VERSION ""

NS_ :

BS_:
BU_: ME SC01 BMS01 BMS PT
BO_ 2005 BMS22_DebugCMB: 8 BMS22
 SG_ cmbMultiplexor_BMS22 M : 7|8@0+ (1,0) [0|0] ""  PT
 SG_ moduleTemperature01_BMS22 m1 : 15|8@0+ (1,-40) [-40|200] "C"  PT
 SG_ brickVoltage001_BMS22 m1 : 23|16@0+ (0.0001,0) [0|6.5] "V"  PT
 SG_ brickVoltage002_BMS22 m1 : 39|16@0+ (0.0001,0) [0|6.5] "V"  PT
 SG_ brickVoltage003_BMS22 m1 : 55|16@0+ (0.0001,0) [0|6.5] "V"  PT
 SG_ moduleTemperature02_BMS22 m2 : 15|8@0+ (1,-40) [-40|200] "C"  PT
 SG_ brickVoltage004_BMS22 m2 : 23|16@0+ (0.0001,0) [0|6.5] "V"  PT
 SG_ brickVoltage005_BMS22 m2 : 39|16@0+ (0.0001,0) [0|6.5] "V"  PT
 SG_ brickVoltage006_BMS22 m2 : 55|16@0+ (0.0001,0) [0|6.5] "V"  PT
 SG_ moduleTemperature03_BMS22 m3 : 15|8@0+ (1,-40) [-40|200] "C"  PT
 SG_ brickVoltage007_BMS22 m3 : 23|16@0+ (0.0001,0) [0|6.5] "V"  PT
 SG_ brickVoltage008_BMS22 m3 : 39|16@0+ (0.0001,0) [0|6.5] "V"  PT
 SG_ brickVoltage009_BMS22 m3 : 55|16@0+ (0.0001,0) [0|6.5] "V"  PT
 SG_ moduleTemperature04_BMS22 m4 : 15|8@0+ (1,-40) [-40|200] "C"  PT
 SG_ brickVoltage010_BMS22 m4 : 23|16@0+ (0.0001,0) [0|6.5] "V"  PT
 SG_ brickVoltage011_BMS22 m4 : 39|16@0+ (0.0001,0) [0|6.5] "V"  PT
 SG_ brickVoltage012_BMS22 m4 : 55|16@0+ (0.0001,0) [0|6.5] "V"  PT
 SG_ moduleTemperature05_BMS22 m5 : 15|8@0+ (1,-40) [-40|200] "C"  PT
 SG_ brickVoltage013_BMS22 m5 : 23|16@0+ (0.0001,0) [0|6.5] "V"  PT
 SG_ brickVoltage014_BMS22 m5 : 39|16@0+ (0.0001,0) [0|6.5] "V"  PT
 SG_ brickVoltage015_BMS22 m5 : 55|16@0+ (0.0001,0) [0|6.5] "V"  PT
 SG_ moduleTemperature06_BMS22 m6 : 15|8@0+ (1,-40) [-40|200] "C"  PT
 SG_ brickVoltage016_BMS22 m6 : 23|16@0+ (0.0001,0) [0|6.5] "V"  PT
 SG_ brickVoltage017_BMS22 m6 : 39|16@0+ (0.0001,0) [0|6.5] "V"  PT
 SG_ brickVoltage018_BMS22 m6 : 55|16@0+ (0.0001,0) [0|6.5] "V"  PT
 SG_ moduleTemperature07_BMS22 m7 : 15|8@0+ (1,-40) [-40|200] "C"  PT
 SG_ brickVoltage019_BMS22 m7 : 23|16@0+ (0.0001,0) [0|6.5] "V"  PT
 SG_ brickVoltage020_BMS22 m7 : 39|16@0+ (0.0001,0) [0|6.5] "V"  PT
 SG_ brickVoltage021_BMS22 m7 : 55|16@0+ (0.0001,0) [0|6.5] "V"  PT
 SG_ moduleTemperature08_BMS22 m8 : 15|8@0+ (1,-40) [-40|200] "C"  PT
 SG_ brickVoltage022_BMS22 m8 : 23|16@0+ (0.0001,0) [0|6.5] "V"  PT
 SG_ brickVoltage023_BMS22 m8 : 39|16@0+ (0.0001,0) [0|6.5] "V"  PT
 SG_ brickVoltage024_BMS22 m8 : 55|16@0+ (0.0001,0) [0|6.5] "V"  PT
 SG_ moduleTemperature09_BMS22 m9 : 15|8@0+ (1,-40) [-40|200] "C"  PT
 SG_ brickVoltage025_BMS22 m9 : 23|16@0+ (0.0001,0) [0|6.5] "V"  PT
 SG_ brickVoltage026_BMS22 m9 : 39|16@0+ (0.0001,0) [0|6.5] "V"  PT
 SG_ brickVoltage027_BMS22 m9 : 55|16@0+ (0.0001,0) [0|6.5] "V"  PT
 SG_ moduleTemperature10_BMS22 m10 : 15|8@0+ (1,-40) [-40|200] "C"  PT
 SG_ brickVoltage028_BMS22 m10 : 23|16@0+ (0.0001,0) [0|6.5] "V"  PT
 SG_ brickVoltage029_BMS22 m10 : 39|16@0+ (0.0001,0) [0|6.5] "V"  PT
 SG_ brickVoltage030_BMS22 m10 : 55|16@0+ (0.0001,0) [0|6.5] "V"  PT
 SG_ moduleTemperature11_BMS22 m11 : 15|8@0+ (1,-40) [-40|200] "C"  PT
 SG_ brickVoltage031_BMS22 m11 : 23|16@0+ (0.0001,0) [0|6.5] "V"  PT
 SG_ brickVoltage032_BMS22 m11 : 39|16@0+ (0.0001,0) [0|6.5] "V"  PT
 SG_ brickVoltage033_BMS22 m11 : 55|16@0+ (0.0001,0) [0|6.5] "V"  PT
 SG_ moduleTemperature12_BMS22 m12 : 15|8@0+ (1,-40) [-40|200] "C"  PT
 SG_ brickVoltage034_BMS22 m12 : 23|16@0+ (0.0001,0) [0|6.5] "V"  PT
 SG_ brickVoltage035_BMS22 m12 : 39|16@0+ (0.0001,0) [0|6.5] "V"  PT
 SG_ brickVoltage036_BMS22 m12 : 55|16@0+ (0.0001,0) [0|6.5] "V"  PT
 SG_ moduleTemperature13_BMS22 m13 : 15|8@0+ (1,-40) [-40|200] "C"  PT
 SG_ brickVoltage037_BMS22 m13 : 23|16@0+ (0.0001,0) [0|6.5] "V"  PT
 SG_ brickVoltage038_BMS22 m13 : 39|16@0+ (0.0001,0) [0|6.5] "V"  PT
 SG_ brickVoltage039_BMS22 m13 : 55|16@0+ (0.0001,0) [0|6.5] "V"  PT
 SG_ moduleTemperature14_BMS22 m14 : 15|8@0+ (1,-40) [-40|200] "C"  PT
 SG_ brickVoltage040_BMS22 m14 : 23|16@0+ (0.0001,0) [0|6.5] "V"  PT
 SG_ brickVoltage041_BMS22 m14 : 39|16@0+ (0.0001,0) [0|6.5] "V"  PT
 SG_ brickVoltage042_BMS22 m14 : 55|16@0+ (0.0001,0) [0|6.5] "V"  PT
 SG_ moduleTemperature15_BMS22 m15 : 15|8@0+ (1,-40) [-40|200] "C"  PT
 SG_ brickVoltage043_BMS22 m15 : 23|16@0+ (0.0001,0) [0|6.5] "V"  PT
 SG_ brickVoltage044_BMS22 m15 : 39|16@0+ (0.0001,0) [0|6.5] "V"  PT
 SG_ brickVoltage045_BMS22 m15 : 55|16@0+ (0.0001,0) [0|6.5] "V"  PT
 SG_ moduleTemperature16_BMS22 m16 : 15|8@0+ (1,-40) [-40|200] "C"  PT
 SG_ brickVoltage046_BMS22 m16 : 23|16@0+ (0.0001,0) [0|6.5] "V"  PT
 SG_ brickVoltage047_BMS22 m16 : 39|16@0+ (0.0001,0) [0|6.5] "V"  PT
 SG_ brickVoltage048_BMS22 m16 : 55|16@0+ (0.0001,0) [0|6.5] "V"  PT
 SG_ moduleTemperature17_BMS22 m17 : 15|8@0+ (1,-40) [-40|200] "C"  PT
 SG_ brickVoltage049_BMS22 m17 : 23|16@0+ (0.0001,0) [0|6.5] "V"  PT
 SG_ brickVoltage050_BMS22 m17 : 39|16@0+ (0.0001,0) [0|6.5] "V"  PT
 SG_ brickVoltage051_BMS22 m17 : 55|16@0+ (0.0001,0) [0|6.5] "V"  PT
 SG_ moduleTemperature18_BMS22 m18 : 15|8@0+ (1,-40) [-40|200] "C"  PT
 SG_ brickVoltage052_BMS22 m18 : 23|16@0+ (0.0001,0) [0|6.5] "V"  PT
 SG_ brickVoltage053_BMS22 m18 : 39|16@0+ (0.0001,0) [0|6.5] "V"  PT
 SG_ brickVoltage054_BMS22 m18 : 55|16@0+ (0.0001,0) [0|6.5] "V"  PT
 SG_ moduleTemperature19_BMS22 m19 : 15|8@0+ (1,-40) [-40|200] "C"  PT
 SG_ brickVoltage055_BMS22 m19 : 23|16@0+ (0.0001,0) [0|6.5] "V"  PT
 SG_ brickVoltage056_BMS22 m19 : 39|16@0+ (0.0001,0) [0|6.5] "V"  PT
 SG_ brickVoltage057_BMS22 m19 : 55|16@0+ (0.0001,0) [0|6.5] "V"  PT
 SG_ moduleTemperature20_BMS22 m20 : 15|8@0+ (1,-40) [-40|200] "C"  PT
 SG_ brickVoltage058_BMS22 m20 : 23|16@0+ (0.0001,0) [0|6.5] "V"  PT
 SG_ brickVoltage059_BMS22 m20 : 39|16@0+ (0.0001,0) [0|6.5] "V"  PT
 SG_ brickVoltage060_BMS22 m20 : 55|16@0+ (0.0001,0) [0|6.5] "V"  PT
 SG_ moduleTemperature21_BMS22 m21 : 15|8@0+ (1,-40) [-40|200] "C"  PT
 SG_ brickVoltage061_BMS22 m21 : 23|16@0+ (0.0001,0) [0|6.5] "V"  PT
 SG_ brickVoltage062_BMS22 m21 : 39|16@0+ (0.0001,0) [0|6.5] "V"  PT
 SG_ brickVoltage063_BMS22 m21 : 55|16@0+ (0.0001,0) [0|6.5] "V"  PT
 SG_ moduleTemperature22_BMS22 m22 : 15|8@0+ (1,-40) [-40|200] "C"  PT
 SG_ brickVoltage064_BMS22 m22 : 23|16@0+ (0.0001,0) [0|6.5] "V"  PT
 SG_ brickVoltage065_BMS22 m22 : 39|16@0+ (0.0001,0) [0|6.5] "V"  PT
 SG_ brickVoltage066_BMS22 m22 : 55|16@0+ (0.0001,0) [0|6.5] "V"  PT
 SG_ moduleTemperature23_BMS22 m23 : 15|8@0+ (1,-40) [-40|200] "C"  PT
 SG_ brickVoltage067_BMS22 m23 : 23|16@0+ (0.0001,0) [0|6.5] "V"  PT
 SG_ brickVoltage068_BMS22 m23 : 39|16@0+ (0.0001,0) [0|6.5] "V"  PT
 SG_ brickVoltage069_BMS22 m23 : 55|16@0+ (0.0001,0) [0|6.5] "V"  PT
 SG_ moduleTemperature24_BMS22 m24 : 15|8@0+ (1,-40) [-40|200] "C"  PT
 SG_ brickVoltage070_BMS22 m24 : 23|16@0+ (0.0001,0) [0|6.5] "V"  PT
 SG_ brickVoltage071_BMS22 m24 : 39|16@0+ (0.0001,0) [0|6.5] "V"  PT
 SG_ brickVoltage072_BMS22 m24 : 55|16@0+ (0.0001,0) [0|6.5] "V"  PT
 SG_ moduleTemperature25_BMS22 m25 : 15|8@0+ (1,-40) [-40|200] "C"  PT
 SG_ brickVoltage073_BMS22 m25 : 23|16@0+ (0.0001,0) [0|6.5] "V"  PT
 SG_ brickVoltage074_BMS22 m25 : 39|16@0+ (0.0001,0) [0|6.5] "V"  PT
 SG_ brickVoltage075_BMS22 m25 : 55|16@0+ (0.0001,0) [0|6.5] "V"  PT
 SG_ moduleTemperature26_BMS22 m26 : 15|8@0+ (1,-40) [-40|200] "C"  PT
 SG_ brickVoltage076_BMS22 m26 : 23|16@0+ (0.0001,0) [0|6.5] "V"  PT
 SG_ brickVoltage077_BMS22 m26 : 39|16@0+ (0.0001,0) [0|6.5] "V"  PT
 SG_ brickVoltage078_BMS22 m26 : 55|16@0+ (0.0001,0) [0|6.5] "V"  PT
 SG_ moduleTemperature27_BMS22 m27 : 15|8@0+ (1,-40) [-40|200] "C"  PT
 SG_ brickVoltage079_BMS22 m27 : 23|16@0+ (0.0001,0) [0|6.5] "V"  PT
 SG_ brickVoltage080_BMS22 m27 : 39|16@0+ (0.0001,0) [0|6.5] "V"  PT
 SG_ brickVoltage081_BMS22 m27 : 55|16@0+ (0.0001,0) [0|6.5] "V"  PT
 SG_ moduleTemperature28_BMS22 m28 : 15|8@0+ (1,-40) [-40|200] "C"  PT
 SG_ brickVoltage082_BMS22 m28 : 23|16@0+ (0.0001,0) [0|6.5] "V"  PT
 SG_ brickVoltage083_BMS22 m28 : 39|16@0+ (0.0001,0) [0|6.5] "V"  PT
 SG_ brickVoltage084_BMS22 m28 : 55|16@0+ (0.0001,0) [0|6.5] "V"  PT
 SG_ moduleTemperature29_BMS22 m29 : 15|8@0+ (1,-40) [-40|200] "C"  PT
 SG_ brickVoltage085_BMS22 m29 : 23|16@0+ (0.0001,0) [0|6.5] "V"  PT
 SG_ brickVoltage086_BMS22 m29 : 39|16@0+ (0.0001,0) [0|6.5] "V"  PT
 SG_ brickVoltage087_BMS22 m29 : 55|16@0+ (0.0001,0) [0|6.5] "V"  PT
 SG_ moduleTemperature30_BMS22 m30 : 15|8@0+ (1,-40) [-40|200] "C"  PT
 SG_ brickVoltage088_BMS22 m30 : 23|16@0+ (0.0001,0) [0|6.5] "V"  PT
 SG_ brickVoltage089_BMS22 m30 : 39|16@0+ (0.0001,0) [0|6.5] "V"  PT
 SG_ brickVoltage090_BMS22 m30 : 55|16@0+ (0.0001,0) [0|6.5] "V"  PT
 SG_ moduleTemperature31_BMS22 m31 : 15|8@0+ (1,-40) [-40|200] "C"  PT
 SG_ brickVoltage091_BMS22 m31 : 23|16@0+ (0.0001,0) [0|6.5] "V"  PT
 SG_ brickVoltage092_BMS22 m31 : 39|16@0+ (0.0001,0) [0|6.5] "V"  PT
 SG_ brickVoltage093_BMS22 m31 : 55|16@0+ (0.0001,0) [0|6.5] "V"  PT
 SG_ moduleTemperature32_BMS22 m32 : 15|8@0+ (1,-40) [-40|200] "C"  PT
 SG_ brickVoltage094_BMS22 m32 : 23|16@0+ (0.0001,0) [0|6.5] "V"  PT
 SG_ brickVoltage095_BMS22 m32 : 39|16@0+ (0.0001,0) [0|6.5] "V"  PT
 SG_ brickVoltage096_BMS22 m32 : 55|16@0+ (0.0001,0) [0|6.5] "V"  PT
 SG_ brickVoltage097_BMS22 m33 : 23|16@0+ (0.0001,0) [0|6.5] "V"  PT
 SG_ brickVoltage098_BMS22 m33 : 39|16@0+ (0.0001,0) [0|6.5] "V"  PT
 SG_ brickVoltage099_BMS22 m33 : 55|16@0+ (0.0001,0) [0|6.5] "V"  PT
 SG_ brickVoltage100_BMS22 m34 : 23|16@0+ (0.0001,0) [0|6.5] "V"  PT
 SG_ brickVoltage101_BMS22 m34 : 39|16@0+ (0.0001,0) [0|6.5] "V"  PT
 SG_ brickVoltage102_BMS22 m34 : 55|16@0+ (0.0001,0) [0|6.5] "V"  PT
 SG_ brickVoltage103_BMS22 m35 : 23|16@0+ (0.0001,0) [0|6.5] "V"  PT
 SG_ brickVoltage104_BMS22 m35 : 39|16@0+ (0.0001,0) [0|6.5] "V"  PT
 SG_ brickVoltage105_BMS22 m35 : 55|16@0+ (0.0001,0) [0|6.5] "V"  PT
 SG_ brickVoltage106_BMS22 m36 : 23|16@0+ (0.0001,0) [0|6.5] "V"  PT
 SG_ brickVoltage107_BMS22 m36 : 39|16@0+ (0.0001,0) [0|6.5] "V"  PT
 SG_ brickVoltage108_BMS22 m36 : 55|16@0+ (0.0001,0) [0|6.5] "V"  PT
 SG_ brickVoltage109_BMS22 m37 : 23|16@0+ (0.0001,0) [0|6.5] "V"  PT
 SG_ brickVoltage110_BMS22 m37 : 39|16@0+ (0.0001,0) [0|6.5] "V"  PT
 SG_ brickVoltage111_BMS22 m37 : 55|16@0+ (0.0001,0) [0|6.5] "V"  PT
 SG_ brickVoltage112_BMS22 m38 : 23|16@0+ (0.0001,0) [0|6.5] "V"  PT
 SG_ brickVoltage113_BMS22 m38 : 39|16@0+ (0.0001,0) [0|6.5] "V"  PT
 SG_ brickVoltage114_BMS22 m38 : 55|16@0+ (0.0001,0) [0|6.5] "V"  PT
 SG_ brickVoltage115_BMS22 m39 : 23|16@0+ (0.0001,0) [0|6.5] "V"  PT
 SG_ brickVoltage116_BMS22 m39 : 39|16@0+ (0.0001,0) [0|6.5] "V"  PT
 SG_ brickVoltage117_BMS22 m39 : 55|16@0+ (0.0001,0) [0|6.5] "V"  PT
 SG_ brickVoltage118_BMS22 m40 : 23|16@0+ (0.0001,0) [0|6.5] "V"  PT
 SG_ brickVoltage119_BMS22 m40 : 39|16@0+ (0.0001,0) [0|6.5] "V"  PT
 SG_ brickVoltage120_BMS22 m40 : 55|16@0+ (0.0001,0) [0|6.5] "V"  PT
 SG_ brickVoltage121_BMS22 m41 : 23|16@0+ (0.0001,0) [0|6.5] "V"  PT
 SG_ brickVoltage122_BMS22 m41 : 39|16@0+ (0.0001,0) [0|6.5] "V"  PT
 SG_ brickVoltage123_BMS22 m41 : 55|16@0+ (0.0001,0) [0|6.5] "V"  PT
 SG_ brickVoltage124_BMS22 m42 : 23|16@0+ (0.0001,0) [0|6.5] "V"  PT
 SG_ brickVoltage125_BMS22 m42 : 39|16@0+ (0.0001,0) [0|6.5] "V"  PT
 SG_ brickVoltage126_BMS22 m42 : 55|16@0+ (0.0001,0) [0|6.5] "V"  PT
 SG_ brickVoltage127_BMS22 m43 : 23|16@0+ (0.0001,0) [0|6.5] "V"  PT
 SG_ brickVoltage128_BMS22 m43 : 39|16@0+ (0.0001,0) [0|6.5] "V"  PT
 SG_ brickVoltage129_BMS22 m43 : 55|16@0+ (0.0001,0) [0|6.5] "V"  PT
 SG_ brickVoltage130_BMS22 m44 : 23|16@0+ (0.0001,0) [0|6.5] "V"  PT
 SG_ brickVoltage131_BMS22 m44 : 39|16@0+ (0.0001,0) [0|6.5] "V"  PT
 SG_ brickVoltage132_BMS22 m44 : 55|16@0+ (0.0001,0) [0|6.5] "V"  PT
 SG_ brickVoltage133_BMS22 m45 : 23|16@0+ (0.0001,0) [0|6.5] "V"  PT
 SG_ brickVoltage134_BMS22 m45 : 39|16@0+ (0.0001,0) [0|6.5] "V"  PT
 SG_ brickVoltage135_BMS22 m45 : 55|16@0+ (0.0001,0) [0|6.5] "V"  PT
 SG_ brickVoltage136_BMS22 m46 : 23|16@0+ (0.0001,0) [0|6.5] "V"  PT
 SG_ brickVoltage137_BMS22 m46 : 39|16@0+ (0.0001,0) [0|6.5] "V"  PT
 SG_ brickVoltage138_BMS22 m46 : 55|16@0+ (0.0001,0) [0|6.5] "V"  PT
 SG_ brickVoltage139_BMS22 m47 : 23|16@0+ (0.0001,0) [0|6.5] "V"  PT
 SG_ brickVoltage140_BMS22 m47 : 39|16@0+ (0.0001,0) [0|6.5] "V"  PT
 SG_ brickVoltage141_BMS22 m47 : 55|16@0+ (0.0001,0) [0|6.5] "V"  PT
 SG_ brickVoltage142_BMS22 m48 : 23|16@0+ (0.0001,0) [0|6.5] "V"  PT
 SG_ brickVoltage143_BMS22 m48 : 39|16@0+ (0.0001,0) [0|6.5] "V"  PT
 SG_ brickVoltage144_BMS22 m48 : 55|16@0+ (0.0001,0) [0|6.5] "V"  PT
 SG_ brickVoltage145_BMS22 m49 : 23|16@0+ (0.0001,0) [0|6.5] "V"  PT
 SG_ brickVoltage146_BMS22 m49 : 39|16@0+ (0.0001,0) [0|6.5] "V"  PT
 SG_ brickVoltage147_BMS22 m49 : 55|16@0+ (0.0001,0) [0|6.5] "V"  PT
 SG_ brickVoltage148_BMS22 m50 : 23|16@0+ (0.0001,0) [0|6.5] "V"  PT
 SG_ brickVoltage149_BMS22 m50 : 39|16@0+ (0.0001,0) [0|6.5] "V"  PT
 SG_ brickVoltage150_BMS22 m50 : 55|16@0+ (0.0001,0) [0|6.5] "V"  PT
 SG_ brickVoltage151_BMS22 m51 : 23|16@0+ (0.0001,0) [0|6.5] "V"  PT
 SG_ brickVoltage152_BMS22 m51 : 39|16@0+ (0.0001,0) [0|6.5] "V"  PT
 SG_ brickVoltage153_BMS22 m51 : 55|16@0+ (0.0001,0) [0|6.5] "V"  PT
 SG_ brickVoltage154_BMS22 m52 : 23|16@0+ (0.0001,0) [0|6.5] "V"  PT
 SG_ brickVoltage155_BMS22 m52 : 39|16@0+ (0.0001,0) [0|6.5] "V"  PT
 SG_ brickVoltage156_BMS22 m52 : 55|16@0+ (0.0001,0) [0|6.5] "V"  PT
 SG_ brickVoltage157_BMS22 m53 : 23|16@0+ (0.0001,0) [0|6.5] "V"  PT
 SG_ brickVoltage158_BMS22 m53 : 39|16@0+ (0.0001,0) [0|6.5] "V"  PT
 SG_ brickVoltage159_BMS22 m53 : 55|16@0+ (0.0001,0) [0|6.5] "V"  PT
 SG_ brickVoltage160_BMS22 m54 : 23|16@0+ (0.0001,0) [0|6.5] "V"  PT
 SG_ brickVoltage161_BMS22 m54 : 39|16@0+ (0.0001,0) [0|6.5] "V"  PT
 SG_ brickVoltage162_BMS22 m54 : 55|16@0+ (0.0001,0) [0|6.5] "V"  PT
 SG_ brickVoltage163_BMS22 m55 : 23|16@0+ (0.0001,0) [0|6.5] "V"  PT
 SG_ brickVoltage164_BMS22 m55 : 39|16@0+ (0.0001,0) [0|6.5] "V"  PT
 SG_ brickVoltage165_BMS22 m55 : 55|16@0+ (0.0001,0) [0|6.5] "V"  PT
 SG_ brickVoltage166_BMS22 m56 : 23|16@0+ (0.0001,0) [0|6.5] "V"  PT
 SG_ brickVoltage167_BMS22 m56 : 39|16@0+ (0.0001,0) [0|6.5] "V"  PT
 SG_ brickVoltage168_BMS22 m56 : 55|16@0+ (0.0001,0) [0|6.5] "V"  PT
 SG_ brickVoltage169_BMS22 m57 : 23|16@0+ (0.0001,0) [0|6.5] "V"  PT
 SG_ brickVoltage170_BMS22 m57 : 39|16@0+ (0.0001,0) [0|6.5] "V"  PT
 SG_ brickVoltage171_BMS22 m57 : 55|16@0+ (0.0001,0) [0|6.5] "V"  PT
 SG_ brickVoltage172_BMS22 m58 : 23|16@0+ (0.0001,0) [0|6.5] "V"  PT
 SG_ brickVoltage173_BMS22 m58 : 39|16@0+ (0.0001,0) [0|6.5] "V"  PT
 SG_ brickVoltage174_BMS22 m58 : 55|16@0+ (0.0001,0) [0|6.5] "V"  PT
 SG_ brickVoltage175_BMS22 m59 : 23|16@0+ (0.0001,0) [0|6.5] "V"  PT
 SG_ brickVoltage176_BMS22 m59 : 39|16@0+ (0.0001,0) [0|6.5] "V"  PT
 SG_ brickVoltage177_BMS22 m59 : 55|16@0+ (0.0001,0) [0|6.5] "V"  PT
 SG_ brickVoltage178_BMS22 m60 : 23|16@0+ (0.0001,0) [0|6.5] "V"  PT
 SG_ brickVoltage179_BMS22 m60 : 39|16@0+ (0.0001,0) [0|6.5] "V"  PT
 SG_ brickVoltage180_BMS22 m60 : 55|16@0+ (0.0001,0) [0|6.5] "V"  PT
 SG_ brickVoltage181_BMS22 m61 : 23|16@0+ (0.0001,0) [0|6.5] "V"  PT
 SG_ brickVoltage182_BMS22 m61 : 39|16@0+ (0.0001,0) [0|6.5] "V"  PT
 SG_ brickVoltage183_BMS22 m61 : 55|16@0+ (0.0001,0) [0|6.5] "V"  PT
 SG_ brickVoltage184_BMS22 m62 : 23|16@0+ (0.0001,0) [0|6.5] "V"  PT
 SG_ brickVoltage185_BMS22 m62 : 39|16@0+ (0.0001,0) [0|6.5] "V"  PT
 SG_ brickVoltage186_BMS22 m62 : 55|16@0+ (0.0001,0) [0|6.5] "V"  PT
 SG_ brickVoltage187_BMS22 m63 : 23|16@0+ (0.0001,0) [0|6.5] "V"  PT
 SG_ brickVoltage188_BMS22 m63 : 39|16@0+ (0.0001,0) [0|6.5] "V"  PT
 SG_ brickVoltage189_BMS22 m63 : 55|16@0+ (0.0001,0) [0|6.5] "V"  PT
 SG_ brickVoltage190_BMS22 m64 : 23|16@0+ (0.0001,0) [0|6.5] "V"  PT
 SG_ brickVoltage191_BMS22 m64 : 39|16@0+ (0.0001,0) [0|6.5] "V"  PT
 SG_ brickVoltage192_BMS22 m64 : 55|16@0+ (0.0001,0) [0|6.5] "V"  PT
 SG_ brickVoltage193_BMS22 m65 : 23|16@0+ (0.0001,0) [0|6.5] "V"  PT
 SG_ brickVoltage194_BMS22 m65 : 39|16@0+ (0.0001,0) [0|6.5] "V"  PT
 SG_ brickVoltage195_BMS22 m65 : 55|16@0+ (0.0001,0) [0|6.5] "V"  PT
 SG_ brickVoltage196_BMS22 m66 : 23|16@0+ (0.0001,0) [0|6.5] "V"  PT
 SG_ brickVoltage197_BMS22 m66 : 39|16@0+ (0.0001,0) [0|6.5] "V"  PT
 SG_ brickVoltage198_BMS22 m66 : 55|16@0+ (0.0001,0) [0|6.5] "V"  PT
 SG_ brickVoltage199_BMS22 m67 : 23|16@0+ (0.0001,0) [0|6.5] "V"  PT
 SG_ brickVoltage200_BMS22 m67 : 39|16@0+ (0.0001,0) [0|6.5] "V"  PT
 SG_ brickVoltage201_BMS22 m67 : 55|16@0+ (0.0001,0) [0|6.5] "V"  PT
 SG_ brickVoltage202_BMS22 m68 : 23|16@0+ (0.0001,0) [0|6.5] "V"  PT
 SG_ brickVoltage203_BMS22 m68 : 39|16@0+ (0.0001,0) [0|6.5] "V"  PT
 SG_ brickVoltage204_BMS22 m68 : 55|16@0+ (0.0001,0) [0|6.5] "V"  PT
 SG_ brickVoltage205_BMS22 m69 : 23|16@0+ (0.0001,0) [0|6.5] "V"  PT
 SG_ brickVoltage206_BMS22 m69 : 39|16@0+ (0.0001,0) [0|6.5] "V"  PT
 SG_ brickVoltage207_BMS22 m69 : 55|16@0+ (0.0001,0) [0|6.5] "V"  PT
 SG_ brickVoltage208_BMS22 m70 : 23|16@0+ (0.0001,0) [0|6.5] "V"  PT
 SG_ brickVoltage209_BMS22 m70 : 39|16@0+ (0.0001,0) [0|6.5] "V"  PT
 SG_ brickVoltage210_BMS22 m70 : 55|16@0+ (0.0001,0) [0|6.5] "V"  PT
 SG_ brickVoltage211_BMS22 m71 : 23|16@0+ (0.0001,0) [0|6.5] "V"  PT
 SG_ brickVoltage212_BMS22 m71 : 39|16@0+ (0.0001,0) [0|6.5] "V"  PT
 SG_ brickVoltage213_BMS22 m71 : 55|16@0+ (0.0001,0) [0|6.5] "V"  PT
 SG_ brickVoltage214_BMS22 m72 : 23|16@0+ (0.0001,0) [0|6.5] "V"  PT
 SG_ brickVoltage215_BMS22 m72 : 39|16@0+ (0.0001,0) [0|6.5] "V"  PT
 SG_ brickVoltage216_BMS22 m72 : 55|16@0+ (0.0001,0) [0|6.5] "V"  PT
 SG_ brickVoltage217_BMS22 m73 : 23|16@0+ (0.0001,0) [0|6.5] "V"  PT
 SG_ brickVoltage218_BMS22 m73 : 39|16@0+ (0.0001,0) [0|6.5] "V"  PT
 SG_ brickVoltage219_BMS22 m73 : 55|16@0+ (0.0001,0) [0|6.5] "V"  PT
 SG_ brickVoltage220_BMS22 m74 : 23|16@0+ (0.0001,0) [0|6.5] "V"  PT
 SG_ brickVoltage221_BMS22 m74 : 39|16@0+ (0.0001,0) [0|6.5] "V"  PT
 SG_ brickVoltage222_BMS22 m74 : 55|16@0+ (0.0001,0) [0|6.5] "V"  PT
 SG_ brickVoltage223_BMS22 m75 : 23|16@0+ (0.0001,0) [0|6.5] "V"  PT
 SG_ brickVoltage224_BMS22 m75 : 39|16@0+ (0.0001,0) [0|6.5] "V"  PT
 SG_ brickVoltage225_BMS22 m75 : 55|16@0+ (0.0001,0) [0|6.5] "V"  PT
 SG_ brickVoltage226_BMS22 m76 : 23|16@0+ (0.0001,0) [0|6.5] "V"  PT
 SG_ brickVoltage227_BMS22 m76 : 39|16@0+ (0.0001,0) [0|6.5] "V"  PT
 SG_ brickVoltage228_BMS22 m76 : 55|16@0+ (0.0001,0) [0|6.5] "V"  PT
 SG_ brickVoltage229_BMS22 m77 : 23|16@0+ (0.0001,0) [0|6.5] "V"  PT
 SG_ brickVoltage230_BMS22 m77 : 39|16@0+ (0.0001,0) [0|6.5] "V"  PT
 SG_ brickVoltage231_BMS22 m77 : 55|16@0+ (0.0001,0) [0|6.5] "V"  PT
 SG_ brickVoltage232_BMS22 m78 : 23|16@0+ (0.0001,0) [0|6.5] "V"  PT
 SG_ brickVoltage233_BMS22 m78 : 39|16@0+ (0.0001,0) [0|6.5] "V"  PT
 SG_ brickVoltage234_BMS22 m78 : 55|16@0+ (0.0001,0) [0|6.5] "V"  PT
 SG_ brickVoltage235_BMS22 m79 : 23|16@0+ (0.0001,0) [0|6.5] "V"  PT
 SG_ brickVoltage236_BMS22 m79 : 39|16@0+ (0.0001,0) [0|6.5] "V"  PT
 SG_ brickVoltage237_BMS22 m79 : 55|16@0+ (0.0001,0) [0|6.5] "V"  PT
 SG_ brickVoltage238_BMS22 m80 : 23|16@0+ (0.0001,0) [0|6.5] "V"  PT
 SG_ brickVoltage239_BMS22 m80 : 39|16@0+ (0.0001,0) [0|6.5] "V"  PT
 SG_ brickVoltage240_BMS22 m80 : 55|16@0+ (0.0001,0) [0|6.5] "V"  PT
 SG_ brickVoltage241_BMS22 m81 : 23|16@0+ (0.0001,0) [0|6.5] "V"  PT
 SG_ brickVoltage242_BMS22 m81 : 39|16@0+ (0.0001,0) [0|6.5] "V"  PT
 SG_ brickVoltage243_BMS22 m81 : 55|16@0+ (0.0001,0) [0|6.5] "V"  PT
 SG_ brickVoltage244_BMS22 m82 : 23|16@0+ (0.0001,0) [0|6.5] "V"  PT
 SG_ brickVoltage245_BMS22 m82 : 39|16@0+ (0.0001,0) [0|6.5] "V"  PT
 SG_ brickVoltage246_BMS22 m82 : 55|16@0+ (0.0001,0) [0|6.5] "V"  PT
 SG_ brickVoltage247_BMS22 m83 : 23|16@0+ (0.0001,0) [0|6.5] "V"  PT
 SG_ brickVoltage248_BMS22 m83 : 39|16@0+ (0.0001,0) [0|6.5] "V"  PT
 SG_ brickVoltage249_BMS22 m83 : 55|16@0+ (0.0001,0) [0|6.5] "V"  PT
 SG_ brickVoltage250_BMS22 m84 : 23|16@0+ (0.0001,0) [0|6.5] "V"  PT
 SG_ brickVoltage251_BMS22 m84 : 39|16@0+ (0.0001,0) [0|6.5] "V"  PT
 SG_ brickVoltage252_BMS22 m84 : 55|16@0+ (0.0001,0) [0|6.5] "V"  PT
 SG_ brickVoltage253_BMS22 m85 : 23|16@0+ (0.0001,0) [0|6.5] "V"  PT
 SG_ brickVoltage254_BMS22 m85 : 39|16@0+ (0.0001,0) [0|6.5] "V"  PT
 SG_ brickVoltage255_BMS22 m85 : 55|16@0+ (0.0001,0) [0|6.5] "V"  PT
 SG_ brickVoltage256_BMS22 m86 : 23|16@0+ (0.0001,0) [0|6.5] "V"  PT
 SG_ brickVoltage257_BMS22 m86 : 39|16@0+ (0.0001,0) [0|6.5] "V"  PT
 SG_ brickVoltage258_BMS22 m86 : 55|16@0+ (0.0001,0) [0|6.5] "V"  PT
 SG_ brickVoltage259_BMS22 m87 : 23|16@0+ (0.0001,0) [0|6.5] "V"  PT
 SG_ brickVoltage260_BMS22 m87 : 39|16@0+ (0.0001,0) [0|6.5] "V"  PT
 SG_ brickVoltage261_BMS22 m87 : 55|16@0+ (0.0001,0) [0|6.5] "V"  PT
 SG_ brickVoltage262_BMS22 m88 : 23|16@0+ (0.0001,0) [0|6.5] "V"  PT
 SG_ brickVoltage263_BMS22 m88 : 39|16@0+ (0.0001,0) [0|6.5] "V"  PT
 SG_ brickVoltage264_BMS22 m88 : 55|16@0+ (0.0001,0) [0|6.5] "V"  PT
 SG_ brickVoltage265_BMS22 m89 : 23|16@0+ (0.0001,0) [0|6.5] "V"  PT
 SG_ brickVoltage266_BMS22 m89 : 39|16@0+ (0.0001,0) [0|6.5] "V"  PT
 SG_ brickVoltage267_BMS22 m89 : 55|16@0+ (0.0001,0) [0|6.5] "V"  PT
 SG_ brickVoltage268_BMS22 m90 : 23|16@0+ (0.0001,0) [0|6.5] "V"  PT
 SG_ brickVoltage269_BMS22 m90 : 39|16@0+ (0.0001,0) [0|6.5] "V"  PT
 SG_ brickVoltage270_BMS22 m90 : 55|16@0+ (0.0001,0) [0|6.5] "V"  PT
 SG_ brickVoltage271_BMS22 m91 : 23|16@0+ (0.0001,0) [0|6.5] "V"  PT
 SG_ brickVoltage272_BMS22 m91 : 39|16@0+ (0.0001,0) [0|6.5] "V"  PT
 SG_ brickVoltage273_BMS22 m91 : 55|16@0+ (0.0001,0) [0|6.5] "V"  PT
 SG_ brickVoltage274_BMS22 m92 : 23|16@0+ (0.0001,0) [0|6.5] "V"  PT
 SG_ brickVoltage275_BMS22 m92 : 39|16@0+ (0.0001,0) [0|6.5] "V"  PT
 SG_ brickVoltage276_BMS22 m92 : 55|16@0+ (0.0001,0) [0|6.5] "V"  PT
 SG_ brickVoltage277_BMS22 m93 : 23|16@0+ (0.0001,0) [0|6.5] "V"  PT
 SG_ brickVoltage278_BMS22 m93 : 39|16@0+ (0.0001,0) [0|6.5] "V"  PT
 SG_ brickVoltage279_BMS22 m93 : 55|16@0+ (0.0001,0) [0|6.5] "V"  PT
 SG_ brickVoltage280_BMS22 m94 : 23|16@0+ (0.0001,0) [0|6.5] "V"  PT
 SG_ brickVoltage281_BMS22 m94 : 39|16@0+ (0.0001,0) [0|6.5] "V"  PT
 SG_ brickVoltage282_BMS22 m94 : 55|16@0+ (0.0001,0) [0|6.5] "V"  PT
 SG_ brickVoltage283_BMS22 m95 : 23|16@0+ (0.0001,0) [0|6.5] "V"  PT
 SG_ brickVoltage284_BMS22 m95 : 39|16@0+ (0.0001,0) [0|6.5] "V"  PT
 SG_ brickVoltage285_BMS22 m95 : 55|16@0+ (0.0001,0) [0|6.5] "V"  PT
 SG_ brickVoltage286_BMS22 m96 : 23|16@0+ (0.0001,0) [0|6.5] "V"  PT
 SG_ brickVoltage287_BMS22 m96 : 39|16@0+ (0.0001,0) [0|6.5] "V"  PT
 SG_ brickVoltage288_BMS22 m96 : 55|16@0+ (0.0001,0) [0|6.5] "V"  PT
 SG_ brickVoltage289_BMS22 m97 : 23|16@0+ (0.0001,0) [0|6.5] "V"  PT
 SG_ brickVoltage290_BMS22 m97 : 39|16@0+ (0.0001,0) [0|6.5] "V"  PT
 SG_ brickVoltage291_BMS22 m97 : 55|16@0+ (0.0001,0) [0|6.5] "V"  PT
 SG_ brickVoltage292_BMS22 m98 : 23|16@0+ (0.0001,0) [0|6.5] "V"  PT
 SG_ brickVoltage293_BMS22 m98 : 39|16@0+ (0.0001,0) [0|6.5] "V"  PT
 SG_ brickVoltage294_BMS22 m98 : 55|16@0+ (0.0001,0) [0|6.5] "V"  PT
 SG_ brickVoltage295_BMS22 m99 : 23|16@0+ (0.0001,0) [0|6.5] "V"  PT
 SG_ brickVoltage296_BMS22 m99 : 39|16@0+ (0.0001,0) [0|6.5] "V"  PT
 SG_ brickVoltage297_BMS22 m99 : 55|16@0+ (0.0001,0) [0|6.5] "V"  PT
 SG_ brickVoltage298_BMS22 m100 : 23|16@0+ (0.0001,0) [0|6.5] "V"  PT
 SG_ brickVoltage299_BMS22 m100 : 39|16@0+ (0.0001,0) [0|6.5] "V"  PT
 SG_ brickVoltage300_BMS22 m100 : 55|16@0+ (0.0001,0) [0|6.5] "V"  PT
 SG_ moduleTemperature33_BMS22 m33 : 15|8@0+ (1,-40) [-40|200] "C"  PT
 SG_ moduleTemperature34_BMS22 m34 : 15|8@0+ (1,-40) [-40|200] "C"  PT
 SG_ moduleTemperature35_BMS22 m35 : 15|8@0+ (1,-40) [-40|200] "C"  PT
 SG_ moduleTemperature36_BMS22 m36 : 15|8@0+ (1,-40) [-40|200] "C"  PT
 SG_ moduleTemperature37_BMS22 m37 : 15|8@0+ (1,-40) [-40|200] "C"  PT
 SG_ moduleTemperature38_BMS22 m38 : 15|8@0+ (1,-40) [-40|200] "C"  PT
 SG_ moduleTemperature39_BMS22 m39 : 15|8@0+ (1,-40) [-40|200] "C"  PT
 SG_ moduleTemperature40_BMS22 m40 : 15|8@0+ (1,-40) [-40|200] "C"  PT
 SG_ moduleTemperature41_BMS22 m41 : 15|8@0+ (1,-40) [-40|200] "C"  PT
 SG_ moduleTemperature42_BMS22 m42 : 15|8@0+ (1,-40) [-40|200] "C"  PT
 SG_ moduleTemperature43_BMS22 m43 : 15|8@0+ (1,-40) [-40|200] "C"  PT
 SG_ moduleTemperature44_BMS22 m44 : 15|8@0+ (1,-40) [-40|200] "C"  PT
 SG_ moduleTemperature45_BMS22 m45 : 15|8@0+ (1,-40) [-40|200] "C"  PT
 SG_ moduleTemperature46_BMS22 m46 : 15|8@0+ (1,-40) [-40|200] "C"  PT
 SG_ moduleTemperature47_BMS22 m47 : 15|8@0+ (1,-40) [-40|200] "C"  PT
 SG_ moduleTemperature48_BMS22 m48 : 15|8@0+ (1,-40) [-40|200] "C"  PT
 SG_ moduleTemperature49_BMS22 m49 : 15|8@0+ (1,-40) [-40|200] "C"  PT
 SG_ moduleTemperature50_BMS22 m50 : 15|8@0+ (1,-40) [-40|200] "C"  PT
 SG_ moduleTemperature51_BMS22 m51 : 15|8@0+ (1,-40) [-40|200] "C"  PT
 SG_ moduleTemperature52_BMS22 m52 : 15|8@0+ (1,-40) [-40|200] "C"  PT
 SG_ moduleTemperature53_BMS22 m53 : 15|8@0+ (1,-40) [-40|200] "C"  PT
 SG_ moduleTemperature54_BMS22 m54 : 15|8@0+ (1,-40) [-40|200] "C"  PT
 SG_ moduleTemperature55_BMS22 m55 : 15|8@0+ (1,-40) [-40|200] "C"  PT
 SG_ moduleTemperature56_BMS22 m56 : 15|8@0+ (1,-40) [-40|200] "C"  PT
 SG_ moduleTemperature57_BMS22 m57 : 15|8@0+ (1,-40) [-40|200] "C"  PT
 SG_ moduleTemperature58_BMS22 m58 : 15|8@0+ (1,-40) [-40|200] "C"  PT
 SG_ moduleTemperature59_BMS22 m59 : 15|8@0+ (1,-40) [-40|200] "C"  PT
 SG_ moduleTemperature60_BMS22 m60 : 15|8@0+ (1,-40) [-40|200] "C"  PT
 SG_ moduleTemperature61_BMS22 m61 : 15|8@0+ (1,-40) [-40|200] "C"  PT
 SG_ moduleTemperature62_BMS22 m62 : 15|8@0+ (1,-40) [-40|200] "C"  PT
 SG_ moduleTemperature63_BMS22 m63 : 15|8@0+ (1,-40) [-40|200] "C"  PT
 SG_ moduleTemperature64_BMS22 m64 : 15|8@0+ (1,-40) [-40|200] "C"  PT
 SG_ moduleTemperature65_BMS22 m65 : 15|8@0+ (1,-40) [-40|200] "C"  PT
 SG_ moduleTemperature66_BMS22 m66 : 15|8@0+ (1,-40) [-40|200] "C"  PT
 SG_ moduleTemperature67_BMS22 m67 : 15|8@0+ (1,-40) [-40|200] "C"  PT
 SG_ moduleTemperature68_BMS22 m68 : 15|8@0+ (1,-40) [-40|200] "C"  PT
 SG_ moduleTemperature69_BMS22 m69 : 15|8@0+ (1,-40) [-40|200] "C"  PT
 SG_ moduleTemperature70_BMS22 m70 : 15|8@0+ (1,-40) [-40|200] "C"  PT
 SG_ moduleTemperature71_BMS22 m71 : 15|8@0+ (1,-40) [-40|200] "C"  PT
 SG_ moduleTemperature72_BMS22 m72 : 15|8@0+ (1,-40) [-40|200] "C"  PT
 SG_ moduleTemperature73_BMS22 m73 : 15|8@0+ (1,-40) [-40|200] "C"  PT
 SG_ moduleTemperature74_BMS22 m74 : 15|8@0+ (1,-40) [-40|200] "C"  PT
 SG_ moduleTemperature75_BMS22 m75 : 15|8@0+ (1,-40) [-40|200] "C"  PT
 SG_ moduleTemperature76_BMS22 m76 : 15|8@0+ (1,-40) [-40|200] "C"  PT
 SG_ moduleTemperature77_BMS22 m77 : 15|8@0+ (1,-40) [-40|200] "C"  PT
 SG_ moduleTemperature78_BMS22 m78 : 15|8@0+ (1,-40) [-40|200] "C"  PT
 SG_ moduleTemperature79_BMS22 m79 : 15|8@0+ (1,-40) [-40|200] "C"  PT
 SG_ moduleTemperature80_BMS22 m80 : 15|8@0+ (1,-40) [-40|200] "C"  PT
 SG_ moduleTemperature81_BMS22 m81 : 15|8@0+ (1,-40) [-40|200] "C"  PT
 SG_ moduleTemperature82_BMS22 m82 : 15|8@0+ (1,-40) [-40|200] "C"  PT
 SG_ moduleTemperature83_BMS22 m83 : 15|8@0+ (1,-40) [-40|200] "C"  PT
 SG_ moduleTemperature84_BMS22 m84 : 15|8@0+ (1,-40) [-40|200] "C"  PT
 SG_ moduleTemperature85_BMS22 m85 : 15|8@0+ (1,-40) [-40|200] "C"  PT
 SG_ moduleTemperature86_BMS22 m86 : 15|8@0+ (1,-40) [-40|200] "C"  PT
 SG_ moduleTemperature87_BMS22 m87 : 15|8@0+ (1,-40) [-40|200] "C"  PT
 SG_ moduleTemperature88_BMS22 m88 : 15|8@0+ (1,-40) [-40|200] "C"  PT
 SG_ moduleTemperature89_BMS22 m89 : 15|8@0+ (1,-40) [-40|200] "C"  PT
 SG_ moduleTemperature90_BMS22 m90 : 15|8@0+ (1,-40) [-40|200] "C"  PT
 SG_ moduleTemperature91_BMS22 m91 : 15|8@0+ (1,-40) [-40|200] "C"  PT
 SG_ moduleTemperature92_BMS22 m92 : 15|8@0+ (1,-40) [-40|200] "C"  PT
 SG_ moduleTemperature93_BMS22 m93 : 15|8@0+ (1,-40) [-40|200] "C"  PT
 SG_ moduleTemperature94_BMS22 m94 : 15|8@0+ (1,-40) [-40|200] "C"  PT
 SG_ moduleTemperature95_BMS22 m95 : 15|8@0+ (1,-40) [-40|200] "C"  PT
 SG_ moduleTemperature96_BMS22 m96 : 15|8@0+ (1,-40) [-40|200] "C"  PT
 SG_ moduleTemperature97_BMS22 m97 : 15|8@0+ (1,-40) [-40|200] "C"  PT
 SG_ moduleTemperature98_BMS22 m98 : 15|8@0+ (1,-40) [-40|200] "C"  PT
 SG_ moduleTemperature99_BMS22 m99 : 15|8@0+ (1,-40) [-40|200] "C"  PT
 SG_ moduleTemperature100_BMS22 m100 : 15|8@0+ (1,-40) [-40|200] "C"  PT
 SG_ moduleTemperature101_BMS22 m101 : 15|8@0+ (1,-40) [-40|200] "C"  PT
 SG_ moduleTemperature102_BMS22 m102 : 15|8@0+ (1,-40) [-40|200] "C"  PT
 SG_ moduleTemperature103_BMS22 m103 : 15|8@0+ (1,-40) [-40|200] "C"  PT
 SG_ moduleTemperature104_BMS22 m104 : 15|8@0+ (1,-40) [-40|200] "C"  PT
 SG_ moduleTemperature105_BMS22 m105 : 15|8@0+ (1,-40) [-40|200] "C"  PT
 SG_ moduleTemperature106_BMS22 m106 : 15|8@0+ (1,-40) [-40|200] "C"  PT
 SG_ moduleTemperature107_BMS22 m107 : 15|8@0+ (1,-40) [-40|200] "C"  PT
 SG_ moduleTemperature108_BMS22 m108 : 15|8@0+ (1,-40) [-40|200] "C"  PT
 SG_ moduleTemperature109_BMS22 m109 : 15|8@0+ (1,-40) [-40|200] "C"  PT
 SG_ moduleTemperature110_BMS22 m110 : 15|8@0+ (1,-40) [-40|200] "C"  PT
 SG_ moduleTemperature111_BMS22 m111 : 15|8@0+ (1,-40) [-40|200] "C"  PT
 SG_ moduleTemperature112_BMS22 m112 : 15|8@0+ (1,-40) [-40|200] "C"  PT
 SG_ moduleTemperature113_BMS22 m113 : 15|8@0+ (1,-40) [-40|200] "C"  PT
 SG_ moduleTemperature114_BMS22 m114 : 15|8@0+ (1,-40) [-40|200] "C"  PT
 SG_ moduleTemperature115_BMS22 m115 : 15|8@0+ (1,-40) [-40|200] "C"  PT
 SG_ moduleTemperature116_BMS22 m116 : 15|8@0+ (1,-40) [-40|200] "C"  PT
 SG_ moduleTemperature117_BMS22 m117 : 15|8@0+ (1,-40) [-40|200] "C"  PT
 SG_ moduleTemperature118_BMS22 m118 : 15|8@0+ (1,-40) [-40|200] "C"  PT
 SG_ moduleTemperature119_BMS22 m119 : 15|8@0+ (1,-40) [-40|200] "C"  PT
 SG_ moduleTemperature120_BMS22 m120 : 15|8@0+ (1,-40) [-40|200] "C"  PT
 SG_ moduleTemperature121_BMS22 m121 : 15|8@0+ (1,-40) [-40|200] "C"  PT
 SG_ moduleTemperature122_BMS22 m122 : 15|8@0+ (1,-40) [-40|200] "C"  PT
 SG_ moduleTemperature123_BMS22 m123 : 15|8@0+ (1,-40) [-40|200] "C"  PT
 SG_ moduleTemperature124_BMS22 m124 : 15|8@0+ (1,-40) [-40|200] "C"  PT
 SG_ moduleTemperature125_BMS22 m125 : 15|8@0+ (1,-40) [-40|200] "C"  PT
 SG_ moduleTemperature126_BMS22 m126 : 15|8@0+ (1,-40) [-40|200] "C"  PT
 SG_ moduleTemperature127_BMS22 m127 : 15|8@0+ (1,-40) [-40|200] "C"  PT
 SG_ moduleTemperature128_BMS22 m128 : 15|8@0+ (1,-40) [-40|200] "C"  PT
 SG_ moduleTemperature129_BMS22 m129 : 15|8@0+ (1,-40) [-40|200] "C"  PT
 SG_ moduleTemperature130_BMS22 m130 : 15|8@0+ (1,-40) [-40|200] "C"  PT
 SG_ moduleTemperature131_BMS22 m131 : 15|8@0+ (1,-40) [-40|200] "C"  PT
 SG_ moduleTemperature132_BMS22 m132 : 15|8@0+ (1,-40) [-40|200] "C"  PT
 SG_ moduleTemperature133_BMS22 m133 : 15|8@0+ (1,-40) [-40|200] "C"  PT
 SG_ moduleTemperature134_BMS22 m134 : 15|8@0+ (1,-40) [-40|200] "C"  PT
 SG_ moduleTemperature135_BMS22 m135 : 15|8@0+ (1,-40) [-40|200] "C"  PT
 SG_ moduleTemperature136_BMS22 m136 : 15|8@0+ (1,-40) [-40|200] "C"  PT
 SG_ moduleTemperature137_BMS22 m137 : 15|8@0+ (1,-40) [-40|200] "C"  PT
 SG_ moduleTemperature138_BMS22 m138 : 15|8@0+ (1,-40) [-40|200] "C"  PT
 SG_ moduleTemperature139_BMS22 m139 : 15|8@0+ (1,-40) [-40|200] "C"  PT
 SG_ moduleTemperature140_BMS22 m140 : 15|8@0+ (1,-40) [-40|200] "C"  PT
 SG_ moduleTemperature141_BMS22 m141 : 15|8@0+ (1,-40) [-40|200] "C"  PT
 SG_ moduleTemperature142_BMS22 m142 : 15|8@0+ (1,-40) [-40|200] "C"  PT
 SG_ moduleTemperature143_BMS22 m143 : 15|8@0+ (1,-40) [-40|200] "C"  PT
 SG_ moduleTemperature144_BMS22 m144 : 15|8@0+ (1,-40) [-40|200] "C"  PT
 SG_ moduleTemperature145_BMS22 m145 : 15|8@0+ (1,-40) [-40|200] "C"  PT
 SG_ moduleTemperature146_BMS22 m146 : 15|8@0+ (1,-40) [-40|200] "C"  PT
 SG_ moduleTemperature147_BMS22 m147 : 15|8@0+ (1,-40) [-40|200] "C"  PT
 SG_ moduleTemperature148_BMS22 m148 : 15|8@0+ (1,-40) [-40|200] "C"  PT
 SG_ moduleTemperature149_BMS22 m149 : 15|8@0+ (1,-40) [-40|200] "C"  PT
 SG_ moduleTemperature150_BMS22 m150 : 15|8@0+ (1,-40) [-40|200] "C"  PT
 SG_ moduleTemperature151_BMS22 m151 : 15|8@0+ (1,-40) [-40|200] "C"  PT
 SG_ moduleTemperature152_BMS22 m152 : 15|8@0+ (1,-40) [-40|200] "C"  PT
 SG_ moduleTemperature153_BMS22 m153 : 15|8@0+ (1,-40) [-40|200] "C"  PT
 SG_ moduleTemperature154_BMS22 m154 : 15|8@0+ (1,-40) [-40|200] "C"  PT
 SG_ moduleTemperature155_BMS22 m155 : 15|8@0+ (1,-40) [-40|200] "C"  PT
 SG_ moduleTemperature156_BMS22 m156 : 15|8@0+ (1,-40) [-40|200] "C"  PT
 SG_ moduleTemperature157_BMS22 m157 : 15|8@0+ (1,-40) [-40|200] "C"  PT
 SG_ moduleTemperature158_BMS22 m158 : 15|8@0+ (1,-40) [-40|200] "C"  PT
 SG_ moduleTemperature159_BMS22 m159 : 15|8@0+ (1,-40) [-40|200] "C"  PT
 SG_ moduleTemperature160_BMS22 m160 : 15|8@0+ (1,-40) [-40|200] "C"  PT
 SG_ moduleTemperature161_BMS22 m161 : 15|8@0+ (1,-40) [-40|200] "C"  PT
 SG_ moduleTemperature162_BMS22 m162 : 15|8@0+ (1,-40) [-40|200] "C"  PT
 SG_ moduleTemperature163_BMS22 m163 : 15|8@0+ (1,-40) [-40|200] "C"  PT
 SG_ moduleTemperature164_BMS22 m164 : 15|8@0+ (1,-40) [-40|200] "C"  PT
 SG_ moduleTemperature165_BMS22 m165 : 15|8@0+ (1,-40) [-40|200] "C"  PT
 SG_ moduleTemperature166_BMS22 m166 : 15|8@0+ (1,-40) [-40|200] "C"  PT
 SG_ moduleTemperature167_BMS22 m167 : 15|8@0+ (1,-40) [-40|200] "C"  PT
 SG_ moduleTemperature168_BMS22 m168 : 15|8@0+ (1,-40) [-40|200] "C"  PT
 SG_ moduleTemperature169_BMS22 m169 : 15|8@0+ (1,-40) [-40|200] "C"  PT
 SG_ moduleTemperature170_BMS22 m170 : 15|8@0+ (1,-40) [-40|200] "C"  PT
 SG_ moduleTemperature171_BMS22 m171 : 15|8@0+ (1,-40) [-40|200] "C"  PT
 SG_ moduleTemperature172_BMS22 m172 : 15|8@0+ (1,-40) [-40|200] "C"  PT
 SG_ moduleTemperature173_BMS22 m173 : 15|8@0+ (1,-40) [-40|200] "C"  PT
 SG_ moduleTemperature174_BMS22 m174 : 15|8@0+ (1,-40) [-40|200] "C"  PT
 SG_ moduleTemperature175_BMS22 m175 : 15|8@0+ (1,-40) [-40|200] "C"  PT
 SG_ moduleTemperature176_BMS22 m176 : 15|8@0+ (1,-40) [-40|200] "C"  PT
 SG_ moduleTemperature177_BMS22 m177 : 15|8@0+ (1,-40) [-40|200] "C"  PT
 SG_ moduleTemperature178_BMS22 m178 : 15|8@0+ (1,-40) [-40|200] "C"  PT
 SG_ moduleTemperature179_BMS22 m179 : 15|8@0+ (1,-40) [-40|200] "C"  PT
 SG_ moduleTemperature180_BMS22 m180 : 15|8@0+ (1,-40) [-40|200] "C"  PT
 SG_ moduleTemperature181_BMS22 m181 : 15|8@0+ (1,-40) [-40|200] "C"  PT
 SG_ moduleTemperature182_BMS22 m182 : 15|8@0+ (1,-40) [-40|200] "C"  PT
 SG_ moduleTemperature183_BMS22 m183 : 15|8@0+ (1,-40) [-40|200] "C"  PT
 SG_ moduleTemperature184_BMS22 m184 : 15|8@0+ (1,-40) [-40|200] "C"  PT
 SG_ moduleTemperature185_BMS22 m185 : 15|8@0+ (1,-40) [-40|200] "C"  PT
 SG_ moduleTemperature186_BMS22 m186 : 15|8@0+ (1,-40) [-40|200] "C"  PT
 SG_ moduleTemperature187_BMS22 m187 : 15|8@0+ (1,-40) [-40|200] "C"  PT
 SG_ moduleTemperature188_BMS22 m188 : 15|8@0+ (1,-40) [-40|200] "C"  PT
 SG_ moduleTemperature189_BMS22 m189 : 15|8@0+ (1,-40) [-40|200] "C"  PT
 SG_ moduleTemperature190_BMS22 m190 : 15|8@0+ (1,-40) [-40|200] "C"  PT
 SG_ moduleTemperature191_BMS22 m191 : 15|8@0+ (1,-40) [-40|200] "C"  PT
 SG_ moduleTemperature192_BMS22 m192 : 15|8@0+ (1,-40) [-40|200] "C"  PT

BO_ 920 BMS25_DebugEventMap10: 8 BMS25
 SG_ DEM319_HV_DISABLE_DURING_S_BMS25 : 55|2@0+ (1,0) [0|3] ""  PT
 SG_ DEM318_HV_ENABLE_IMPLAUSIB_BMS25 : 53|2@0+ (1,0) [0|3] ""  PT
 SG_ DEM317_STRING_SUSPECT_OPEN_BMS25 : 51|2@0+ (1,0) [0|3] ""  PT
 SG_ DEM316_UNEXPCTD_BMS_ON_CAN_BMS25 : 49|2@0+ (1,0) [0|3] ""  PT
 SG_ DEM315_HV_WITHSTAND_TESTS__BMS25 : 63|2@0+ (1,0) [0|3] ""  PT
 SG_ DEM314_OBC_PILOT_ERROR_BMS25 : 61|2@0+ (1,0) [0|3] ""  PT
 SG_ DEM313_OBC_PILOT_HIGH_BMS25 : 59|2@0+ (1,0) [0|3] ""  PT
 SG_ DEM312_OBC_PROXIMITY_ERROR_BMS25 : 57|2@0+ (1,0) [0|3] ""  PT
 SG_ DEM311_CTRS_END_OF_LIFE_WA_BMS25 : 39|2@0+ (1,0) [0|3] ""  PT
 SG_ DEM310_BMSMIA_STRNGMSTR_AL_BMS25 : 37|2@0+ (1,0) [0|3] ""  PT
 SG_ DEM309_VOLTAGE_BRICKOV_WAR_BMS25 : 35|2@0+ (1,0) [0|3] ""  PT
 SG_ DEM308_PRESSURE_FLT_BMS25 : 33|2@0+ (1,0) [0|3] ""  PT
 SG_ DEM307_PRESSURE_MIA_BMS25 : 47|2@0+ (1,0) [0|3] ""  PT
 SG_ DEM306_SW_VERSION_MISMATCH_BMS25 : 45|2@0+ (1,0) [0|3] ""  PT
 SG_ DEM305_MODULET_OVERTEMP_WA_BMS25 : 43|2@0+ (1,0) [0|3] ""  PT
 SG_ DEM304_PCHG_OPENCIRCUIT_IN_BMS25 : 41|2@0+ (1,0) [0|3] ""  PT
 SG_ DEM303_MODULET_UNDERTEMP_W_BMS25 : 23|2@0+ (1,0) [0|3] ""  PT
 SG_ DEM302_MODULET_UT_BMS25 : 21|2@0+ (1,0) [0|3] ""  PT
 SG_ DEM301_FUSI_LOCK_BMS25 : 19|2@0+ (1,0) [0|3] ""  PT
 SG_ DEM300_DEBUG_SM_DISABLED_BMS25 : 17|2@0+ (1,0) [0|3] ""  PT
 SG_ DEM299_5V_SENSOR_SUPPLY_OU_BMS25 : 31|2@0+ (1,0) [0|3] ""  PT
 SG_ DEM298_IMPL_DRIVE_REQUEST_BMS25 : 29|2@0+ (1,0) [0|0] ""  PT
 SG_ DEM297_PCHG2_OPENCIRCUIT_BMS25 : 27|2@0+ (1,0) [0|0] ""  PT
 SG_ DEM296_CTRSAUX_IMPLAUSIBLE_BMS25 : 25|2@0+ (1,0) [0|0] ""  PT
 SG_ DEM295_CTRSAUX_LINKV_UNSAF_BMS25 : 7|2@0+ (1,0) [0|0] ""  PT
 SG_ DEM294_CANRX_PT_EMERGENCY_BMS25 : 5|2@0+ (1,0) [0|0] ""  PT
 SG_ DEM293_SBC_LDT_IMPLAUSIBLE_BMS25 : 3|2@0+ (1,0) [0|0] ""  PT
 SG_ DEM292_NUM_EXPECTED_STRING_BMS25 : 1|2@0+ (1,0) [0|0] ""  PT
 SG_ DEM291_NUM_EXPECTED_STRING_BMS25 : 15|2@0+ (1,0) [0|0] ""  PT
 SG_ DEM290_CMB_ONBOARD_DEFECT_BMS25 : 13|2@0+ (1,0) [0|0] ""  PT
 SG_ DEM289_TEMP_STATE_LATCHED_BMS25 : 11|2@0+ (1,0) [0|0] ""  PT
 SG_ DEM288_CURR_STATE_LATCHED_BMS25 : 9|2@0+ (1,0) [0|0] ""  PT

BO_ 984 BMS25_DebugSlowMpex2: 8 BMS25
 SG_ balancingInDriveTimer_BMS25 m18 : 15|16@0+ (1,0) [0|65535] "s"  PT
 SG_ SOCRestPolarization_BMS25 m11 : 63|8@0+ (0.002,0) [0|0.51] "V"  PT
 SG_ CoolantSensorState_BMS25 m1 : 51|2@0+ (1,0) [0|1] ""  PT
 SG_ temperatureModelOffset_BMS25 m7 : 15|8@0+ (0.1,0) [0|25.5] "C"  PT
 SG_ SOHCMinBrickHighEst_BMS25 m4 : 15|8@0+ (0.3,50) [50|126.5] "PCT"  PT
 SG_ SOHCMaxBrickHighEst_BMS25 m6 : 15|8@0+ (0.3,50) [50|126.5] "PCT"  PT
 SG_ regenCurrOpLkyBktThrs1_BMS25 m17 : 63|8@0+ (0.5,0) [0|127.5] "PCT"  PT
 SG_ dischargeCurrOpLkyBktThrs1_BMS25 m10 : 15|8@0+ (0.5,0) [0|127.5] "PCT"  PT
 SG_ regenCurrentOpLoadValue_BMS25 m16 : 15|8@0+ (0.5,0) [0|127.5] "PCT"  PT
 SG_ dischargeCurrOpLoadValue_BMS25 m15 : 15|8@0+ (0.5,0) [0|127.5] "PCT"  PT
 SG_ minBrickVoltageLimit_BMS25 m16 : 55|16@0+ (0.0001,0) [0|6.5535] "V"  PT
 SG_ SOHSuitableOCVRecal_BMS25 m1 : 49|1@0+ (1,0) [0|1] ""  PT
 SG_ currentModule3Integral_BMS25 m17 : 47|16@0+ (100,-3200000) [-3200000|3353500] "As"  PT
 SG_ currentModule2Integral_BMS25 m17 : 31|16@0+ (100,-3200000) [-3200000|3353500] "As"  PT
 SG_ currentModule1Integral_BMS25 m17 : 15|16@0+ (100,-3200000) [-3200000|3353500] "As"  PT
 SG_ currentModuleMin_BMS25 m16 : 23|16@0+ (0.1,-3200) [-3200|3200] "A"  PT
 SG_ currentModuleMax_BMS25 m16 : 39|16@0+ (0.1,-3200) [-3200|3200] "A"  PT
 SG_ maxBrickVoltageSync_BMS25 m9 : 39|16@0+ (0.0001,0) [0|6.5] "V"  PT
 SG_ minBrickVoltageSync_BMS25 m9 : 55|16@0+ (0.0001,0) [0|6.5] "V"  PT
 SG_ SOHCMinBrickLowEst_BMS25 m8 : 15|8@0+ (0.3,50) [50|126.5] "PCT"  PT
 SG_ SOHCMaxBrickLowEst_BMS25 m9 : 15|8@0+ (0.3,50) [50|126.5] "PCT"  PT
 SG_ gradLimSOC_BMS25 m10 : 39|16@0+ (0.002,0) [0|131.07] "PCT"  PT
 SG_ SOCRecalSlowOp_BMS25 m14 : 55|16@0+ (0.0001,-2) [-2|4.5535] "V"  PT
 SG_ SOHCMinIndex_BMS25 m12 : 39|16@0+ (1,0) [0|65535] ""  PT
 SG_ SOHCMaxIndex_BMS25 m12 : 55|16@0+ (1,0) [0|65535] ""  PT
 SG_ SOHRMinRegen_BMS25 m11 : 39|8@0+ (1,50) [50|305] "PCT"  PT
 SG_ SOHRMinDchg_BMS25 m11 : 15|8@0+ (1,50) [50|305] "PCT"  PT
 SG_ SOHRMeanRegen_BMS25 m11 : 47|8@0+ (1,50) [50|305] "PCT"  PT
 SG_ SOHRMeanDchg_BMS25 m11 : 23|8@0+ (1,50) [50|305] "PCT"  PT
 SG_ SOHRMaxRegen_BMS25 m11 : 55|8@0+ (1,50) [50|305] "PCT"  PT
 SG_ SOHRMaxDchg_BMS25 m11 : 31|8@0+ (1,50) [50|305] "PCT"  PT
 SG_ SOHCMin_BMS25 m12 : 15|8@0+ (0.3,50) [50|126.5] "PCT"  PT
 SG_ SOHCMean_BMS25 m12 : 23|8@0+ (0.3,50) [50|126.5] "PCT"  PT
 SG_ SOHCMax_BMS25 m12 : 31|8@0+ (0.3,50) [50|126.5] "PCT"  PT
 SG_ ppRegenCurrLimitPredShort_BMS25 m6 : 23|8@0+ (2,0) [0|510] "A"  PT
 SG_ ppRegenCurrLimitPredLong_BMS25 m6 : 31|8@0+ (2,0) [0|510] "A"  PT
 SG_ ppDchgCurrLimitPredShort_BMS25 m13 : 55|8@0+ (2,-510) [-510|0] "A"  PT
 SG_ ppDchgCurrLimitPredLong_BMS25 m13 : 63|8@0+ (2,-510) [-510|0] "A"  PT
 SG_ ppInconsistentPol_BMS25 m1 : 48|1@0+ (1,0) [0|0] ""  PT
 SG_ ppPolarizationV_BMS25 m3 : 55|16@0+ (0.0001,-3) [-3|3.5535] "V"  PT
 SG_ SOCRecalMinOCVEst_BMS25 m13 : 39|16@0+ (0.0001,0) [0|6.5535] "V"  PT
 SG_ SOCRecalMaxOCVEst_BMS25 m14 : 39|16@0+ (0.0001,0) [0|6.5535] "V"  PT
 SG_ SOCRecalMinSOCUpp_BMS25 m13 : 31|8@0+ (0.5,0) [0|127.5] "PCT"  PT
 SG_ SOCRecalMinSOCLow_BMS25 m13 : 15|8@0+ (0.5,0) [0|127.5] "PCT"  PT
 SG_ SOCRecalMinSOC_BMS25 m13 : 23|8@0+ (0.5,0) [0|127.5] "PCT"  PT
 SG_ SOCRecalMaxSOCUpp_BMS25 m14 : 31|8@0+ (0.5,0) [0|127.5] "PCT"  PT
 SG_ SOCRecalMaxSOCLow_BMS25 m14 : 15|8@0+ (0.5,0) [0|127.5] "PCT"  PT
 SG_ SOCRecalMaxSOC_BMS25 m14 : 23|8@0+ (0.5,0) [0|127.5] "PCT"  PT
 SG_ ppNewtonRootInRangeRegen_BMS25 m5 : 12|1@0+ (1,0) [0|0] ""  PT
 SG_ ppNewtonRootInRangeDchg_BMS25 m5 : 8|1@0+ (1,0) [0|0] ""  PT
 SG_ ppNewtonStepsRegen_BMS25 m5 : 15|3@0+ (1,0) [0|1] ""  PT
 SG_ ppNewtonStepsDchg_BMS25 m5 : 11|3@0+ (1,0) [0|1] ""  PT
 SG_ ppNewtonRegenVRes_BMS25 m5 : 31|8@0+ (0.001,-0.1) [-0.1|0.155] "V"  PT
 SG_ ppNewtonDchgVRes_BMS25 m5 : 23|8@0+ (0.001,-0.1) [-0.1|0.155] "V"  PT
 SG_ ppMinModelAlphaTarget_BMS25 m3 : 15|8@0+ (0.02,0) [0|5.1] ""  PT
 SG_ ppMaxModelAlphaTarget_BMS25 m1 : 63|8@0+ (0.02,0) [0|5.1] ""  PT
 SG_ ppLearningTauRegen_BMS25 m2 : 55|16@0+ (0.2,0) [0|0] "s"  PT
 SG_ ppLearningCriterionDyn_BMS25 m2 : 15|8@0+ (0.005,0) [0|0] ""  PT
 SG_ ppLearningCriterionAbs_BMS25 m1 : 15|8@0+ (0.005,0) [0|0] ""  PT
 SG_ ppLearningCriterionJoin_BMS25 m0 : 15|8@0+ (0.005,0) [0|0] ""  PT
 SG_ ppMaxModelMeasV_BMS25 m7 : 23|16@0+ (0.0001,0) [0|6.5535] "V"  PT
 SG_ currentRedundant_BMS25 m15 : 23|16@0+ (0.1,-3200) [-3200|3200] "A"  PT
 SG_ currentModule3_BMS25 m10 : 55|16@0+ (0.1,-3200) [-3200|3200] "A"  PT
 SG_ currentModule2_BMS25 m10 : 23|16@0+ (0.1,-3200) [-3200|3200] "A"  PT
 SG_ currentModule1_BMS25 m9 : 23|16@0+ (0.1,-3200) [-3200|3200] "A"  PT
 SG_ ppMeanRegenIntRes_BMS25 m6 : 55|16@0+ (0.01,0) [0|655.35] "mOhm"  PT
 SG_ ppMeanDchgIntRes_BMS25 m6 : 39|16@0+ (0.01,0) [0|655.35] "mOhm"  PT
 SG_ ppMinModelVoltageIndex_BMS25 m5 : 39|16@0+ (1,0) [0|65535] ""  PT
 SG_ ppMinModelLowpassV_BMS25 m4 : 55|16@0+ (0.0001,0) [0|0] "V"  PT
 SG_ ppMaxModelVoltageIndex_BMS25 m5 : 55|16@0+ (1,0) [0|65535] ""  PT
 SG_ ppMaxModelLowpassV_BMS25 m7 : 55|16@0+ (0.0001,0) [0|0] "V"  PT
 SG_ ppLearningTauDischarge_BMS25 m0 : 55|16@0+ (0.2,0) [0|0] "s"  PT
 SG_ ppMaxRegenAlpha_BMS25 m15 : 39|16@0+ (0.0001,0) [0|6.5535] ""  PT
 SG_ ppMaxModelledV_BMS25 m7 : 39|16@0+ (0.0001,0) [0|6.5535] "V"  PT
 SG_ ppMinDchgAlpha_BMS25 m15 : 55|16@0+ (0.0001,0) [0|6.5535] ""  PT
 SG_ ppMinModelledV_BMS25 m4 : 39|16@0+ (0.0001,0) [0|6.5535] "V"  PT
 SG_ ppMinModelMeasV_BMS25 m4 : 23|16@0+ (0.0001,0) [0|6.5535] "V"  PT
 SG_ debugSlowMpex2_BMS25 M : 7|8@0+ (1,0) [0|0] ""  PT
 SG_ ppRegenCurrPredShort_BMS25 m2 : 23|16@0+ (0.02,0) [0|1310.7] "A"  PT
 SG_ ppDischgCurrPredLong_BMS25 m0 : 39|16@0+ (0.05,-3200) [-3200|0] "A"  PT
 SG_ ppDischgCurrPredShort_BMS25 m0 : 23|16@0+ (0.05,-3200) [-3200|0] "A"  PT
 SG_ ppRegenCurrPredLong_BMS25 m2 : 39|16@0+ (0.02,0) [0|1310.7] "A"  PT
 SG_ ppRegenVPredShort_BMS25 m3 : 23|16@0+ (0.02,0) [0|1310.7] "V"  PT
 SG_ ppDischgVPredShort_BMS25 m1 : 23|16@0+ (0.02,0) [0|1310.7] "V"  PT
 SG_ ppRegenVPredLong_BMS25 m3 : 39|16@0+ (0.02,0) [0|1310.7] "V"  PT
 SG_ ppDischgVPredLong_BMS25 m1 : 39|16@0+ (0.02,0) [0|1310.7] "V"  PT
 SG_ SOHDeltaSOCCoulomb_BMS25 m8 : 23|16@0+ (0.005,-150) [-150|177.675] "PCT"  PT
 SG_ SOHAbsDeltaSOCCoulomb_BMS25 m8 : 39|16@0+ (0.05,0) [0|3276.75] "PCT"  PT
 SG_ SOHLastOCVRecalMinSOC_BMS25 m8 : 55|8@0+ (0.393,0) [0|100.215] "PCT"  PT
 SG_ SOHbalancingTimeMinSOH_BMS25 m8 : 63|8@0+ (1,0) [0|255] "Min"  PT

BO_ 1816 BMS25_DebugFastMpex2: 8 BMS25
 SG_ chargerDCOutV_BMS25 m1 : 55|16@0+ (0.04,-1250) [-1250|1250] "V"  PT
 SG_ DIGIO_CHARGERCC_BMS25 m1 : 10|1@0+ (1,0) [0|0] ""  PT
 SG_ chargerProximity_BMS25 m1 : 23|8@0+ (0.02,0) [0|12] "V"  PT
 SG_ chargerPilot_BMS25 m1 : 31|8@0+ (0.05,0) [0|12.75] "V"  PT
 SG_ chargerCurrAvail_BMS25 m1 : 39|8@0+ (0.5,0) [0|127.5] "A"  PT
 SG_ chargerCtrOn_BMS25 m1 : 8|1@0+ (1,0) [0|0] ""  PT
 SG_ chargerOn_BMS25 m1 : 9|1@0+ (1,0) [0|0] ""  PT
 SG_ debugFastMpex2_BMS25 M : 7|8@0+ (1,0) [0|0] ""  PT
 SG_ posPackDbg_BMS25 m0 : 39|16@0+ (0.04,-1250) [-1250|1250] "V"  PT
 SG_ negPackDbg_BMS25 m0 : 55|16@0+ (0.04,-1250) [-1250|1250] "V"  PT
 SG_ packVoltageHVMeas_BMS25 m0 : 23|16@0+ (0.04,-1250) [-1250|1250] "V"  PT

BO_ 1880 BMS25_DebugSlowMpex1: 8 BMS25
 SG_ SOHRecentChange_BMS25 m43 : 15|8@0+ (0.1,-15) [-15|10.5] ""  PT
 SG_ SOHConvergenceIndicator_BMS25 m43 : 31|8@0+ (1,0) [0|255] ""  PT
 SG_ SOHConvergenceCounter_BMS25 m43 : 39|8@0+ (0.024,3) [0|6] ""  PT
 SG_ SOHMinFiltered_BMS25 m43 : 23|8@0+ (0.3,50) [50|126.5] "PCT"  PT
 SG_ prechargeCyMatchWaitTime_BMS25 m43 : 47|16@0+ (1,0) [0|65535] "ms"  PT
 SG_ medianModuleTempGrp2_BMS25 m13 : 63|8@0+ (1,-40) [-40|200] "C"  PT
 SG_ medianModuleTempGrp1_BMS25 m13 : 55|8@0+ (1,-40) [-40|200] "C"  PT
 SG_ coolantWarningtAlert_BMS25 m12 : 49|2@0+ (1,0) [0|3] ""  PT
 SG_ coolantFaultAlert_BMS25 m12 : 51|2@0+ (1,0) [0|3] ""  PT
 SG_ hvilShutdownStrategy_BMS25 m42 : 63|8@0+ (1,0) [0|255] ""  PT
 SG_ J1939_nmState m12 : 55|4@0+ (1,0) [0|0] ""  PT
 SG_ PrechargeXCapMin_BMS25 m42 : 47|16@0+ (0.01,0) [0|1] "mF"  PT
 SG_ LimpHomeTimeOut_BMS25 m42 : 15|32@0+ (1,0) [0|4294967295] "ms"  PT
 SG_ hvWithstandTests_BMS25 m40 : 15|8@0+ (1,0) [0|255] ""  PT
 SG_ aux3prechargeState_BMS25 m41 : 19|4@0+ (1,0) [0|0] ""  PT
 SG_ aux2prechargeState_BMS25 m41 : 31|4@0+ (1,0) [0|0] ""  PT
 SG_ aux1prechargeState_BMS25 m41 : 27|4@0+ (1,0) [0|0] ""  PT
 SG_ auxLinkVoltage_BMS25 m40 : 23|16@0+ (0.02,0) [0|1310.7] "V"  PT
 SG_ invalidModuleVoltageFlags_BMS25 m41 : 39|32@0+ (1,0) [0|0] ""  PT
 SG_ invalidModuleTempFlags_BMS25 m40 : 39|32@0+ (1,0) [0|0] ""  PT
 SG_ pumpSpeedExpected_BMS25 m30 : 15|8@0+ (0.4,0) [0|102] "%"  PT
 SG_ rangeRequestIgnoreVehicle m28 : 55|4@0+ (1,0) [0|65535] ""  PT
 SG_ rangeRequestEepromValue m28 : 63|4@0+ (1,0) [0|65535] ""  PT
 SG_ pressure2_BMS25 m35 : 31|8@0+ (0.4,0) [0|19] "psi"  PT
 SG_ calibration_version_BMS25 m37 : 63|8@0+ (1,0) [0|0] ""  PT
 SG_ currentLowTimer_BMS25 m39 : 55|16@0+ (1,0) [0|65535] "s"  PT
 SG_ auxCntrrOpenUnderLoadCntr_BMS25 m39 : 39|16@0+ (1,0) [0|0] ""  PT
 SG_ rabbitContactorState_BMS25 m34 : 31|8@0+ (1,0) [0|255] ""  PT
 SG_ analogIsenseSupplyCurr_BMS25 m37 : 55|8@0+ (0.04,0) [0|10] "A"  PT
 SG_ pumpSpeedReqCoolPrfmc_BMS25 m29 : 15|8@0+ (1,0) [0|0] "PCT"  PT
 SG_ microsarOs_IdleTask_OsCr0_BMS25 m39 : 23|8@0+ (1,0) [0|100] "PCT"  PT
 SG_ microsarOs_BswTask_BMS25 m39 : 15|8@0+ (1,0) [0|100] "PCT"  PT
 SG_ microsarOs_InitTask_BMS25 m39 : 31|8@0+ (1,0) [0|100] "PCT"  PT
 SG_ microsarOs_ApplTask_1Hz_BMS25 m38 : 63|8@0+ (1,0) [0|100] "PCT"  PT
 SG_ microsarOs_ApplTask_10Hz_BMS25 m38 : 55|8@0+ (1,0) [0|100] "PCT"  PT
 SG_ microsarOs_ApplTask_100Hz_BMS25 m38 : 47|8@0+ (1,0) [0|100] "PCT"  PT
 SG_ microsarOs_ApplLowTask_BMS25 m38 : 39|8@0+ (1,0) [0|100] "PCT"  PT
 SG_ microsarOs_ApplLateInit_BMS25 m38 : 31|8@0+ (1,0) [0|100] "PCT"  PT
 SG_ microsarOs_ApplHighTask_BMS25 m38 : 23|8@0+ (1,0) [0|100] "PCT"  PT
 SG_ microsarOs_ApplEarlyInit_BMS25 m38 : 15|8@0+ (1,0) [0|100] "PCT"  PT
 SG_ pumpRecoveryAttempts_BMS25 m31 : 15|8@0+ (1,0) [0|0] ""  PT
 SG_ appTaskBSWMaxDuration_BMS25 m37 : 47|8@0+ (0.5,0) [0|100] "PCT"  PT
 SG_ appTaskApplHighMaxDuration_BMS25 m37 : 15|16@0+ (0.5,0) [0|100] "PCT"  PT
 SG_ appTask1HzMaxDuration_BMS25 m36 : 63|8@0+ (0.5,0) [0|100] "PCT"  PT
 SG_ appTask100HzMaxDuration_BMS25 m36 : 47|8@0+ (0.5,0) [0|100] "PCT"  PT
 SG_ appTask10HzMaxDuration_BMS25 m36 : 55|8@0+ (0.5,0) [0|100] "PCT"  PT
 SG_ appTask100HzDuration_BMS25 m36 : 15|8@0+ (0.5,0) [0|100] "PCT"  PT
 SG_ appTask10HzDuration_BMS25 m36 : 23|8@0+ (0.5,0) [0|100] "PCT"  PT
 SG_ appTask1HzDuration_BMS25 m36 : 31|8@0+ (0.5,0) [0|100] "PCT"  PT
 SG_ appTaskBSWDuration_BMS25 m36 : 39|8@0+ (0.5,0) [0|100] "PCT"  PT
 SG_ appTaskApplHighDuration_BMS25 m37 : 31|16@0+ (0.5,0) [0|100] "PCT"  PT
 SG_ iumprMaxRatioDTCId_BMS25 m35 : 15|8@0+ (1,0) [0|0] ""  PT
 SG_ iumprMaxRatio_BMS25 m35 : 23|8@0+ (1,0) [0|0] ""  PT
 SG_ iumprMinRatioDTCId_BMS25 m33 : 63|8@0+ (1,0) [0|0] ""  PT
 SG_ iumprMinRatio_BMS25 m33 : 55|8@0+ (1,0) [0|0] ""  PT
 SG_ eepromWriteCyclesMax_BMS25 m11 : 55|16@0+ (64,0) [0|0] ""  PT
 SG_ eepromWriteCyclesUds_BMS25 m10 : 55|8@0+ (1,0) [0|0] ""  PT
 SG_ eepromWriteCyclesStat_BMS25 m10 : 63|8@0+ (1,0) [0|0] ""  PT
 SG_ eepromWriteCyclesSoh_BMS25 m11 : 47|8@0+ (1,0) [0|0] ""  PT
 SG_ fluidLvlCount_BMS25 m34 : 15|8@0+ (1,0) [0|255] ""  PT
 SG_ fluidLvlSensr2_BMS25 m34 : 19|2@0+ (1,0) [0|0] ""  PT
 SG_ fluidLvlSensr1_BMS25 m34 : 17|2@0+ (1,0) [0|0] ""  PT
 SG_ pumpSpeedReqVhcleSpeed_BMS25 m2 : 15|8@0+ (1,0) [0|0] "PCT"  PT
 SG_ appTaskBSWCpuUsage_BMS25 m18 : 15|8@0+ (0.5,0) [0|100] "PCT"  PT
 SG_ appTask200HzCpuUsage_BMS25 m17 : 15|8@0+ (0.5,0) [0|100] "PCT"  PT
 SG_ SWVersionBL_BMS25 m34 : 39|32@0+ (1,0) [0|4294967295] ""  PT
 SG_ SWVersionApp_BMS25 m35 : 39|32@0+ (1,0) [0|4294967295] ""  PT
 SG_ hvSNACounter_BMS25 m31 : 23|16@0+ (1,0) [0|0] ""  PT
 SG_ pyroState_BMS25 m28 : 59|4@0+ (1,0) [0|0] ""  PT
 SG_ ecuSerialNrChar15_BMS25 m33 : 47|8@0+ (1,0) [0|0] ""  PT
 SG_ ecuSerialNrChar14_BMS25 m33 : 39|8@0+ (1,0) [0|0] ""  PT
 SG_ ecuSerialNrChar13_BMS25 m33 : 31|8@0+ (1,0) [0|0] ""  PT
 SG_ ecuSerialNrChar12_BMS25 m33 : 23|8@0+ (1,0) [0|0] ""  PT
 SG_ ecuSerialNrChar11_BMS25 m32 : 63|8@0+ (1,0) [0|0] ""  PT
 SG_ ecuSerialNrChar10_BMS25 m32 : 55|8@0+ (1,0) [0|0] ""  PT
 SG_ ecuSerialNrChar09_BMS25 m32 : 47|8@0+ (1,0) [0|0] ""  PT
 SG_ ecuSerialNrChar08_BMS25 m32 : 39|8@0+ (1,0) [0|0] ""  PT
 SG_ ecuSerialNrChar07_BMS25 m32 : 31|8@0+ (1,0) [0|0] ""  PT
 SG_ ecuSerialNrChar06_BMS25 m32 : 23|8@0+ (1,0) [0|0] ""  PT
 SG_ ecuSerialNrChar05_BMS25 m32 : 15|8@0+ (1,0) [0|0] ""  PT
 SG_ analogGPIO1Current_BMS25 m22 : 39|8@0+ (0.015,0) [0|3.825] "A"  PT
 SG_ analogGPIO1Volt_BMS25 m22 : 55|8@0+ (0.1,0) [0|25] "V"  PT
 SG_ analogGPIO2Current_BMS25 m22 : 47|8@0+ (0.015,0) [0|3.825] "A"  PT
 SG_ analogGPIO2Volt_BMS25 m22 : 63|8@0+ (0.1,0) [0|25] "V"  PT
 SG_ pumpSpeedReqLoadValue_BMS25 m22 : 15|8@0+ (1,0) [0|0] "PCT"  PT
 SG_ ssaRTYear_BMS25 m31 : 55|16@0+ (1,0) [0|0] "yyyy"  PT
 SG_ ssaRTMonth_BMS25 m31 : 47|8@0+ (1,0) [0|0] "mm"  PT
 SG_ ssaRTDay_BMS25 m31 : 39|8@0+ (1,0) [0|0] "dd"  PT
 SG_ ssaTimeMRealTimeOffset_BMS25 m30 : 23|48@0+ (1,0) [0|0] ""  PT
 SG_ ssaTimeMTickCount_BMS25 m29 : 23|48@0+ (1,0) [0|0] ""  PT
 SG_ appTask50HzStackUsage_BMS25 m24 : 15|8@0+ (0.5,0) [0|100] "PCT"  PT
 SG_ OBDMILRequested_BMS25 m28 : 49|2@0+ (1,0) [0|3] ""  PT
 SG_ OBDConfirmedDTCsCount_BMS25 m28 : 15|8@0+ (1,0) [0|255] ""  PT
 SG_ OBDFirstConfirmedDTC_BMS25 m28 : 31|8@0+ (1,0) [0|255] ""  PT
 SG_ OBDFirstConfDTCWarmCyc_BMS25 m28 : 47|6@0+ (1,0) [0|63] ""  PT
 SG_ OBDPermanentDTCCount_BMS25 m28 : 23|8@0+ (1,0) [0|255] ""  PT
 SG_ OBDFirstPermanentDTC_BMS25 m28 : 39|8@0+ (1,0) [0|255] ""  PT
 SG_ OBDFirstPermDTCDriveCyc_BMS25 m28 : 41|2@0+ (1,0) [0|3] ""  PT
 SG_ nmStartupReason_BMS25 m16 : 15|4@0+ (1,0) [0|0] ""  PT
 SG_ SOCdynamicRecal_BMS25 m10 : 19|1@0+ (1,0) [0|1] ""  PT
 SG_ SOCuserSOCInit_BMS25 m10 : 18|1@0+ (1,0) [0|1] ""  PT
 SG_ contactorType_BMS25 m25 : 11|4@0+ (1,0) [0|0] ""  PT
 SG_ activeIsoTestDuration_BMS25 m13 : 15|8@0+ (200,0) [0|51000] "ms"  PT
 SG_ balancingState_BMS25 m16 : 11|4@0+ (1,0) [0|0] ""  PT
 SG_ storCondSysNwOk_BMS25 m27 : 25|1@0+ (1,0) [0|0] ""  PT
 SG_ storCondSysPwrOk_BMS25 m27 : 26|1@0+ (1,0) [0|0] ""  PT
 SG_ storCondECUOk_BMS25 m27 : 24|1@0+ (1,0) [0|0] ""  PT
 SG_ chronoStackWrCnt_BMS25 m27 : 39|32@0+ (1,0) [0|0] ""  PT
 SG_ wakeReason_BMS25 m10 : 15|4@0+ (1,0) [0|0] ""  PT
 SG_ cntrUnderLoadOpenCntr7_BMS25 m26 : 63|8@0+ (1,0) [0|0] ""  PT
 SG_ cntrUnderLoadOpenCntr6_BMS25 m26 : 55|8@0+ (1,0) [0|0] ""  PT
 SG_ cntrUnderLoadOpenCntr5_BMS25 m26 : 47|8@0+ (1,0) [0|0] ""  PT
 SG_ cntrUnderLoadOpenCntr4_BMS25 m26 : 39|8@0+ (1,0) [0|0] ""  PT
 SG_ cntrUnderLoadOpenCntr3_BMS25 m26 : 31|8@0+ (1,0) [0|0] ""  PT
 SG_ cntrUnderLoadOpenCntr2_BMS25 m26 : 23|8@0+ (1,0) [0|0] ""  PT
 SG_ cntrUnderLoadOpenCntr1_BMS25 m26 : 15|8@0+ (1,0) [0|0] ""  PT
 SG_ coolantOutletTemperature_BMS25 m27 : 23|8@0+ (1,-40) [-40|215] "C"  PT
 SG_ coolantInletTemperature_BMS25 m27 : 15|8@0+ (1,-40) [-40|215] "C"  PT
 SG_ prchgResHeatModel_BMS25 m3 : 55|16@0+ (0.1,0) [0|0] "Ws"  PT
 SG_ variantCodingCount_BMS25 m7 : 15|8@0+ (1,0) [0|0] ""  PT
 SG_ SWVersionCusApp_BMS25 m7 : 39|32@0+ (1,0) [0|0] ""  PT
 SG_ contactorOpenRequest_BMS25 m25 : 15|4@0+ (1,0) [0|0] ""  PT
 SG_ maxBrickVoltageChargeLimit_BMS25 m25 : 23|16@0+ (0.0001,0) [0|6.5] "V"  PT
 SG_ desiccantTimer_BMS25 m25 : 39|32@0+ (1,0) [0|0] "s"  PT
 SG_ batSwitchOpenReason_BMS25 m4 : 55|16@0+ (1,0) [0|0] ""  PT
 SG_ balancingTime_BMS25 m24 : 55|16@0+ (1,0) [0|65535] ""  PT
 SG_ bmsIsESSMaster_BMS25 m6 : 14|1@0+ (1,0) [0|0] ""  PT
 SG_ ecuSerialNrChar01_BMS25 m12 : 23|8@0+ (1,0) [0|0] ""  PT
 SG_ ecuSerialNrChar02_BMS25 m12 : 31|8@0+ (1,0) [0|0] ""  PT
 SG_ ecuSerialNrChar03_BMS25 m12 : 39|8@0+ (1,0) [0|0] ""  PT
 SG_ ecuSerialNrChar04_BMS25 m12 : 47|8@0+ (1,0) [0|0] ""  PT
 SG_ ecuSerialNrChar16_BMS25 m13 : 23|8@0+ (1,0) [0|0] ""  PT
 SG_ ecuSerialNrChar17_BMS25 m13 : 31|8@0+ (1,0) [0|0] ""  PT
 SG_ ecuSerialNrChar18_BMS25 m13 : 39|8@0+ (1,0) [0|0] ""  PT
 SG_ ecuSerialNrChar19_BMS25 m13 : 47|8@0+ (1,0) [0|0] ""  PT
 SG_ maxModuleTemperature_BMS25 m5 : 63|8@0+ (1,-40) [-40|200] "C"  PT
 SG_ meanModuleTemperature_BMS25 m8 : 15|8@0+ (1,-40) [-40|200] "C"  PT
 SG_ minModuleTemperature_BMS25 m5 : 55|8@0+ (1,-40) [-40|200] "C"  PT
 SG_ currentEventsShrt_BMS25 m6 : 15|1@0+ (1,0) [0|0] ""  PT
 SG_ nmOperationalMode_BMS25 m1 : 13|2@0+ (1,0) [0|0] ""  PT
 SG_ nmNetworkMode_BMS25 m1 : 15|2@0+ (1,0) [0|0] ""  PT
 SG_ nmNetworkState_BMS25 m1 : 11|1@0+ (1,0) [0|0] ""  PT
 SG_ ecuState_BMS25 m1 : 10|3@0+ (1,0) [0|7] ""  PT
 SG_ SPIRxTxDiag_BMS25 m10 : 11|4@0+ (2,0) [0|30] ""  PT
 SG_ minSOC_BMS25 m24 : 23|16@0+ (0.01,0) [0|100] "PCT"  PT
 SG_ maxSOC_BMS25 m24 : 39|16@0+ (0.01,0) [0|100] "PCT"  PT
 SG_ appTaskMaxCpuUsage_BMS25 m23 : 63|8@0+ (0.5,0) [0|100] "PCT"  PT
 SG_ appTaskCpuUsage_BMS25 m23 : 55|8@0+ (0.5,0) [0|100] "PCT"  PT
 SG_ appTask50HzCpuUsage_BMS25 m23 : 47|8@0+ (0.5,0) [0|100] "PCT"  PT
 SG_ appTask10HzStackUsage_BMS25 m23 : 39|8@0+ (0.5,0) [0|100] "PCT"  PT
 SG_ appTask100HzCpuUsage_BMS25 m23 : 31|8@0+ (0.5,0) [0|100] "PCT"  PT
 SG_ appTask10HzCpuUsage_BMS25 m23 : 23|8@0+ (0.5,0) [0|100] "PCT"  PT
 SG_ appTask1HzCpuUsage_BMS25 m23 : 15|8@0+ (0.5,0) [0|100] "PCT"  PT
 SG_ pumpSpeedReq_BMS25 m12 : 15|8@0+ (1,0) [0|0] "PCT"  PT
 SG_ numberOfStrings_BMS25 m4 : 15|5@0+ (1,0) [0|0] ""  PT
 SG_ hvComponentOpLimit_BMS25 m22 : 23|16@0+ (0.05,0) [0|3276.75] "A"  PT
 SG_ regenCurrPredBrickVOffset_BMS25 m5 : 15|8@0+ (0.5,0) [0|127.5] "A"  PT
 SG_ dischgCurrPredBrickVOffset_BMS25 m3 : 15|8@0+ (0.5,0) [0|127.5] "A"  PT
 SG_ PCANBusOffState_BMS25 m6 : 11|2@0+ (1,0) [0|0] ""  PT
 SG_ SCANBusOffState_BMS25 m6 : 13|2@0+ (1,0) [0|0] ""  PT
 SG_ PTCANBusOffState_BMS25 m6 : 9|2@0+ (1,0) [0|0] ""  PT
 SG_ eepromWriteCyclesSoc_BMS25 m11 : 39|8@0+ (1,0) [0|0] ""  PT
 SG_ eepromWriteCyclesDiag_BMS25 m11 : 31|8@0+ (1,0) [0|0] ""  PT
 SG_ eepromWriteCyclesChrono_BMS25 m10 : 39|8@0+ (1,0) [0|0] ""  PT
 SG_ eepromWriteCyclesCust_BMS25 m10 : 47|8@0+ (1,0) [0|0] ""  PT
 SG_ customerModelVsYear_BMS25 m14 : 23|8@0+ (1,0) [0|0] ""  PT
 SG_ customerModelVsWeek_BMS25 m14 : 31|8@0+ (1,0) [0|0] ""  PT
 SG_ customerModelVsCellType_BMS25 m14 : 15|1@0+ (1,0) [0|0] ""  PT
 SG_ customerModelVsCellGen_BMS25 m14 : 14|7@0+ (1,0) [0|0] ""  PT
 SG_ SWVersion_BMS25 m14 : 39|32@0+ (1,0) [0|4294967295] ""  PT
 SG_ balancingRequest288_to_295_BMS25 m21 : 63|8@0+ (1,0) [0|0] ""  PT
 SG_ balancingRequest296_to_303_BMS25 m21 : 55|8@0+ (1,0) [0|0] ""  PT
 SG_ balancingRequest304_to_311_BMS25 m21 : 47|8@0+ (1,0) [0|0] ""  PT
 SG_ balancingRequest312_to_319_BMS25 m21 : 39|8@0+ (1,0) [0|0] ""  PT
 SG_ balancingRequest320_to_327_BMS25 m21 : 31|8@0+ (1,0) [0|0] ""  PT
 SG_ balancingRequest328_to_335_BMS25 m21 : 23|8@0+ (1,0) [0|0] ""  PT
 SG_ balancingRequest240_to_247_BMS25 m20 : 63|8@0+ (1,0) [0|0] ""  PT
 SG_ balancingRequest248_to_255_BMS25 m20 : 55|8@0+ (1,0) [0|0] ""  PT
 SG_ balancingRequest256_to_263_BMS25 m20 : 47|8@0+ (1,0) [0|0] ""  PT
 SG_ balancingRequest264_to_271_BMS25 m20 : 39|8@0+ (1,0) [0|0] ""  PT
 SG_ balancingRequest272_to_279_BMS25 m20 : 31|8@0+ (1,0) [0|0] ""  PT
 SG_ balancingRequest280_to_287_BMS25 m20 : 23|8@0+ (1,0) [0|0] ""  PT
 SG_ balancingRequest192_to_199_BMS25 m19 : 63|8@0+ (1,0) [0|0] ""  PT
 SG_ balancingRequest200_to_207_BMS25 m19 : 55|8@0+ (1,0) [0|0] ""  PT
 SG_ balancingRequest208_to_215_BMS25 m19 : 47|8@0+ (1,0) [0|0] ""  PT
 SG_ balancingRequest216_to_223_BMS25 m19 : 39|8@0+ (1,0) [0|0] ""  PT
 SG_ balancingRequest224_to_231_BMS25 m19 : 31|8@0+ (1,0) [0|0] ""  PT
 SG_ balancingRequest232_to_239_BMS25 m19 : 23|8@0+ (1,0) [0|0] ""  PT
 SG_ balancingRequest144_to_151_BMS25 m18 : 63|8@0+ (1,0) [0|0] ""  PT
 SG_ balancingRequest152_to_159_BMS25 m18 : 55|8@0+ (1,0) [0|0] ""  PT
 SG_ balancingRequest160_to_167_BMS25 m18 : 47|8@0+ (1,0) [0|0] ""  PT
 SG_ balancingRequest168_to_175_BMS25 m18 : 39|8@0+ (1,0) [0|0] ""  PT
 SG_ balancingRequest176_to_183_BMS25 m18 : 31|8@0+ (1,0) [0|0] ""  PT
 SG_ balancingRequest184_to_191_BMS25 m18 : 23|8@0+ (1,0) [0|0] ""  PT
 SG_ balancingRequest096_to_103_BMS25 m17 : 63|8@0+ (1,0) [0|0] ""  PT
 SG_ balancingRequest104_to_111_BMS25 m17 : 55|8@0+ (1,0) [0|0] ""  PT
 SG_ balancingRequest112_to_119_BMS25 m17 : 47|8@0+ (1,0) [0|0] ""  PT
 SG_ balancingRequest120_to_127_BMS25 m17 : 39|8@0+ (1,0) [0|0] ""  PT
 SG_ balancingRequest128_to_135_BMS25 m17 : 31|8@0+ (1,0) [0|0] ""  PT
 SG_ balancingRequest136_to_143_BMS25 m17 : 23|8@0+ (1,0) [0|0] ""  PT
 SG_ balancingRequest048_to_055_BMS25 m16 : 63|8@0+ (1,0) [0|0] ""  PT
 SG_ balancingRequest056_to_063_BMS25 m16 : 55|8@0+ (1,0) [0|0] ""  PT
 SG_ balancingRequest064_to_071_BMS25 m16 : 47|8@0+ (1,0) [0|0] ""  PT
 SG_ balancingRequest072_to_079_BMS25 m16 : 39|8@0+ (1,0) [0|0] ""  PT
 SG_ balancingRequest080_to_087_BMS25 m16 : 31|8@0+ (1,0) [0|0] ""  PT
 SG_ balancingRequest088_to_095_BMS25 m16 : 23|8@0+ (1,0) [0|0] ""  PT
 SG_ balancingRequest000_to_007_BMS25 m15 : 63|8@0+ (1,0) [0|0] ""  PT
 SG_ balancingRequest008_to_015_BMS25 m15 : 55|8@0+ (1,0) [0|0] ""  PT
 SG_ balancingRequest016_to_023_BMS25 m15 : 47|8@0+ (1,0) [0|0] ""  PT
 SG_ balancingRequest024_to_031_BMS25 m15 : 39|8@0+ (1,0) [0|0] ""  PT
 SG_ balancingRequest032_to_039_BMS25 m15 : 31|8@0+ (1,0) [0|0] ""  PT
 SG_ balancingRequest040_to_047_BMS25 m15 : 23|8@0+ (1,0) [0|0] ""  PT
 SG_ balancingVoltageTarget_BMS25 m15 : 15|8@0+ (0.02,0) [0|5.1] ""  PT
 SG_ numberOfPacksPerString_BMS25 m4 : 10|3@0+ (1,0) [0|0] ""  PT
 SG_ analogAddr5_BMS25 m1 : 23|8@0+ (0.05,0) [0|12] "V"  PT
 SG_ analogAddr0_BMS25 m1 : 63|8@0+ (0.05,0) [0|12] "V"  PT
 SG_ analogAddr4_BMS25 m1 : 31|8@0+ (0.05,0) [0|12] "V"  PT
 SG_ analogAddr3_BMS25 m1 : 39|8@0+ (0.05,0) [0|12] "V"  PT
 SG_ analogAddr2_BMS25 m1 : 47|8@0+ (0.05,0) [0|12] "V"  PT
 SG_ analogAddr1_BMS25 m1 : 55|8@0+ (0.05,0) [0|12] "V"  PT
 SG_ debugSlowMpex1_BMS25 M : 7|8@0+ (1,0) [0|0] ""  PT
 SG_ analog3V3DSupply_BMS25 m9 : 15|8@0+ (0.015,0) [0|0] "V"  PT
 SG_ pressure_BMS25 m9 : 63|8@0+ (0.4,0) [0|19] "psi"  PT
 SG_ analog3P3VA_BMS25 m9 : 55|8@0+ (0.015,0) [0|3.825] "V"  PT
 SG_ analog5VA_BMS25 m9 : 31|8@0+ (0.025,0) [0|6] "V"  PT
 SG_ analog5VD_BMS25 m9 : 23|8@0+ (0.025,0) [0|6] "V"  PT
 SG_ analog5VSensorSupply_BMS25 m9 : 47|8@0+ (0.025,0) [0|6.375] "V"  PT
 SG_ analog6V5_BMS25 m9 : 39|8@0+ (0.0075,5) [5|6.9125] "V"  PT
 SG_ isolationResistanceIntern_BMS25 m8 : 55|16@0+ (2,0) [0|130000] "kOhm"  PT
 SG_ isolationResistanceExtern_BMS25 m8 : 39|16@0+ (2,0) [0|130000] "kOhm"  PT
 SG_ linkVoltage_BMS25 m8 : 23|16@0+ (0.02,0) [0|1310.7] "V"  PT
 SG_ eepromWriteCyclesBasics_BMS25 m11 : 23|8@0+ (1,0) [0|0] ""  PT
 SG_ eepromBlockIndex_BMS25 m11 : 15|8@0+ (1,0) [0|0] ""  PT
 SG_ CAN1MIATimerISR_BMS25 m7 : 23|8@0+ (1,0) [0|255] ""  PT
 SG_ CAN2MIATimerISR_BMS25 m7 : 31|8@0+ (1,0) [0|255] ""  PT
 SG_ regenCurrentOpLimit_BMS25 m5 : 39|16@0+ (0.05,0) [0|3200] "A"  PT
 SG_ regenCurrentErrorLimit_BMS25 m5 : 23|16@0+ (0.05,0) [0|3200] "A"  PT
 SG_ lifetime_BMS25 m6 : 39|32@0+ (1,0) [0|0] "s"  PT
 SG_ eepromReadTime_BMS25 m0 : 15|8@0+ (10,0) [0|2550] "ms"  PT
 SG_ chargerCurrentOpLimit_BMS25 m4 : 39|16@0+ (0.05,0) [0|3200] "A"  PT
 SG_ dischargeCurrentOpLimit_BMS25 m3 : 39|16@0+ (0.05,-3200) [-3200|0] "A"  PT
 SG_ chargerCurrentErrorLimit_BMS25 m4 : 23|16@0+ (0.05,0) [0|3200] "A"  PT
 SG_ dischargeCurrentErrorLimit_BMS25 m3 : 23|16@0+ (0.05,-3200) [-3200|0] "A"  PT
 SG_ pumpSpeedReqMaxT_BMS25 m2 : 23|8@0+ (1,0) [0|0] "PCT"  PT
 SG_ pumpSpeedReqDeltaT_BMS25 m2 : 31|8@0+ (1,0) [0|0] "PCT"  PT
 SG_ energyThroughput_BMS25 m2 : 39|32@0+ (0.001,0) [0|4294967.295] "kWh"  PT
 SG_ packVoltageCMB_BMS25 m6 : 23|16@0+ (0.02,0) [0|1200] "V"  PT
 SG_ ctrOffTimeLast_BMS25 m0 : 23|16@0+ (1,0) [0|0] "s"  PT
 SG_ ctrOffTime_BMS25 m0 : 39|16@0+ (1,0) [0|0] "s"  PT
 SG_ sleepTime_BMS25 m0 : 55|16@0+ (1,0) [0|0] "s"  PT
 SG_ SPIRxTxTimeAllPckts_BMS25 m10 : 31|8@0+ (2,0) [0|500] "ms"  PT
 SG_ isolationTestState_BMS25 m10 : 17|2@0+ (1,0) [0|0] ""  PT
 SG_ SOCvoltageInit_BMS25 m10 : 21|1@0+ (1,0) [0|1] ""  PT
 SG_ SOCocvInit_BMS25 m10 : 23|1@0+ (1,0) [0|1] ""  PT
 SG_ SOCeepromInit_BMS25 m10 : 22|1@0+ (1,0) [0|1] ""  PT
 SG_ SOCdefaultInit_BMS25 m10 : 20|1@0+ (1,0) [0|1] ""  PT

BO_ 1752 BMS25_DebugFastMpex1: 8 BMS25
 SG_ SPIRxTxHeaderMux3Status_BMS25 m1 : 23|1@0+ (1,0) [0|1] ""  PT
 SG_ SPIRxTxHeaderMux2Status_BMS25 m1 : 22|1@0+ (1,0) [0|1] ""  PT
 SG_ SPIRxTxHeaderMux1Status_BMS25 m1 : 21|1@0+ (1,0) [0|1] ""  PT
 SG_ SPIRxTxHeaderMux0Status_BMS25 m1 : 20|1@0+ (1,0) [0|1] ""  PT
 SG_ activeIsoTestPsbl_BMS25 m0 : 27|1@0+ (1,0) [0|0] ""  PT
 SG_ activeIsoState_BMS25 m3 : 15|8@0+ (1,0) [0|0] ""  PT
 SG_ activeIsoNegLink_BMS25 m3 : 39|16@0+ (0.04,-1250) [-1250|1371.4] "V"  PT
 SG_ activeIsoPosLink_BMS25 m3 : 23|16@0+ (0.04,-1250) [-1250|1371.4] "V"  PT
 SG_ activeIsoTestStateTimer_BMS25 m2 : 15|8@0+ (200,0) [0|51000] "ms"  PT
 SG_ activeIsoPosBuffer_BMS25 m2 : 23|16@0+ (0.04,-1250) [-1250|1371.4] "V"  PT
 SG_ activeIsoNegBuffer_BMS25 m2 : 39|16@0+ (0.04,-1250) [-1250|1371.4] "V"  PT
 SG_ activeIsoResRaw_BMS25 m2 : 55|16@0+ (2,0) [0|130000] "kOhm"  PT
 SG_ activeIsoResFilter_BMS25 m3 : 55|16@0+ (2,0) [0|130000] "kOhm"  PT
 SG_ contactorStateAux_BMS25 m1 : 34|3@0+ (1,0) [0|0] ""  PT
 SG_ batSwitchOpenReqEssMstr_BMS25 m0 : 35|2@0+ (1,0) [0|0] ""  PT
 SG_ packShutdownTarget_BMS25 m1 : 12|2@0+ (1,0) [0|0] ""  PT
 SG_ weldedState_BMS25 m1 : 39|2@0+ (1,0) [0|0] ""  PT
 SG_ DIGIO_GPIO2_ON_BMS25 m1 : 19|1@0+ (1,0) [0|0] ""  PT
 SG_ DIGIO_GPIO1_ON_BMS25 m1 : 18|1@0+ (1,0) [0|0] ""  PT
 SG_ DIGIO_12VCURR_SENSE_ON_BMS25 m1 : 37|1@0+ (1,0) [0|0] ""  PT
 SG_ DIGIO_PSUP_SAFETY_OK_BMS25 m1 : 17|1@0+ (1,0) [0|0] ""  PT
 SG_ contactorStateRq_BMS25 m1 : 36|2@0+ (1,0) [0|0] ""  PT
 SG_ contactorPwrOkToPrechg_BMS25 m1 : 16|1@0+ (1,0) [0|0] ""  PT
 SG_ strMstrStrPrechgState_BMS25 m1 : 58|3@0+ (1,0) [0|0] ""  PT
 SG_ packShutdwnTmrQual_BMS25 m1 : 27|1@0+ (1,0) [0|0] ""  PT
 SG_ packStateRequest_BMS25 m1 : 15|3@0+ (1,0) [0|0] ""  PT
 SG_ packState_BMS25 m1 : 31|4@0+ (1,0) [0|0] ""  PT
 SG_ SPIRxTxTimer_BMS25 m1 : 47|8@0+ (2,0) [0|500] "ms"  PT
 SG_ moduleTMinMaxMeanQual_BMS25 m1 : 26|1@0+ (1,0) [0|0] ""  PT
 SG_ currentQual_BMS25 m1 : 25|1@0+ (1,0) [0|0] ""  PT
 SG_ brickVMinMaxMeanQual_BMS25 m1 : 24|1@0+ (1,0) [0|0] ""  PT
 SG_ negCtr1OnReqASW_BMS25 m1 : 8|1@0+ (1,0) [0|0] ""  PT
 SG_ prechgCtr1OnReqASW_BMS25 m1 : 9|1@0+ (1,0) [0|0] ""  PT
 SG_ posCtr1OnReqASW_BMS25 m1 : 10|1@0+ (1,0) [0|0] ""  PT
 SG_ DIGIO_CNTR_HISIDE_ON_MC_BMS25 m0 : 38|1@0+ (1,0) [0|0] ""  PT
 SG_ DIGIO_CNTR_HISIDE_ON_CHCKD_BMS25 m0 : 37|1@0+ (1,0) [0|0] ""  PT
 SG_ DIGIO_CNTR_CLOSE_OK_CHCKD_BMS25 m0 : 36|1@0+ (1,0) [0|0] ""  PT
 SG_ debugFastMpex1_BMS25 M : 7|8@0+ (1,0) [0|0] ""  PT
 SG_ stateContactorControl_BMS25 m0 : 41|1@0+ (1,0) [0|0] ""  PT
 SG_ stateVoltage_BMS25 m0 : 43|1@0+ (1,0) [0|0] ""  PT
 SG_ stateTemperature_BMS25 m0 : 44|1@0+ (1,0) [0|0] ""  PT
 SG_ stateSelfTest_BMS25 m0 : 45|1@0+ (1,0) [0|0] ""  PT
 SG_ stateHVIL_BMS25 m0 : 46|1@0+ (1,0) [0|0] ""  PT
 SG_ stateCurrent_BMS25 m0 : 47|1@0+ (1,0) [0|0] ""  PT
 SG_ stateCrash_BMS25 m0 : 42|1@0+ (1,0) [0|0] ""  PT
 SG_ stateContactors_BMS25 m0 : 40|1@0+ (1,0) [0|0] ""  PT
 SG_ stateCANRx_BMS25 m0 : 39|1@0+ (1,0) [0|0] ""  PT
 SG_ itemState_BMS25 m0 : 33|2@0+ (1,0) [0|0] ""  PT
 SG_ negLink_BMS25 m0 : 23|8@0+ (10,-1200) [-1200|1350] "V"  PT
 SG_ posLink_BMS25 m0 : 15|8@0+ (10,-1200) [-1200|1350] "V"  PT
 SG_ negPack_BMS25 m0 : 63|8@0+ (10,-1200) [-1200|1350] "V"  PT
 SG_ posPack_BMS25 m0 : 55|8@0+ (10,-1200) [-1200|1350] "V"  PT
 SG_ prechargeState_BMS25 m0 : 31|4@0+ (1,0) [0|0] ""  PT
 SG_ contactorState_BMS25 m0 : 26|3@0+ (1,0) [0|0] ""  PT
 SG_ diagStandbyImmShutdown_BMS25 m1 : 61|1@0+ (1,0) [0|1] ""  PT
 SG_ diagAllOffRequired_BMS25 m1 : 60|1@0+ (1,0) [0|1] ""  PT
 SG_ diagDriveTransitionNotOK_BMS25 m1 : 55|1@0+ (1,0) [0|1] ""  PT
 SG_ diagDriveImmShutdown_BMS25 m1 : 54|1@0+ (1,0) [0|1] ""  PT
 SG_ diagDriveDelShutdown2_BMS25 m1 : 52|1@0+ (1,0) [0|1] ""  PT
 SG_ diagDriveDelShutdown1_BMS25 m1 : 53|1@0+ (1,0) [0|1] ""  PT
 SG_ diagUnused_BMS25 m1 : 59|1@0+ (1,0) [0|1] ""  PT
 SG_ diagChargeTransitionNotOK_BMS25 m1 : 51|1@0+ (1,0) [0|1] ""  PT
 SG_ diagChargeImmShutdown_BMS25 m1 : 50|1@0+ (1,0) [0|1] ""  PT
 SG_ diagAccDelShutdown1_BMS25 m1 : 62|1@0+ (1,0) [0|1] ""  PT
 SG_ diagChargeDelShutdown1_BMS25 m1 : 49|1@0+ (1,0) [0|1] ""  PT
 SG_ diagAccTransitionNotOK_BMS25 m1 : 48|1@0+ (1,0) [0|1] ""  PT
 SG_ diagAccImmShutdown_BMS25 m1 : 63|1@0+ (1,0) [0|1] ""  PT

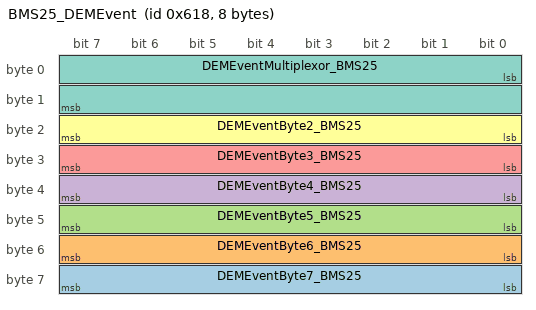
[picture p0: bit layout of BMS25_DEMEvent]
BO_ 1560 BMS25_DEMEvent: 8 BMS25
 SG_ DEMEventByte7_BMS25 : 63|8@0+ (1,0) [0|0] ""  PT
 SG_ DEMEventByte6_BMS25 : 55|8@0+ (1,0) [0|0] ""  PT
 SG_ DEMEventByte5_BMS25 : 47|8@0+ (1,0) [0|0] ""  PT
 SG_ DEMEventByte4_BMS25 : 39|8@0+ (1,0) [0|0] ""  PT
 SG_ DEMEventByte3_BMS25 : 31|8@0+ (1,0) [0|0] ""  PT
 SG_ DEMEventByte2_BMS25 : 23|8@0+ (1,0) [0|0] ""  PT
 SG_ DEMEventMultiplexor_BMS25 M : 0|16@1+ (1,0) [0|0] ""  PT

BO_ 1048 BMS25_DebugEventMap1: 8 BMS25
 SG_ DEM001_POWERUP_BMS25 : 11|2@0+ (1,0) [0|0] ""  PT
 SG_ DEM002_VOLTAGE_BRICK_OV_BMS25 : 13|2@0+ (1,0) [0|0] ""  PT
 SG_ DEM003_VOLTAGE_BRICK_UV_BMS25 : 15|2@0+ (1,0) [0|0] ""  PT
 SG_ DEM004_VOLTAGE_BRICK_SNA_BMS25 : 1|2@0+ (1,0) [0|0] ""  PT
 SG_ DEM005_VOLTAGE_BRICK_IMBAL_BMS25 : 3|2@0+ (1,0) [0|0] ""  PT
 SG_ DEM006_VOLTAGE_CAPCY_IMBAL_BMS25 : 5|2@0+ (1,0) [0|0] ""  PT
 SG_ DEM007_MODULET_HIGH_DELTA_BMS25 : 7|2@0+ (1,0) [0|0] ""  PT
 SG_ DEM008_VOLTAGE_PACK_UV_BMS25 : 25|2@0+ (1,0) [0|0] ""  PT
 SG_ DEM009_VOLTAGE_PACK_OV_BMS25 : 27|2@0+ (1,0) [0|0] ""  PT
 SG_ DEM010_VOLTAGE_PACK_PLAUSI_BMS25 : 29|2@0+ (1,0) [0|0] ""  PT
 SG_ DEM011_VOLTAGE_PCKLINK_MIS_BMS25 : 31|2@0+ (1,0) [0|0] ""  PT
 SG_ DEM012_VOLTAGE_BMS_SUPPLY_BMS25 : 17|2@0+ (1,0) [0|0] ""  PT
 SG_ DEM013_ADC_ERROR_BMS25 : 19|2@0+ (1,0) [0|0] ""  PT
 SG_ DEM014_MODULET_OT_BMS25 : 21|2@0+ (1,0) [0|0] ""  PT
 SG_ DEM015_MODULET_SNA_BMS25 : 23|2@0+ (1,0) [0|0] ""  PT
 SG_ DEM016_MODULET_LIMPHOME_BMS25 : 41|2@0+ (1,0) [0|0] ""  PT
 SG_ DEM017_COOLING_SYS_LHOME_BMS25 : 43|2@0+ (1,0) [0|0] ""  PT
 SG_ DEM018_HVIL_LIMPHOME_BMS25 : 45|2@0+ (1,0) [0|0] ""  PT
 SG_ DEM019_HVIL_ESS_INHIBIT_BMS25 : 47|2@0+ (1,0) [0|0] ""  PT
 SG_ DEM020_MODULET_CHANGE_BMS25 : 33|2@0+ (1,0) [0|0] ""  PT
 SG_ DEM021_LG_MAVD_FAULT_BMS25 : 35|2@0+ (1,0) [0|0] ""  PT
 SG_ DEM022_LG_RDV_FAULT_BMS25 : 37|2@0+ (1,0) [0|0] ""  PT
 SG_ DEM023_BMS_ONBOARDT_SNA_BMS25 : 39|2@0+ (1,0) [0|0] ""  PT
 SG_ DEM024_BMS_ONBOARDRH_OH_BMS25 : 57|2@0+ (1,0) [0|0] ""  PT
 SG_ DEM025_BMS_ONBOARDRH_SNA_BMS25 : 59|2@0+ (1,0) [0|0] ""  PT
 SG_ DEM026_CURRENT_OVERCHARGE_BMS25 : 61|2@0+ (1,0) [0|0] ""  PT
 SG_ DEM027_CURRENT_OVERDISCHGE_BMS25 : 63|2@0+ (1,0) [0|0] ""  PT
 SG_ DEM028_CURRENT_INVALID_BMS25 : 49|2@0+ (1,0) [0|0] ""  PT
 SG_ DEM029_CURRENT_SHORTCIRCT_BMS25 : 51|2@0+ (1,0) [0|0] ""  PT
 SG_ DEM030_CRASH_CAN_LATCH_BMS25 : 53|2@0+ (1,0) [0|0] ""  PT
 SG_ DEM031_EEPROM_FAIL_BMS25 : 55|2@0+ (1,0) [0|0] ""  PT

BO_ 1112 BMS25_DebugEventMap2: 8 BMS25
 SG_ DEM032_PCHG_PACKS_CONNECT_BMS25 : 9|2@0+ (1,0) [0|0] ""  PT
 SG_ DEM033_PCHG_ILLEGAL_PRCHG_BMS25 : 11|2@0+ (1,0) [0|0] ""  PT
 SG_ DEM034_PCHG_RELAY_FAIL_BMS25 : 13|2@0+ (1,0) [0|0] ""  PT
 SG_ DEM035_PCHG_NEG_WELD_BMS25 : 15|2@0+ (1,0) [0|0] ""  PT
 SG_ DEM036_PCHG_NEG_PULLIN_BMS25 : 1|2@0+ (1,0) [0|0] ""  PT
 SG_ DEM037_PCHG_SHORTCIRCUIT_BMS25 : 3|2@0+ (1,0) [0|0] ""  PT
 SG_ DEM038_PCHG_OPENCIRCUIT_BMS25 : 5|2@0+ (1,0) [0|0] ""  PT
 SG_ DEM039_PCHG_TIMEOUT_BMS25 : 7|2@0+ (1,0) [0|0] ""  PT
 SG_ DEM040_PCHG_FAILED_BMS25 : 25|2@0+ (1,0) [0|0] ""  PT
 SG_ DEM041_HVIL_SHUTDOWN_BMS25 : 27|2@0+ (1,0) [0|0] ""  PT
 SG_ DEM042_PCHG_POS_WELD_BMS25 : 29|2@0+ (1,0) [0|0] ""  PT
 SG_ DEM043_HV_LOCK_TRANSPORT_BMS25 : 31|2@0+ (1,0) [0|0] ""  PT
 SG_ DEM044_CTRS_END_OF_LIFE_BMS25 : 17|2@0+ (1,0) [0|0] ""  PT
 SG_ DEM045_CTRS_CTRPWRV_HI_BMS25 : 19|2@0+ (1,0) [0|0] ""  PT
 SG_ DEM046_CTRS_COILCURR_LOW_BMS25 : 21|2@0+ (1,0) [0|0] ""  PT
 SG_ DEM047_CTRS_COILCURR_HIGH_BMS25 : 23|2@0+ (1,0) [0|0] ""  PT
 SG_ DEM048_CTRS_CTRPWRV_LOW_BMS25 : 41|2@0+ (1,0) [0|0] ""  PT
 SG_ DEM049_CHGE_ILLEGAL_DISCHG_BMS25 : 43|2@0+ (1,0) [0|0] ""  PT
 SG_ DEM050_STARTUP_CONDITIONS_BMS25 : 45|2@0+ (1,0) [0|0] ""  PT
 SG_ DEM051_VOLTAGE_BMS_SUPPLYH_BMS25 : 47|2@0+ (1,0) [0|0] ""  PT
 SG_ DEM052_SAFETYSPI_FAIL_BMS25 : 33|2@0+ (1,0) [0|0] ""  PT
 SG_ DEM053_WATCHDOG_ERRORPIN_BMS25 : 35|2@0+ (1,0) [0|0] ""  PT
 SG_ DEM054_SAFESTATE_TRIGGERED_BMS25 : 37|2@0+ (1,0) [0|0] ""  PT
 SG_ DEM055_DEBUG_CMND_ACTIVE_BMS25 : 39|2@0+ (1,0) [0|0] ""  PT
 SG_ DEM056_CRASH_CAN_BMS25 : 57|2@0+ (1,0) [0|0] ""  PT
 SG_ DEM057_ISO_EXT_STRAT_4_BMS25 : 59|2@0+ (1,0) [0|0] ""  PT
 SG_ DEM058_ISO_EXT_RES_ERR_BMS25 : 61|2@0+ (1,0) [0|0] ""  PT
 SG_ DEM059_ISO_EXT_RES_WARN_BMS25 : 63|2@0+ (1,0) [0|0] ""  PT
 SG_ DEM060_ISO_INT_RES_ERR_BMS25 : 49|2@0+ (1,0) [0|0] ""  PT
 SG_ DEM061_ISO_INT_RES_WARN_BMS25 : 51|2@0+ (1,0) [0|0] ""  PT
 SG_ DEM062_EMERGENCY_OPERATION_BMS25 : 53|2@0+ (1,0) [0|0] ""  PT
 SG_ DEM063_ENDOFDRIVE_BMS25 : 55|2@0+ (1,0) [0|0] ""  PT

BO_ 1176 BMS25_DebugEventMap3: 8 BMS25
 SG_ DEM064_STRINGV_IMBALANCE_BMS25 : 9|2@0+ (1,0) [0|0] ""  PT
 SG_ DEM065_STRING_FAULT_BMS25 : 11|2@0+ (1,0) [0|0] ""  PT
 SG_ DEM066_ESS_FAULT_BMS25 : 13|2@0+ (1,0) [0|0] ""  PT
 SG_ DEM067_ISO_EXT_STRAT_3_BMS25 : 15|2@0+ (1,0) [0|0] ""  PT
 SG_ DEM068_MODULE_COUNT_INVALI_BMS25 : 1|2@0+ (1,0) [0|0] ""  PT
 SG_ DEM069_PT_MIA_BMS25 : 3|2@0+ (1,0) [0|0] ""  PT
 SG_ DEM070_BMSMIA_STRNGMSTR_01_BMS25 : 5|2@0+ (1,0) [0|0] ""  PT
 SG_ DEM071_BMSMIA_STRNGMSTR_05_BMS25 : 7|2@0+ (1,0) [0|0] ""  PT
 SG_ DEM072_BMSMIA_STRNGMSTR_09_BMS25 : 25|2@0+ (1,0) [0|0] ""  PT
 SG_ DEM073_BMSMIA_STRNGMSTR_13_BMS25 : 27|2@0+ (1,0) [0|0] ""  PT
 SG_ DEM074_BMSMIA_STRNGMSTR_17_BMS25 : 29|2@0+ (1,0) [0|0] ""  PT
 SG_ DEM075_BMSMIA_STRNGMSTR_21_BMS25 : 31|2@0+ (1,0) [0|0] ""  PT
 SG_ DEM076_BMSMIA_STRNGMSTR_25_BMS25 : 17|2@0+ (1,0) [0|0] ""  PT
 SG_ DEM077_BMSMIA_STRNGMSTR_29_BMS25 : 19|2@0+ (1,0) [0|0] ""  PT
 SG_ DEM078_BMSMIA_STRNGMSTR_33_BMS25 : 21|2@0+ (1,0) [0|0] ""  PT
 SG_ DEM079_BMSMIA_STRNGMSTR_37_BMS25 : 23|2@0+ (1,0) [0|0] ""  PT
 SG_ DEM080_BMSMIA_STRNGMSTR_41_BMS25 : 41|2@0+ (1,0) [0|0] ""  PT
 SG_ DEM081_BMSMIA_STRNGMSTR_45_BMS25 : 43|2@0+ (1,0) [0|0] ""  PT
 SG_ DEM082_BMSMIA_STRNGMSTR_49_BMS25 : 45|2@0+ (1,0) [0|0] ""  PT
 SG_ DEM083_BMSMIA_STRNGMSTR_53_BMS25 : 47|2@0+ (1,0) [0|0] ""  PT
 SG_ DEM084_BMSMIA_STRNGMSTR_57_BMS25 : 33|2@0+ (1,0) [0|0] ""  PT
 SG_ DEM085_BMSMIA_STRNGMSTR_61_BMS25 : 35|2@0+ (1,0) [0|0] ""  PT
 SG_ DEM086_ESSCURRENT_SHORT_BMS25 : 37|2@0+ (1,0) [0|0] ""  PT
 SG_ DEM087_PT_MIA_SHUTDOWN_BMS25 : 39|2@0+ (1,0) [0|0] ""  PT
 SG_ DEM088_OUTLET_NTC_HI_BMS25 : 57|2@0+ (1,0) [0|0] ""  PT
 SG_ DEM089_OUTLET_NTC_LO_BMS25 : 59|2@0+ (1,0) [0|0] ""  PT
 SG_ DEM090_BMSMIA_ESSMASTER_BMS25 : 61|2@0+ (1,0) [0|0] ""  PT
 SG_ DEM091_PCHG_RES_OVERHEAT_BMS25 : 63|2@0+ (1,0) [0|0] ""  PT
 SG_ DEM092_BMSMIA_STRNGSLAVE_0_BMS25 : 49|2@0+ (1,0) [0|0] ""  PT
 SG_ DEM093_BMSMIA_STRNGSLAVE_1_BMS25 : 51|2@0+ (1,0) [0|0] ""  PT
 SG_ DEM094_BMSMIA_STRNGSLAVE_2_BMS25 : 53|2@0+ (1,0) [0|0] ""  PT
 SG_ DEM095_BMSMIA_STRNGSLAVE_3_BMS25 : 55|2@0+ (1,0) [0|0] ""  PT

BO_ 1240 BMS25_DebugEventMap4: 8 BMS25
 SG_ DEM096_SC_STATE_SELFTEST_BMS25 : 9|2@0+ (1,0) [0|0] ""  PT
 SG_ DEM097_SC_STATE_TEMP_BMS25 : 11|2@0+ (1,0) [0|0] ""  PT
 SG_ DEM098_SC_STATE_VOLTAGE_BMS25 : 13|2@0+ (1,0) [0|0] ""  PT
 SG_ DEM099_SC_STATE_HVIL_BMS25 : 15|2@0+ (1,0) [0|0] ""  PT
 SG_ DEM100_SC_STATE_CONTACTORS_BMS25 : 1|2@0+ (1,0) [0|0] ""  PT
 SG_ DEM101_SC_STATE_CURRENT_BMS25 : 3|2@0+ (1,0) [0|0] ""  PT
 SG_ DEM102_SC_STATE_CANRX_BMS25 : 5|2@0+ (1,0) [0|0] ""  PT
 SG_ DEM103_SC_STATE_CRASH_BMS25 : 7|2@0+ (1,0) [0|0] ""  PT
 SG_ DEM104_SC_STATE_CCTRL_BMS25 : 25|2@0+ (1,0) [0|0] ""  PT
 SG_ DEM105_SC_STATE_CANTX_BMS25 : 27|2@0+ (1,0) [0|0] ""  PT
 SG_ DEM106_SC_STATE_THERMALEVT_BMS25 : 29|2@0+ (1,0) [0|0] ""  PT
 SG_ DEM107_SC_STATE_COOLANT_BMS25 : 31|2@0+ (1,0) [0|0] ""  PT
 SG_ DEM108_SC_SELFTEST_SFTY_UC_BMS25 : 17|2@0+ (1,0) [0|0] ""  PT
 SG_ DEM109_SC_TEMP_HIGH_BMS25 : 19|2@0+ (1,0) [0|0] ""  PT
 SG_ DEM110_SC_TEMP_NTC_OPEN_BMS25 : 21|2@0+ (1,0) [0|0] ""  PT
 SG_ DEM111_SC_TEMP_NTC_SHORT_BMS25 : 23|2@0+ (1,0) [0|0] ""  PT
 SG_ DEM112_CMB_DISCONNECTED_BMS25 : 41|2@0+ (1,0) [0|0] ""  PT
 SG_ DEM113_CMB_DEFECT_BMS25 : 43|2@0+ (1,0) [0|0] ""  PT
 SG_ DEM114_CMB_COMMERROR_BMS25 : 45|2@0+ (1,0) [0|0] ""  PT
 SG_ DEM115_SC_CURR_HALL_PWR_LO_BMS25 : 47|2@0+ (1,0) [0|0] ""  PT
 SG_ DEM116_SC_CURR_HALL_VHIGH_BMS25 : 33|2@0+ (1,0) [0|0] ""  PT
 SG_ DEM117_SC_CURR_HALL_ADC_BMS25 : 35|2@0+ (1,0) [0|0] ""  PT
 SG_ DEM118_SC_CURR_HALL_VLOW_BMS25 : 37|2@0+ (1,0) [0|0] ""  PT
 SG_ DEM119_SC_CURR_ISENSE_PWR_BMS25 : 39|2@0+ (1,0) [0|0] ""  PT
 SG_ DEM120_SC_CURR_ISENSE1_MIA_BMS25 : 57|2@0+ (1,0) [0|0] ""  PT
 SG_ DEM121_SC_CURR_ISENSE2_MIA_BMS25 : 59|2@0+ (1,0) [0|0] ""  PT
 SG_ DEM122_SC_CURR_ISENSE3_MIA_BMS25 : 61|2@0+ (1,0) [0|0] ""  PT
 SG_ DEM123_SC_CURR_ISENSE4_MIA_BMS25 : 63|2@0+ (1,0) [0|0] ""  PT
 SG_ DEM124_SC_CURR_ISENSE5_MIA_BMS25 : 49|2@0+ (1,0) [0|0] ""  PT
 SG_ DEM125_SC_CURR_ISENSE1_FLT_BMS25 : 51|2@0+ (1,0) [0|0] ""  PT
 SG_ DEM126_SC_CURR_ISENSE2_FLT_BMS25 : 53|2@0+ (1,0) [0|0] ""  PT
 SG_ DEM127_SC_CURR_ISENSE3_FLT_BMS25 : 55|2@0+ (1,0) [0|0] ""  PT

BO_ 1304 BMS25_DebugEventMap5: 8 BMS25
 SG_ DEM128_SC_CURR_ISENSE4_FLT_BMS25 : 9|2@0+ (1,0) [0|0] ""  PT
 SG_ DEM129_SC_CURR_ISENSE5_FLT_BMS25 : 11|2@0+ (1,0) [0|0] ""  PT
 SG_ DEM130_SC_CURR_OFFSET_BMS25 : 13|2@0+ (1,0) [0|0] ""  PT
 SG_ DEM131_SC_CURR_PLAUSI_BMS25 : 15|2@0+ (1,0) [0|0] ""  PT
 SG_ DEM132_SC_CURR_CHARGE_HIGH_BMS25 : 1|2@0+ (1,0) [0|0] ""  PT
 SG_ DEM133_SC_CURR_DSCHAR_HIGH_BMS25 : 3|2@0+ (1,0) [0|0] ""  PT
 SG_ DEM134_SC_V_CMB_SUMOFCELL_BMS25 : 5|2@0+ (1,0) [0|0] ""  PT
 SG_ DEM135_SC_V_SENSE_OPENWIRE_BMS25 : 7|2@0+ (1,0) [0|0] ""  PT
 SG_ DEM136_SC_V_CMB_DRV_FROZEN_BMS25 : 25|2@0+ (1,0) [0|0] ""  PT
 SG_ DEM137_SC_V_PACK_PLAUSI_BMS25 : 27|2@0+ (1,0) [0|0] ""  PT
 SG_ DEM138_SC_HVIL_HW_FLT_BMS25 : 29|2@0+ (1,0) [0|0] ""  PT
 SG_ DEM139_SC_HVIL_OPEN_BMS25 : 31|2@0+ (1,0) [0|0] ""  PT
 SG_ DEM140_SC_HVIL_TO_SUP_BMS25 : 17|2@0+ (1,0) [0|0] ""  PT
 SG_ DEM141_SC_HVIL_TO_CHAS_BMS25 : 19|2@0+ (1,0) [0|0] ""  PT
 SG_ DEM142_SC_HVIL_R_HIGH_BMS25 : 21|2@0+ (1,0) [0|0] ""  PT
 SG_ DEM143_SC_HVIL_SHORT_BMS25 : 23|2@0+ (1,0) [0|0] ""  PT
 SG_ DEM144_SC_CN_ISO_FAIL_BMS25 : 41|2@0+ (1,0) [0|0] ""  PT
 SG_ DEM145_HVIL_SYS_BMS25 : 43|2@0+ (1,0) [0|0] ""  PT
 SG_ DEM146_SC_CN_POS1_WELDED_BMS25 : 45|2@0+ (1,0) [0|0] ""  PT
 SG_ DEM147_SC_CN_NEG1_WELDED_BMS25 : 47|2@0+ (1,0) [0|0] ""  PT
 SG_ DEM148_SC_CN_POS2_WELDED_BMS25 : 33|2@0+ (1,0) [0|0] ""  PT
 SG_ DEM149_SC_CN_NEG2_WELDED_BMS25 : 35|2@0+ (1,0) [0|0] ""  PT
 SG_ DEM150_SC_CN_POS3_WELDED_BMS25 : 37|2@0+ (1,0) [0|0] ""  PT
 SG_ DEM151_SC_CN_NEG3_WELDED_BMS25 : 39|2@0+ (1,0) [0|0] ""  PT
 SG_ DEM152_SC_CN_HIGH_CY_BMS25 : 57|2@0+ (1,0) [0|0] ""  PT
 SG_ DEM153_SC_CN_ISOANDPOTWELD_BMS25 : 59|2@0+ (1,0) [0|0] ""  PT
 SG_ DEM154_SC_TEMP_PLAUSI_BMS25 : 61|2@0+ (1,0) [0|0] ""  PT
 SG_ DEM155_SC_CURR_HALL_PWR_HI_BMS25 : 63|2@0+ (1,0) [0|0] ""  PT
 SG_ DEM156_SC_PYRO_TRIGGERED_BMS25 : 49|2@0+ (1,0) [0|0] ""  PT
 SG_ DEM157_SC_PYRO_OPEN_BMS25 : 51|2@0+ (1,0) [0|0] ""  PT
 SG_ DEM158_AUX_CTRS_END_OF_LIF_BMS25 : 53|2@0+ (1,0) [0|0] ""  PT
 SG_ DEM159_SC_CANRX_PT_MIA_BMS25 : 55|2@0+ (1,0) [0|0] ""  PT

BO_ 1368 BMS25_DebugEventMap6: 8 BMS25
 SG_ DEM160_SC_CANRX_PT_CRCALIV_BMS25 : 9|2@0+ (1,0) [0|0] ""  PT
 SG_ DEM161_SC_CANRX_LIN_SHUTDN_BMS25 : 11|2@0+ (1,0) [0|0] ""  PT
 SG_ DEM162_SC_CANRX_LIN_MIA_BMS25 : 13|2@0+ (1,0) [0|0] ""  PT
 SG_ DEM163_SC_CRASH1_BMS25 : 15|2@0+ (1,0) [0|0] ""  PT
 SG_ DEM164_SC_CRASH2_BMS25 : 1|2@0+ (1,0) [0|0] ""  PT
 SG_ DEM165_SC_CRASHCAN_BMS25 : 3|2@0+ (1,0) [0|0] ""  PT
 SG_ DEM166_SC_CCTRL_SELFTEST_BMS25 : 5|2@0+ (1,0) [0|0] ""  PT
 SG_ DEM167_SC_CCTRL_DRIVER_FAU_BMS25 : 7|2@0+ (1,0) [0|0] ""  PT
 SG_ DEM168_SC_CCTRL_HISIDESTCL_BMS25 : 25|2@0+ (1,0) [0|0] ""  PT
 SG_ DEM169_SC_CCTRL_HISIDESTOP_BMS25 : 27|2@0+ (1,0) [0|0] ""  PT
 SG_ DEM170_SC_CCTRL_LOSIDESTCL_BMS25 : 29|2@0+ (1,0) [0|0] ""  PT
 SG_ DEM171_SC_CCTRL_HVCNDITION_BMS25 : 31|2@0+ (1,0) [0|0] ""  PT
 SG_ DEM172_SC_CCTRL_POS1_OPN_BMS25 : 17|2@0+ (1,0) [0|0] ""  PT
 SG_ DEM173_SC_CCTRL_POS2_OPN_BMS25 : 19|2@0+ (1,0) [0|0] ""  PT
 SG_ DEM174_SC_CCTRL_POS3_OPN_BMS25 : 21|2@0+ (1,0) [0|0] ""  PT
 SG_ DEM175_SC_CCTRL_NEG1_OPN_BMS25 : 23|2@0+ (1,0) [0|0] ""  PT
 SG_ DEM176_SC_CCTRL_NEG2_OPN_BMS25 : 41|2@0+ (1,0) [0|0] ""  PT
 SG_ DEM177_SC_CCTRL_PRE2_OPN_BMS25 : 43|2@0+ (1,0) [0|0] ""  PT
 SG_ DEM178_SC_CCTRL_PRE1_OPN_BMS25 : 45|2@0+ (1,0) [0|0] ""  PT
 SG_ DEM179_SC_CCTRL_LOSIDESTOP_BMS25 : 47|2@0+ (1,0) [0|0] ""  PT
 SG_ DEM180_SC_CCTRL_UNEXPECTED_BMS25 : 33|2@0+ (1,0) [0|0] ""  PT
 SG_ DEM181_SC_V_OUT_OF_RANGE_BMS25 : 35|2@0+ (1,0) [0|0] ""  PT
 SG_ DEM182_SC_V_LATCHED_UVOV_BMS25 : 37|2@0+ (1,0) [0|0] ""  PT
 SG_ DEM183_ISO_EXT_STRAT_2_BMS25 : 39|2@0+ (1,0) [0|0] ""  PT
 SG_ DEM184_SC_CANTX_CTRS_BMS25 : 57|2@0+ (1,0) [0|0] ""  PT
 SG_ DEM185_SC_CANTX_HVIL_BMS25 : 59|2@0+ (1,0) [0|0] ""  PT
 SG_ DEM186_SC_CANTX_ISOL_BMS25 : 61|2@0+ (1,0) [0|0] ""  PT
 SG_ DEM187_SC_SBC_WATCHDOG_BMS25 : 63|2@0+ (1,0) [0|0] ""  PT
 SG_ DEM188_SC_SBC_FAULT_BMS25 : 49|2@0+ (1,0) [0|0] ""  PT
 SG_ DEM189_SC_WATCHDOG_BMS25 : 51|2@0+ (1,0) [0|0] ""  PT
 SG_ DEM190_SC_SELFTEST_RAM_BMS25 : 53|2@0+ (1,0) [0|0] ""  PT
 SG_ DEM191_SC_SELFTEST_FLASH_BMS25 : 55|2@0+ (1,0) [0|0] ""  PT

BO_ 1432 BMS25_DebugEventMap7: 8 BMS25
 SG_ DEM192_CMB_ONBOARDRH_OH_BMS25 : 9|2@0+ (1,0) [0|0] ""  PT
 SG_ DEM193_CMB_ONBOARDRH_SNA_BMS25 : 11|2@0+ (1,0) [0|0] ""  PT
 SG_ DEM194_CMB_ONBOARDT_OT_BMS25 : 13|2@0+ (1,0) [0|0] ""  PT
 SG_ DEM195_CMB_ONBOARDT_CHANGE_BMS25 : 15|2@0+ (1,0) [0|0] ""  PT
 SG_ DEM196_PRESSURE_CHANGE_BMS25 : 1|2@0+ (1,0) [0|0] ""  PT
 SG_ DEM197_PRESSURE_OVER_BMS25 : 3|2@0+ (1,0) [0|0] ""  PT
 SG_ DEM198_PRESSURE_UNDER_BMS25 : 5|2@0+ (1,0) [0|0] ""  PT
 SG_ DEM199_PRESSURE_INVALID_BMS25 : 7|2@0+ (1,0) [0|0] ""  PT
 SG_ DEM200_THERMAL_EVENT_BMS25 : 25|2@0+ (1,0) [0|0] ""  PT
 SG_ DEM201_CMB_ONBOARDT_SNA_BMS25 : 27|2@0+ (1,0) [0|0] ""  PT
 SG_ DEM202_REPLACE_DESICCANT_BMS25 : 29|2@0+ (1,0) [0|0] ""  PT
 SG_ DEM203_COOLANT_FLOOD_FAULT_BMS25 : 31|2@0+ (1,0) [0|0] ""  PT
 SG_ DEM204_LOW_BRICKCAPACITY_BMS25 : 17|2@0+ (1,0) [0|0] ""  PT
 SG_ DEM205_BMS_ONBOARDT_OT_BMS25 : 19|2@0+ (1,0) [0|0] ""  PT
 SG_ DEM206_HUMIDITY_CHANGE_BMS25 : 21|2@0+ (1,0) [0|0] ""  PT
 SG_ DEM207_ISENSE_SUPPLY_CURR_BMS25 : 23|2@0+ (1,0) [0|0] ""  PT
 SG_ DEM208_SOC_LOW_BMS25 : 41|2@0+ (1,0) [0|0] ""  PT
 SG_ DEM209_SOC_TOOLOW_BMS25 : 43|2@0+ (1,0) [0|0] ""  PT
 SG_ DEM210_SOC_TOOHIGH_BMS25 : 45|2@0+ (1,0) [0|0] ""  PT
 SG_ DEM211_BALANCING_REQUIRED_BMS25 : 47|2@0+ (1,0) [0|0] ""  PT
 SG_ DEM212_DEEP_DISCHARGE_BMS25 : 33|2@0+ (1,0) [0|0] ""  PT
 SG_ DEM213_CAN1_BUS_OFF_BMS25 : 35|2@0+ (1,0) [0|0] ""  PT
 SG_ DEM214_CAN2_BUS_OFF_BMS25 : 37|2@0+ (1,0) [0|0] ""  PT
 SG_ DEM215_CAN3_BUS_OFF_BMS25 : 39|2@0+ (1,0) [0|0] ""  PT
 SG_ DEM216_OUTLET_NTC_RATNAL_BMS25 : 57|2@0+ (1,0) [0|0] ""  PT
 SG_ DEM217_FUSE_PACK_BMS25 : 59|2@0+ (1,0) [0|0] ""  PT
 SG_ DEM218_FUSE_B_OPEN_BMS25 : 61|2@0+ (1,0) [0|0] ""  PT
 SG_ DEM219_FUSE_C_OPEN_BMS25 : 63|2@0+ (1,0) [0|0] ""  PT
 SG_ DEM220_FUSE_D_OPEN_BMS25 : 49|2@0+ (1,0) [0|0] ""  PT
 SG_ DEM221_FUSE_E_OPEN_BMS25 : 51|2@0+ (1,0) [0|0] ""  PT
 SG_ DEM222_PUMP_DRY_RUN_BMS25 : 53|2@0+ (1,0) [0|0] ""  PT
 SG_ DEM223_PUMP_PERFORMANCE_BMS25 : 55|2@0+ (1,0) [0|0] ""  PT

BO_ 1496 BMS25_DebugEventMap8: 8 BMS25
 SG_ DEM224_PUMP_LIN_FAILURE_BMS25 : 9|2@0+ (1,0) [0|0] ""  PT
 SG_ DEM225_PUMP_SUPPLY_VOLTAGE_BMS25 : 11|2@0+ (1,0) [0|0] ""  PT
 SG_ DEM226_PUMP_RECOVERY_FAIL_BMS25 : 13|2@0+ (1,0) [0|0] ""  PT
 SG_ DEM227_CTR_POS_OPENED_BMS25 : 15|2@0+ (1,0) [0|0] ""  PT
 SG_ DEM228_CTR_NEG_OPENED_BMS25 : 1|2@0+ (1,0) [0|0] ""  PT
 SG_ DEM229_STRSET_SLAVE1_FAULT_BMS25 : 3|2@0+ (1,0) [0|0] ""  PT
 SG_ DEM230_STRSET_SLAVE2_FAULT_BMS25 : 5|2@0+ (1,0) [0|0] ""  PT
 SG_ DEM231_CTRSAUX_CLFAIL_HVON_BMS25 : 7|2@0+ (1,0) [0|0] ""  PT
 SG_ DEM232_CTRSAUX_CLFAIL_VDIF_BMS25 : 25|2@0+ (1,0) [0|0] ""  PT
 SG_ DEM233_CTRSAUX_POS1_OPENED_BMS25 : 27|2@0+ (1,0) [0|0] ""  PT
 SG_ DEM234_CTRSAUX_NEG1_OPENED_BMS25 : 29|2@0+ (1,0) [0|0] ""  PT
 SG_ DEM235_CTRSAUX_POS1_WELDED_BMS25 : 31|2@0+ (1,0) [0|0] ""  PT
 SG_ DEM236_CTRSAUX_NEG1_WELDED_BMS25 : 17|2@0+ (1,0) [0|0] ""  PT
 SG_ DEM237_CTRSAUX_POS1_PULLIN_BMS25 : 19|2@0+ (1,0) [0|0] ""  PT
 SG_ DEM238_CTRSAUX_NEG1_PULLIN_BMS25 : 21|2@0+ (1,0) [0|0] ""  PT
 SG_ DEM239_INLET_NTC_RATNAL_BMS25 : 23|2@0+ (1,0) [0|0] ""  PT
 SG_ DEM240_INLET_NTC_HI_BMS25 : 41|2@0+ (1,0) [0|0] ""  PT
 SG_ DEM241_INLET_NTC_LO_BMS25 : 43|2@0+ (1,0) [0|0] ""  PT
 SG_ DEM242_VOLTAGE_LINK2_RATNA_BMS25 : 45|2@0+ (1,0) [0|0] ""  PT
 SG_ DEM243_VOLTAGE_LINK2_HI_BMS25 : 47|2@0+ (1,0) [0|0] ""  PT
 SG_ DEM244_VOLTAGE_LINK2_LO_BMS25 : 33|2@0+ (1,0) [0|0] ""  PT
 SG_ DEM245_CMB_ONBOARD_IMPOSSI_BMS25 : 35|2@0+ (1,0) [0|0] ""  PT
 SG_ DEM246_VOLTAGE_LINK1_HI_BMS25 : 37|2@0+ (1,0) [0|0] ""  PT
 SG_ DEM247_VOLTAGE_LINK1_LO_BMS25 : 39|2@0+ (1,0) [0|0] ""  PT
 SG_ DEM248_NTC_SUPPLY_LO_BMS25 : 57|2@0+ (1,0) [0|0] ""  PT
 SG_ DEM249_NTC_SUPPLY_HI_BMS25 : 59|2@0+ (1,0) [0|0] ""  PT
 SG_ DEM250_VOLTAGE_LINK3_RATNA_BMS25 : 61|2@0+ (1,0) [0|0] ""  PT
 SG_ DEM251_VOLTAGE_LINK3_HI_BMS25 : 63|2@0+ (1,0) [0|0] ""  PT
 SG_ DEM252_VOLTAGE_LINK3_LO_BMS25 : 49|2@0+ (1,0) [0|0] ""  PT
 SG_ DEM253_BALANCING_STUCK_BMS25 : 51|2@0+ (1,0) [0|0] ""  PT
 SG_ DEM254_ARM_EXCEPTION_BMS25 : 53|2@0+ (1,0) [0|0] ""  PT
 SG_ DEM255_ERROR_HOOKS_BMS25 : 55|2@0+ (1,0) [0|0] ""  PT

BO_ 856 BMS25_DebugEventMap9: 8 BMS25
 SG_ DEM256_XCP_CAL_CHANGE_BMS25 : 9|2@0+ (1,0) [0|0] ""  PT
 SG_ DEM257_XCP_CAL_PERM_CHANGE_BMS25 : 11|2@0+ (1,0) [0|0] ""  PT
 SG_ DEM258_TASK_TIME_OVERFLOW_BMS25 : 13|2@0+ (1,0) [0|0] ""  PT
 SG_ DEM259_ISO_CIRCUIT_BMS25 : 15|2@0+ (1,0) [0|0] ""  PT
 SG_ DEM260_COOLANT_MOIST_FAULT_BMS25 : 1|2@0+ (1,0) [0|0] ""  PT
 SG_ DEM261_COOLANT_FLOOD_WARN_BMS25 : 3|2@0+ (1,0) [0|0] ""  PT
 SG_ DEM262_COOLANT_MOIST_WARN_BMS25 : 5|2@0+ (1,0) [0|0] ""  PT
 SG_ DEM263_MODULET_IMPLAUSIBLE_BMS25 : 7|2@0+ (1,0) [0|0] ""  PT
 SG_ DEM264_REQUEST_ON_WITH_HV__BMS25 : 25|2@0+ (1,0) [0|0] ""  PT
 SG_ DEM265_CSERS_PCODE_BMS25 : 27|2@0+ (1,0) [0|0] ""  PT
 SG_ DEM266_PRELIM_CNTR_CL_FAIL_BMS25 : 29|2@0+ (1,0) [0|0] ""  PT
 SG_ DEM267_FLUIDLVL_LOW_BMS25 : 31|2@0+ (1,0) [0|0] ""  PT
 SG_ DEM268_FLUIDLVL_FAILURE_BMS25 : 17|2@0+ (1,0) [0|0] ""  PT
 SG_ DEM269_SC_COOLANT_CONTAM_BMS25 : 19|2@0+ (1,0) [0|0] ""  PT
 SG_ DEM270_SC_COOLANT_MIA_BMS25 : 21|2@0+ (1,0) [0|0] ""  PT
 SG_ DEM271_PRESSURE_VHI_BMS25 : 23|2@0+ (1,0) [0|0] ""  PT
 SG_ DEM272_PRESSURE_VLO_BMS25 : 41|2@0+ (1,0) [0|0] ""  PT
 SG_ DEM273_SC_COOLANT_FAIL_BMS25 : 43|2@0+ (1,0) [0|0] ""  PT
 SG_ DEM274_CTRSAUX_POS2_OPENED_BMS25 : 45|2@0+ (1,0) [0|0] ""  PT
 SG_ DEM275_CTRSAUX_POS3_OPENED_BMS25 : 47|2@0+ (1,0) [0|0] ""  PT
 SG_ DEM276_CTRSAUX_POS2_WELDED_BMS25 : 33|2@0+ (1,0) [0|0] ""  PT
 SG_ DEM277_CTRSAUX_POS3_WELDED_BMS25 : 35|2@0+ (1,0) [0|0] ""  PT
 SG_ DEM278_CTRSAUX_POS2_PULLIN_BMS25 : 37|2@0+ (1,0) [0|0] ""  PT
 SG_ DEM279_CTRSAUX_POS3_PULLIN_BMS25 : 39|2@0+ (1,0) [0|0] ""  PT
 SG_ DEM280_CMB_HUMIDITY_TEMP_C_BMS25 : 57|2@0+ (1,0) [0|0] ""  PT
 SG_ DEM281_THERMAL_EVENT_CMB_R_BMS25 : 59|2@0+ (1,0) [0|0] ""  PT
 SG_ DEM282_CUS_BRICKOV_BMS25 : 61|2@0+ (1,0) [0|0] ""  PT
 SG_ DEM283_CUS_BRICKUV_BMS25 : 63|2@0+ (1,0) [0|0] ""  PT
 SG_ DEM284_CUS_OVERCHRG_BMS25 : 49|2@0+ (1,0) [0|0] ""  PT
 SG_ DEM285_CUS_OVERDCHRG_BMS25 : 51|2@0+ (1,0) [0|0] ""  PT
 SG_ DEM286_CUS_CURRENT_CHG_BMS25 : 53|2@0+ (1,0) [0|0] ""  PT
 SG_ DEM287_CUS_CURRENT_DCHG_BMS25 : 55|2@0+ (1,0) [0|0] ""  PT

BA_DEF_ SG_  "GenSigSendType" ENUM  "Cyclic","OnWrite","OnWriteWithRepetition","OnChange","OnChangeWithRepetition","IfActive","IfActiveWithRepetition","NoSigSendType";
BA_DEF_ BO_  "GenMsgCycleTime" INT 0 0;
BA_DEF_ BO_  "GenMsgSendType" ENUM  "Cyclic","not_used","not_used","not_used","not_used","Cyclic","not_used","IfActive","NoMsgSendType";
BA_DEF_DEF_  "GenSigSendType" "Cyclic";
BA_DEF_DEF_  "GenMsgCycleTime" 0;
BA_DEF_DEF_  "GenMsgSendType" "NoMsgSendType";
BA_ "GenMsgCycleTime" BO_ 2005 100;
BA_ "GenMsgCycleTime" BO_ 984 1000;
BA_ "GenMsgCycleTime" BO_ 1816 100;
BA_ "GenMsgCycleTime" BO_ 1880 1000;
BA_ "GenMsgCycleTime" BO_ 1752 100;
BA_ "GenMsgCycleTime" BO_ 1048 1000;
BA_ "GenMsgCycleTime" BO_ 1112 1000;
BA_ "GenMsgCycleTime" BO_ 1176 1000;
BA_ "GenMsgCycleTime" BO_ 1240 1000;
BA_ "GenMsgCycleTime" BO_ 1304 1000;
BA_ "GenMsgCycleTime" BO_ 1368 1000;
BA_ "GenMsgCycleTime" BO_ 1432 1000;
BA_ "GenMsgCycleTime" BO_ 1496 1000;
VAL_ 2005 cmbMultiplexor_BMS22 0 "C000" 1 "C001" 2 "C002" 3 "C003" 4 "C004" 5 "C005" 6 "C006" 7 "C007" 8 "C008" 9 "C009" 10 "C010" 11 "C011" 12 "C012" 13 "C013" 14 "C014" 15 "C015" 16 "C016" 17 "C017" 18 "C018" 19 "C019" 20 "C020" 21 "C021" 22 "C022" 23 "C023" 24 "C024" 25 "C025" 26 "C026" 27 "C027" 28 "C028" 29 "C029" 30 "C030" 31 "C031" 32 "C032" 33 "C033" 34 "C034" 35 "C035" 36 "C036" 37 "C037" 38 "C038" 39 "C039" 40 "C040" 41 "C041" 42 "C042" 43 "C043" 44 "C044" 45 "C045" 46 "C046" 47 "C047" 48 "C048" 49 "C049" 50 "C050" 51 "C051" 52 "C052" 53 "C053" 54 "C054" 55 "C055" 56 "C056" 57 "C057" 58 "C058" 59 "C059" 60 "C060" 61 "C061" 62 "C062" 63 "C063" 64 "C064" 65 "C065" 66 "C066" 67 "C067" 68 "C068" 69 "C069" 70 "C070" 71 "C071" 72 "C072" 73 "C073" 74 "C074" 75 "C075" 76 "C076" 77 "C077" 78 "C078" 79 "C079" 80 "C080" 81 "C081" 82 "C082" 83 "C083" 84 "C084" 85 "C085" 86 "C086" 87 "C087" 88 "C088" 89 "C089" 90 "C090" 91 "C091" 92 "C092" 93 "C093" 94 "C094" 95 "C095" 96 "C096" 97 "C097" 98 "C098" 99 "C099" 100 "C100" 101 "C101" 102 "C102" 103 "C103" 104 "C104" 105 "C105" 106 "C106" 107 "C107" 108 "C108" 109 "C109" 110 "C110" 111 "C111" 112 "C112" 113 "C113" 114 "C114" 115 "C115" 116 "C116" 117 "C117" 118 "C118" 119 "C119" 120 "C120" 121 "C121" 122 "C122" 123 "C123" 124 "C124" 125 "C125" 126 "C126" 127 "C127" 128 "C128" 129 "C129" 130 "C130" 131 "C131" 132 "C132" 133 "C133" 134 "C134" 135 "C135" 136 "C136" 137 "C137" 138 "C138" 139 "C139" 140 "C140" 141 "C141" 142 "C142" 143 "C143" 144 "C144" 145 "C145" 146 "C146" 147 "C147" 148 "C148" 149 "C149" 150 "C150" 151 "C151" 152 "C152" 153 "C153" 154 "C154" 155 "C155" 156 "C156" 157 "C157" 158 "C158" 159 "C159" 160 "C160" 161 "C161" 162 "C162" 163 "C163" 164 "C164" 165 "C165" 166 "C166" 167 "C167" 168 "C168" 169 "C169" 170 "C170" 171 "C171" 172 "C172" 173 "C173" 174 "C174" 175 "C175" 176 "C176" 177 "C177" 178 "C178" 179 "C179" 180 "C180" 181 "C181" 182 "C182" 183 "C183" 184 "C184" 185 "C185" 186 "C186" 187 "C187" 188 "C188" 189 "C189" 190 "C190" 191 "C191" 192 "C192" ;
VAL_ 2005 moduleTemperature01_BMS22 255 "SNA" ;
VAL_ 2005 brickVoltage001_BMS22 65535 "SNA" ;
VAL_ 2005 brickVoltage002_BMS22 65535 "SNA" ;
VAL_ 2005 brickVoltage003_BMS22 65535 "SNA" ;
VAL_ 2005 moduleTemperature02_BMS22 255 "SNA" ;
VAL_ 2005 brickVoltage004_BMS22 65535 "SNA" ;
VAL_ 2005 brickVoltage005_BMS22 65535 "SNA" ;
VAL_ 2005 brickVoltage006_BMS22 65535 "SNA" ;
VAL_ 2005 moduleTemperature03_BMS22 255 "SNA" ;
VAL_ 2005 brickVoltage007_BMS22 65535 "SNA" ;
VAL_ 2005 brickVoltage008_BMS22 65535 "SNA" ;
VAL_ 2005 brickVoltage009_BMS22 65535 "SNA" ;
VAL_ 2005 moduleTemperature04_BMS22 255 "SNA" ;
VAL_ 2005 brickVoltage010_BMS22 65535 "SNA" ;
VAL_ 2005 brickVoltage011_BMS22 65535 "SNA" ;
VAL_ 2005 brickVoltage012_BMS22 65535 "SNA" ;
VAL_ 2005 moduleTemperature05_BMS22 255 "SNA" ;
VAL_ 2005 brickVoltage013_BMS22 65535 "SNA" ;
VAL_ 2005 brickVoltage014_BMS22 65535 "SNA" ;
VAL_ 2005 brickVoltage015_BMS22 65535 "SNA" ;
VAL_ 2005 moduleTemperature06_BMS22 255 "SNA" ;
VAL_ 2005 brickVoltage016_BMS22 65535 "SNA" ;
VAL_ 2005 brickVoltage017_BMS22 65535 "SNA" ;
VAL_ 2005 brickVoltage018_BMS22 65535 "SNA" ;
VAL_ 2005 moduleTemperature07_BMS22 255 "SNA" ;
VAL_ 2005 brickVoltage019_BMS22 65535 "SNA" ;
VAL_ 2005 brickVoltage020_BMS22 65535 "SNA" ;
VAL_ 2005 brickVoltage021_BMS22 65535 "SNA" ;
VAL_ 2005 moduleTemperature08_BMS22 255 "SNA" ;
VAL_ 2005 brickVoltage022_BMS22 65535 "SNA" ;
VAL_ 2005 brickVoltage023_BMS22 65535 "SNA" ;
VAL_ 2005 brickVoltage024_BMS22 65535 "SNA" ;
VAL_ 2005 moduleTemperature09_BMS22 255 "SNA" ;
VAL_ 2005 brickVoltage025_BMS22 65535 "SNA" ;
VAL_ 2005 brickVoltage026_BMS22 65535 "SNA" ;
VAL_ 2005 brickVoltage027_BMS22 65535 "SNA" ;
VAL_ 2005 moduleTemperature10_BMS22 255 "SNA" ;
VAL_ 2005 brickVoltage028_BMS22 65535 "SNA" ;
VAL_ 2005 brickVoltage029_BMS22 65535 "SNA" ;
VAL_ 2005 brickVoltage030_BMS22 65535 "SNA" ;
VAL_ 2005 moduleTemperature11_BMS22 255 "SNA" ;
VAL_ 2005 brickVoltage031_BMS22 65535 "SNA" ;
VAL_ 2005 brickVoltage032_BMS22 65535 "SNA" ;
VAL_ 2005 brickVoltage033_BMS22 65535 "SNA" ;
VAL_ 2005 moduleTemperature12_BMS22 255 "SNA" ;
VAL_ 2005 brickVoltage034_BMS22 65535 "SNA" ;
VAL_ 2005 brickVoltage035_BMS22 65535 "SNA" ;
VAL_ 2005 brickVoltage036_BMS22 65535 "SNA" ;
VAL_ 2005 moduleTemperature13_BMS22 255 "SNA" ;
VAL_ 2005 brickVoltage037_BMS22 65535 "SNA" ;
VAL_ 2005 brickVoltage038_BMS22 65535 "SNA" ;
VAL_ 2005 brickVoltage039_BMS22 65535 "SNA" ;
VAL_ 2005 moduleTemperature14_BMS22 255 "SNA" ;
VAL_ 2005 brickVoltage040_BMS22 65535 "SNA" ;
VAL_ 2005 brickVoltage041_BMS22 65535 "SNA" ;
VAL_ 2005 brickVoltage042_BMS22 65535 "SNA" ;
VAL_ 2005 moduleTemperature15_BMS22 255 "SNA" ;
VAL_ 2005 brickVoltage043_BMS22 65535 "SNA" ;
VAL_ 2005 brickVoltage044_BMS22 65535 "SNA" ;
VAL_ 2005 brickVoltage045_BMS22 65535 "SNA" ;
VAL_ 2005 moduleTemperature16_BMS22 255 "SNA" ;
VAL_ 2005 brickVoltage046_BMS22 65535 "SNA" ;
VAL_ 2005 brickVoltage047_BMS22 65535 "SNA" ;
VAL_ 2005 brickVoltage048_BMS22 65535 "SNA" ;
VAL_ 2005 moduleTemperature17_BMS22 255 "SNA" ;
VAL_ 2005 brickVoltage049_BMS22 65535 "SNA" ;
VAL_ 2005 brickVoltage050_BMS22 65535 "SNA" ;
VAL_ 2005 brickVoltage051_BMS22 65535 "SNA" ;
VAL_ 2005 moduleTemperature18_BMS22 255 "SNA" ;
VAL_ 2005 brickVoltage052_BMS22 65535 "SNA" ;
VAL_ 2005 brickVoltage053_BMS22 65535 "SNA" ;
VAL_ 2005 brickVoltage054_BMS22 65535 "SNA" ;
VAL_ 2005 moduleTemperature19_BMS22 255 "SNA" ;
VAL_ 2005 brickVoltage055_BMS22 65535 "SNA" ;
VAL_ 2005 brickVoltage056_BMS22 65535 "SNA" ;
VAL_ 2005 brickVoltage057_BMS22 65535 "SNA" ;
VAL_ 2005 moduleTemperature20_BMS22 255 "SNA" ;
VAL_ 2005 brickVoltage058_BMS22 65535 "SNA" ;
VAL_ 2005 brickVoltage059_BMS22 65535 "SNA" ;
VAL_ 2005 brickVoltage060_BMS22 65535 "SNA" ;
VAL_ 2005 moduleTemperature21_BMS22 255 "SNA" ;
VAL_ 2005 brickVoltage061_BMS22 65535 "SNA" ;
VAL_ 2005 brickVoltage062_BMS22 65535 "SNA" ;
VAL_ 2005 brickVoltage063_BMS22 65535 "SNA" ;
VAL_ 2005 moduleTemperature22_BMS22 255 "SNA" ;
VAL_ 2005 brickVoltage064_BMS22 65535 "SNA" ;
VAL_ 2005 brickVoltage065_BMS22 65535 "SNA" ;
VAL_ 2005 brickVoltage066_BMS22 65535 "SNA" ;
VAL_ 2005 moduleTemperature23_BMS22 255 "SNA" ;
VAL_ 2005 brickVoltage067_BMS22 65535 "SNA" ;
VAL_ 2005 brickVoltage068_BMS22 65535 "SNA" ;
VAL_ 2005 brickVoltage069_BMS22 65535 "SNA" ;
VAL_ 2005 moduleTemperature24_BMS22 255 "SNA" ;
VAL_ 2005 brickVoltage070_BMS22 65535 "SNA" ;
VAL_ 2005 brickVoltage071_BMS22 65535 "SNA" ;
VAL_ 2005 brickVoltage072_BMS22 65535 "SNA" ;
VAL_ 2005 moduleTemperature25_BMS22 255 "SNA" ;
VAL_ 2005 brickVoltage073_BMS22 65535 "SNA" ;
VAL_ 2005 brickVoltage074_BMS22 65535 "SNA" ;
VAL_ 2005 brickVoltage075_BMS22 65535 "SNA" ;
VAL_ 2005 moduleTemperature26_BMS22 255 "SNA" ;
VAL_ 2005 brickVoltage076_BMS22 65535 "SNA" ;
VAL_ 2005 brickVoltage077_BMS22 65535 "SNA" ;
VAL_ 2005 brickVoltage078_BMS22 65535 "SNA" ;
VAL_ 2005 moduleTemperature27_BMS22 255 "SNA" ;
VAL_ 2005 brickVoltage079_BMS22 65535 "SNA" ;
VAL_ 2005 brickVoltage080_BMS22 65535 "SNA" ;
VAL_ 2005 brickVoltage081_BMS22 65535 "SNA" ;
VAL_ 2005 moduleTemperature28_BMS22 255 "SNA" ;
VAL_ 2005 brickVoltage082_BMS22 65535 "SNA" ;
VAL_ 2005 brickVoltage083_BMS22 65535 "SNA" ;
VAL_ 2005 brickVoltage084_BMS22 65535 "SNA" ;
VAL_ 2005 moduleTemperature29_BMS22 255 "SNA" ;
VAL_ 2005 brickVoltage085_BMS22 65535 "SNA" ;
VAL_ 2005 brickVoltage086_BMS22 65535 "SNA" ;
VAL_ 2005 brickVoltage087_BMS22 65535 "SNA" ;
VAL_ 2005 moduleTemperature30_BMS22 255 "SNA" ;
VAL_ 2005 brickVoltage088_BMS22 65535 "SNA" ;
VAL_ 2005 brickVoltage089_BMS22 65535 "SNA" ;
VAL_ 2005 brickVoltage090_BMS22 65535 "SNA" ;
VAL_ 2005 moduleTemperature31_BMS22 255 "SNA" ;
VAL_ 2005 brickVoltage091_BMS22 65535 "SNA" ;
VAL_ 2005 brickVoltage092_BMS22 65535 "SNA" ;
VAL_ 2005 brickVoltage093_BMS22 65535 "SNA" ;
VAL_ 2005 moduleTemperature32_BMS22 255 "SNA" ;
VAL_ 2005 brickVoltage094_BMS22 65535 "SNA" ;
VAL_ 2005 brickVoltage095_BMS22 65535 "SNA" ;
VAL_ 2005 brickVoltage096_BMS22 65535 "SNA" ;
VAL_ 2005 brickVoltage097_BMS22 65535 "SNA" ;
VAL_ 2005 brickVoltage098_BMS22 65535 "SNA" ;
VAL_ 2005 brickVoltage099_BMS22 65535 "SNA" ;
VAL_ 2005 brickVoltage100_BMS22 65535 "SNA" ;
VAL_ 2005 brickVoltage101_BMS22 65535 "SNA" ;
VAL_ 2005 brickVoltage102_BMS22 65535 "SNA" ;
VAL_ 2005 brickVoltage103_BMS22 65535 "SNA" ;
VAL_ 2005 brickVoltage104_BMS22 65535 "SNA" ;
VAL_ 2005 brickVoltage105_BMS22 65535 "SNA" ;
VAL_ 2005 brickVoltage106_BMS22 65535 "SNA" ;
VAL_ 2005 brickVoltage107_BMS22 65535 "SNA" ;
VAL_ 2005 brickVoltage108_BMS22 65535 "SNA" ;
VAL_ 2005 brickVoltage109_BMS22 65535 "SNA" ;
VAL_ 2005 brickVoltage110_BMS22 65535 "SNA" ;
VAL_ 2005 brickVoltage111_BMS22 65535 "SNA" ;
VAL_ 2005 brickVoltage112_BMS22 65535 "SNA" ;
VAL_ 2005 brickVoltage113_BMS22 65535 "SNA" ;
VAL_ 2005 brickVoltage114_BMS22 65535 "SNA" ;
VAL_ 2005 brickVoltage115_BMS22 65535 "SNA" ;
VAL_ 2005 brickVoltage116_BMS22 65535 "SNA" ;
VAL_ 2005 brickVoltage117_BMS22 65535 "SNA" ;
VAL_ 2005 brickVoltage118_BMS22 65535 "SNA" ;
VAL_ 2005 brickVoltage119_BMS22 65535 "SNA" ;
VAL_ 2005 brickVoltage120_BMS22 65535 "SNA" ;
VAL_ 2005 brickVoltage121_BMS22 65535 "SNA" ;
VAL_ 2005 brickVoltage122_BMS22 65535 "SNA" ;
VAL_ 2005 brickVoltage123_BMS22 65535 "SNA" ;
VAL_ 2005 brickVoltage124_BMS22 65535 "SNA" ;
VAL_ 2005 brickVoltage125_BMS22 65535 "SNA" ;
VAL_ 2005 brickVoltage126_BMS22 65535 "SNA" ;
VAL_ 2005 brickVoltage127_BMS22 65535 "SNA" ;
VAL_ 2005 brickVoltage128_BMS22 65535 "SNA" ;
VAL_ 2005 brickVoltage129_BMS22 65535 "SNA" ;
VAL_ 2005 brickVoltage130_BMS22 65535 "SNA" ;
VAL_ 2005 brickVoltage131_BMS22 65535 "SNA" ;
VAL_ 2005 brickVoltage132_BMS22 65535 "SNA" ;
VAL_ 2005 brickVoltage133_BMS22 65535 "SNA" ;
VAL_ 2005 brickVoltage134_BMS22 65535 "SNA" ;
VAL_ 2005 brickVoltage135_BMS22 65535 "SNA" ;
VAL_ 2005 brickVoltage136_BMS22 65535 "SNA" ;
VAL_ 2005 brickVoltage137_BMS22 65535 "SNA" ;
VAL_ 2005 brickVoltage138_BMS22 65535 "SNA" ;
VAL_ 2005 brickVoltage139_BMS22 65535 "SNA" ;
VAL_ 2005 brickVoltage140_BMS22 65535 "SNA" ;
VAL_ 2005 brickVoltage141_BMS22 65535 "SNA" ;
VAL_ 2005 brickVoltage142_BMS22 65535 "SNA" ;
VAL_ 2005 brickVoltage143_BMS22 65535 "SNA" ;
VAL_ 2005 brickVoltage144_BMS22 65535 "SNA" ;
VAL_ 2005 brickVoltage145_BMS22 65535 "SNA" ;
VAL_ 2005 brickVoltage146_BMS22 65535 "SNA" ;
VAL_ 2005 brickVoltage147_BMS22 65535 "SNA" ;
VAL_ 2005 brickVoltage148_BMS22 65535 "SNA" ;
VAL_ 2005 brickVoltage149_BMS22 65535 "SNA" ;
VAL_ 2005 brickVoltage150_BMS22 65535 "SNA" ;
VAL_ 2005 brickVoltage151_BMS22 65535 "SNA" ;
VAL_ 2005 brickVoltage152_BMS22 65535 "SNA" ;
VAL_ 2005 brickVoltage153_BMS22 65535 "SNA" ;
VAL_ 2005 brickVoltage154_BMS22 65535 "SNA" ;
VAL_ 2005 brickVoltage155_BMS22 65535 "SNA" ;
VAL_ 2005 brickVoltage156_BMS22 65535 "SNA" ;
VAL_ 2005 brickVoltage157_BMS22 65535 "SNA" ;
VAL_ 2005 brickVoltage158_BMS22 65535 "SNA" ;
VAL_ 2005 brickVoltage159_BMS22 65535 "SNA" ;
VAL_ 2005 brickVoltage160_BMS22 65535 "SNA" ;
VAL_ 2005 brickVoltage161_BMS22 65535 "SNA" ;
VAL_ 2005 brickVoltage162_BMS22 65535 "SNA" ;
VAL_ 2005 brickVoltage163_BMS22 65535 "SNA" ;
VAL_ 2005 brickVoltage164_BMS22 65535 "SNA" ;
VAL_ 2005 brickVoltage165_BMS22 65535 "SNA" ;
VAL_ 2005 brickVoltage166_BMS22 65535 "SNA" ;
VAL_ 2005 brickVoltage167_BMS22 65535 "SNA" ;
VAL_ 2005 brickVoltage168_BMS22 65535 "SNA" ;
VAL_ 2005 brickVoltage169_BMS22 65535 "SNA" ;
VAL_ 2005 brickVoltage170_BMS22 65535 "SNA" ;
VAL_ 2005 brickVoltage171_BMS22 65535 "SNA" ;
VAL_ 2005 brickVoltage172_BMS22 65535 "SNA" ;
VAL_ 2005 brickVoltage173_BMS22 65535 "SNA" ;
VAL_ 2005 brickVoltage174_BMS22 65535 "SNA" ;
VAL_ 2005 brickVoltage175_BMS22 65535 "SNA" ;
VAL_ 2005 brickVoltage176_BMS22 65535 "SNA" ;
VAL_ 2005 brickVoltage177_BMS22 65535 "SNA" ;
VAL_ 2005 brickVoltage178_BMS22 65535 "SNA" ;
VAL_ 2005 brickVoltage179_BMS22 65535 "SNA" ;
VAL_ 2005 brickVoltage180_BMS22 65535 "SNA" ;
VAL_ 2005 brickVoltage181_BMS22 65535 "SNA" ;
VAL_ 2005 brickVoltage182_BMS22 65535 "SNA" ;
VAL_ 2005 brickVoltage183_BMS22 65535 "SNA" ;
VAL_ 2005 brickVoltage184_BMS22 65535 "SNA" ;
VAL_ 2005 brickVoltage185_BMS22 65535 "SNA" ;
VAL_ 2005 brickVoltage186_BMS22 65535 "SNA" ;
VAL_ 2005 brickVoltage187_BMS22 65535 "SNA" ;
VAL_ 2005 brickVoltage188_BMS22 65535 "SNA" ;
VAL_ 2005 brickVoltage189_BMS22 65535 "SNA" ;
VAL_ 2005 brickVoltage190_BMS22 65535 "SNA" ;
VAL_ 2005 brickVoltage191_BMS22 65535 "SNA" ;
VAL_ 2005 brickVoltage192_BMS22 65535 "SNA" ;
VAL_ 2005 brickVoltage193_BMS22 65535 "SNA" ;
VAL_ 2005 brickVoltage194_BMS22 65535 "SNA" ;
VAL_ 2005 brickVoltage195_BMS22 65535 "SNA" ;
VAL_ 2005 brickVoltage196_BMS22 65535 "SNA" ;
VAL_ 2005 brickVoltage197_BMS22 65535 "SNA" ;
VAL_ 2005 brickVoltage198_BMS22 65535 "SNA" ;
VAL_ 2005 brickVoltage199_BMS22 65535 "SNA" ;
VAL_ 2005 brickVoltage200_BMS22 65535 "SNA" ;
VAL_ 2005 brickVoltage201_BMS22 65535 "SNA" ;
VAL_ 2005 brickVoltage202_BMS22 65535 "SNA" ;
VAL_ 2005 brickVoltage203_BMS22 65535 "SNA" ;
VAL_ 2005 brickVoltage204_BMS22 65535 "SNA" ;
VAL_ 2005 brickVoltage205_BMS22 65535 "SNA" ;
VAL_ 2005 brickVoltage206_BMS22 65535 "SNA" ;
VAL_ 2005 brickVoltage207_BMS22 65535 "SNA" ;
VAL_ 2005 brickVoltage208_BMS22 65535 "SNA" ;
VAL_ 2005 brickVoltage209_BMS22 65535 "SNA" ;
VAL_ 2005 brickVoltage210_BMS22 65535 "SNA" ;
VAL_ 2005 brickVoltage211_BMS22 65535 "SNA" ;
VAL_ 2005 brickVoltage212_BMS22 65535 "SNA" ;
VAL_ 2005 brickVoltage213_BMS22 65535 "SNA" ;
VAL_ 2005 brickVoltage214_BMS22 65535 "SNA" ;
VAL_ 2005 brickVoltage215_BMS22 65535 "SNA" ;
VAL_ 2005 brickVoltage216_BMS22 65535 "SNA" ;
VAL_ 2005 brickVoltage217_BMS22 65535 "SNA" ;
VAL_ 2005 brickVoltage218_BMS22 65535 "SNA" ;
VAL_ 2005 brickVoltage219_BMS22 65535 "SNA" ;
VAL_ 2005 brickVoltage220_BMS22 65535 "SNA" ;
VAL_ 2005 brickVoltage221_BMS22 65535 "SNA" ;
VAL_ 2005 brickVoltage222_BMS22 65535 "SNA" ;
VAL_ 2005 brickVoltage223_BMS22 65535 "SNA" ;
VAL_ 2005 brickVoltage224_BMS22 65535 "SNA" ;
VAL_ 2005 brickVoltage225_BMS22 65535 "SNA" ;
VAL_ 2005 brickVoltage226_BMS22 65535 "SNA" ;
VAL_ 2005 brickVoltage227_BMS22 65535 "SNA" ;
VAL_ 2005 brickVoltage228_BMS22 65535 "SNA" ;
VAL_ 2005 brickVoltage229_BMS22 65535 "SNA" ;
VAL_ 2005 brickVoltage230_BMS22 65535 "SNA" ;
VAL_ 2005 brickVoltage231_BMS22 65535 "SNA" ;
VAL_ 2005 brickVoltage232_BMS22 65535 "SNA" ;
VAL_ 2005 brickVoltage233_BMS22 65535 "SNA" ;
VAL_ 2005 brickVoltage234_BMS22 65535 "SNA" ;
VAL_ 2005 brickVoltage235_BMS22 65535 "SNA" ;
VAL_ 2005 brickVoltage236_BMS22 65535 "SNA" ;
VAL_ 2005 brickVoltage237_BMS22 65535 "SNA" ;
VAL_ 2005 brickVoltage238_BMS22 65535 "SNA" ;
VAL_ 2005 brickVoltage239_BMS22 65535 "SNA" ;
VAL_ 2005 brickVoltage240_BMS22 65535 "SNA" ;
VAL_ 2005 brickVoltage241_BMS22 65535 "SNA" ;
VAL_ 2005 brickVoltage242_BMS22 65535 "SNA" ;
VAL_ 2005 brickVoltage243_BMS22 65535 "SNA" ;
VAL_ 2005 brickVoltage244_BMS22 65535 "SNA" ;
VAL_ 2005 brickVoltage245_BMS22 65535 "SNA" ;
VAL_ 2005 brickVoltage246_BMS22 65535 "SNA" ;
VAL_ 2005 brickVoltage247_BMS22 65535 "SNA" ;
VAL_ 2005 brickVoltage248_BMS22 65535 "SNA" ;
VAL_ 2005 brickVoltage249_BMS22 65535 "SNA" ;
VAL_ 2005 brickVoltage250_BMS22 65535 "SNA" ;
VAL_ 2005 brickVoltage251_BMS22 65535 "SNA" ;
VAL_ 2005 brickVoltage252_BMS22 65535 "SNA" ;
VAL_ 2005 brickVoltage253_BMS22 65535 "SNA" ;
VAL_ 2005 brickVoltage254_BMS22 65535 "SNA" ;
VAL_ 2005 brickVoltage255_BMS22 65535 "SNA" ;
VAL_ 2005 brickVoltage256_BMS22 65535 "SNA" ;
VAL_ 2005 brickVoltage257_BMS22 65535 "SNA" ;
VAL_ 2005 brickVoltage258_BMS22 65535 "SNA" ;
VAL_ 2005 brickVoltage259_BMS22 65535 "SNA" ;
VAL_ 2005 brickVoltage260_BMS22 65535 "SNA" ;
VAL_ 2005 brickVoltage261_BMS22 65535 "SNA" ;
VAL_ 2005 brickVoltage262_BMS22 65535 "SNA" ;
VAL_ 2005 brickVoltage263_BMS22 65535 "SNA" ;
VAL_ 2005 brickVoltage264_BMS22 65535 "SNA" ;
VAL_ 2005 brickVoltage265_BMS22 65535 "SNA" ;
VAL_ 2005 brickVoltage266_BMS22 65535 "SNA" ;
VAL_ 2005 brickVoltage267_BMS22 65535 "SNA" ;
VAL_ 2005 brickVoltage268_BMS22 65535 "SNA" ;
VAL_ 2005 brickVoltage269_BMS22 65535 "SNA" ;
VAL_ 2005 brickVoltage270_BMS22 65535 "SNA" ;
VAL_ 2005 brickVoltage271_BMS22 65535 "SNA" ;
VAL_ 2005 brickVoltage272_BMS22 65535 "SNA" ;
VAL_ 2005 brickVoltage273_BMS22 65535 "SNA" ;
VAL_ 2005 brickVoltage274_BMS22 65535 "SNA" ;
VAL_ 2005 brickVoltage275_BMS22 65535 "SNA" ;
VAL_ 2005 brickVoltage276_BMS22 65535 "SNA" ;
VAL_ 2005 brickVoltage277_BMS22 65535 "SNA" ;
VAL_ 2005 brickVoltage278_BMS22 65535 "SNA" ;
VAL_ 2005 brickVoltage279_BMS22 65535 "SNA" ;
VAL_ 2005 brickVoltage280_BMS22 65535 "SNA" ;
VAL_ 2005 brickVoltage281_BMS22 65535 "SNA" ;
VAL_ 2005 brickVoltage282_BMS22 65535 "SNA" ;
VAL_ 2005 brickVoltage283_BMS22 65535 "SNA" ;
VAL_ 2005 brickVoltage284_BMS22 65535 "SNA" ;
VAL_ 2005 brickVoltage285_BMS22 65535 "SNA" ;
VAL_ 2005 brickVoltage286_BMS22 65535 "SNA" ;
VAL_ 2005 brickVoltage287_BMS22 65535 "SNA" ;
VAL_ 2005 brickVoltage288_BMS22 65535 "SNA" ;
VAL_ 2005 brickVoltage289_BMS22 65535 "SNA" ;
VAL_ 2005 brickVoltage290_BMS22 65535 "SNA" ;
VAL_ 2005 brickVoltage291_BMS22 65535 "SNA" ;
VAL_ 2005 brickVoltage292_BMS22 65535 "SNA" ;
VAL_ 2005 brickVoltage293_BMS22 65535 "SNA" ;
VAL_ 2005 brickVoltage294_BMS22 65535 "SNA" ;
VAL_ 2005 brickVoltage295_BMS22 65535 "SNA" ;
VAL_ 2005 brickVoltage296_BMS22 65535 "SNA" ;
VAL_ 2005 brickVoltage297_BMS22 65535 "SNA" ;
VAL_ 2005 brickVoltage298_BMS22 65535 "SNA" ;
VAL_ 2005 brickVoltage299_BMS22 65535 "SNA" ;
VAL_ 2005 brickVoltage300_BMS22 65535 "SNA" ;
VAL_ 2005 moduleTemperature33_BMS22 255 "SNA" ;
VAL_ 2005 moduleTemperature34_BMS22 255 "SNA" ;
VAL_ 2005 moduleTemperature35_BMS22 255 "SNA" ;
VAL_ 2005 moduleTemperature36_BMS22 255 "SNA" ;
VAL_ 2005 moduleTemperature37_BMS22 255 "SNA" ;
VAL_ 2005 moduleTemperature38_BMS22 255 "SNA" ;
VAL_ 2005 moduleTemperature39_BMS22 255 "SNA" ;
VAL_ 2005 moduleTemperature40_BMS22 255 "SNA" ;
VAL_ 2005 moduleTemperature41_BMS22 255 "SNA" ;
VAL_ 2005 moduleTemperature42_BMS22 255 "SNA" ;
VAL_ 2005 moduleTemperature43_BMS22 255 "SNA" ;
VAL_ 2005 moduleTemperature44_BMS22 255 "SNA" ;
VAL_ 2005 moduleTemperature45_BMS22 255 "SNA" ;
VAL_ 2005 moduleTemperature46_BMS22 255 "SNA" ;
VAL_ 2005 moduleTemperature47_BMS22 255 "SNA" ;
VAL_ 2005 moduleTemperature48_BMS22 255 "SNA" ;
VAL_ 2005 moduleTemperature49_BMS22 255 "SNA" ;
VAL_ 2005 moduleTemperature50_BMS22 255 "SNA" ;
VAL_ 2005 moduleTemperature51_BMS22 255 "SNA" ;
VAL_ 2005 moduleTemperature52_BMS22 255 "SNA" ;
VAL_ 2005 moduleTemperature53_BMS22 255 "SNA" ;
VAL_ 2005 moduleTemperature54_BMS22 255 "SNA" ;
VAL_ 2005 moduleTemperature55_BMS22 255 "SNA" ;
VAL_ 2005 moduleTemperature56_BMS22 255 "SNA" ;
VAL_ 2005 moduleTemperature57_BMS22 255 "SNA" ;
VAL_ 2005 moduleTemperature58_BMS22 255 "SNA" ;
VAL_ 2005 moduleTemperature59_BMS22 255 "SNA" ;
VAL_ 2005 moduleTemperature60_BMS22 255 "SNA" ;
VAL_ 2005 moduleTemperature61_BMS22 255 "SNA" ;
VAL_ 2005 moduleTemperature62_BMS22 255 "SNA" ;
VAL_ 2005 moduleTemperature63_BMS22 255 "SNA" ;
VAL_ 2005 moduleTemperature64_BMS22 255 "SNA" ;
VAL_ 2005 moduleTemperature65_BMS22 255 "SNA" ;
VAL_ 2005 moduleTemperature66_BMS22 255 "SNA" ;
VAL_ 2005 moduleTemperature67_BMS22 255 "SNA" ;
VAL_ 2005 moduleTemperature68_BMS22 255 "SNA" ;
VAL_ 2005 moduleTemperature69_BMS22 255 "SNA" ;
VAL_ 2005 moduleTemperature70_BMS22 255 "SNA" ;
VAL_ 2005 moduleTemperature71_BMS22 255 "SNA" ;
VAL_ 2005 moduleTemperature72_BMS22 255 "SNA" ;
VAL_ 2005 moduleTemperature73_BMS22 255 "SNA" ;
VAL_ 2005 moduleTemperature74_BMS22 255 "SNA" ;
VAL_ 2005 moduleTemperature75_BMS22 255 "SNA" ;
VAL_ 2005 moduleTemperature76_BMS22 255 "SNA" ;
VAL_ 2005 moduleTemperature77_BMS22 255 "SNA" ;
VAL_ 2005 moduleTemperature78_BMS22 255 "SNA" ;
VAL_ 2005 moduleTemperature79_BMS22 255 "SNA" ;
VAL_ 2005 moduleTemperature80_BMS22 255 "SNA" ;
VAL_ 2005 moduleTemperature81_BMS22 255 "SNA" ;
VAL_ 2005 moduleTemperature82_BMS22 255 "SNA" ;
VAL_ 2005 moduleTemperature83_BMS22 255 "SNA" ;
VAL_ 2005 moduleTemperature84_BMS22 255 "SNA" ;
VAL_ 2005 moduleTemperature85_BMS22 255 "SNA" ;
VAL_ 2005 moduleTemperature86_BMS22 255 "SNA" ;
VAL_ 2005 moduleTemperature87_BMS22 255 "SNA" ;
VAL_ 2005 moduleTemperature88_BMS22 255 "SNA" ;
VAL_ 2005 moduleTemperature89_BMS22 255 "SNA" ;
VAL_ 2005 moduleTemperature90_BMS22 255 "SNA" ;
VAL_ 2005 moduleTemperature91_BMS22 255 "SNA" ;
VAL_ 2005 moduleTemperature92_BMS22 255 "SNA" ;
VAL_ 2005 moduleTemperature93_BMS22 255 "SNA" ;
VAL_ 2005 moduleTemperature94_BMS22 255 "SNA" ;
VAL_ 2005 moduleTemperature95_BMS22 255 "SNA" ;
VAL_ 2005 moduleTemperature96_BMS22 255 "SNA" ;
VAL_ 2005 moduleTemperature97_BMS22 255 "SNA" ;
VAL_ 2005 moduleTemperature98_BMS22 255 "SNA" ;
VAL_ 2005 moduleTemperature99_BMS22 255 "SNA" ;
VAL_ 2005 moduleTemperature100_BMS22 255 "SNA" ;
VAL_ 920 DEM319_HV_DISABLE_DURING_S_BMS25 3 "DEM_INVALID" 2 "DEM_FAILED" 1 "DEM_PASSED" 0 "DEM_NOTTESTED" ;
VAL_ 920 DEM318_HV_ENABLE_IMPLAUSIB_BMS25 3 "DEM_INVALID" 2 "DEM_FAILED" 1 "DEM_PASSED" 0 "DEM_NOTTESTED" ;
VAL_ 920 DEM317_STRING_SUSPECT_OPEN_BMS25 3 "DEM_INVALID" 2 "DEM_FAILED" 1 "DEM_PASSED" 0 "DEM_NOTTESTED" ;
VAL_ 920 DEM316_UNEXPCTD_BMS_ON_CAN_BMS25 3 "DEM_INVALID" 2 "DEM_FAILED" 1 "DEM_PASSED" 0 "DEM_NOTTESTED" ;
VAL_ 920 DEM315_HV_WITHSTAND_TESTS__BMS25 3 "DEM_INVALID" 2 "DEM_FAILED" 1 "DEM_PASSED" 0 "DEM_NOTTESTED" ;
VAL_ 920 DEM314_OBC_PILOT_ERROR_BMS25 3 "DEM_INVALID" 2 "DEM_FAILED" 1 "DEM_PASSED" 0 "DEM_NOTTESTED" ;
VAL_ 920 DEM313_OBC_PILOT_HIGH_BMS25 3 "DEM_INVALID" 2 "DEM_FAILED" 1 "DEM_PASSED" 0 "DEM_NOTTESTED" ;
VAL_ 920 DEM312_OBC_PROXIMITY_ERROR_BMS25 3 "DEM_INVALID" 2 "DEM_FAILED" 1 "DEM_PASSED" 0 "DEM_NOTTESTED" ;
VAL_ 920 DEM311_CTRS_END_OF_LIFE_WA_BMS25 3 "DEM_INVALID" 2 "DEM_FAILED" 1 "DEM_PASSED" 0 "DEM_NOTTESTED" ;
VAL_ 920 DEM310_BMSMIA_STRNGMSTR_AL_BMS25 3 "DEM_INVALID" 2 "DEM_FAILED" 1 "DEM_PASSED" 0 "DEM_NOTTESTED" ;
VAL_ 920 DEM309_VOLTAGE_BRICKOV_WAR_BMS25 3 "DEM_INVALID" 2 "DEM_FAILED" 1 "DEM_PASSED" 0 "DEM_NOTTESTED" ;
VAL_ 920 DEM308_PRESSURE_FLT_BMS25 3 "DEM_INVALID" 2 "DEM_FAILED" 1 "DEM_PASSED" 0 "DEM_NOTTESTED" ;
VAL_ 920 DEM307_PRESSURE_MIA_BMS25 3 "DEM_INVALID" 2 "DEM_FAILED" 1 "DEM_PASSED" 0 "DEM_NOTTESTED" ;
VAL_ 920 DEM306_SW_VERSION_MISMATCH_BMS25 3 "DEM_INVALID" 2 "DEM_FAILED" 1 "DEM_PASSED" 0 "DEM_NOTTESTED" ;
VAL_ 920 DEM305_MODULET_OVERTEMP_WA_BMS25 3 "DEM_INVALID" 2 "DEM_FAILED" 1 "DEM_PASSED" 0 "DEM_NOTTESTED" ;
VAL_ 920 DEM304_PCHG_OPENCIRCUIT_IN_BMS25 3 "DEM_INVALID" 2 "DEM_FAILED" 1 "DEM_PASSED" 0 "DEM_NOTTESTED" ;
VAL_ 920 DEM303_MODULET_UNDERTEMP_W_BMS25 3 "DEM_INVALID" 2 "DEM_FAILED" 1 "DEM_PASSED" 0 "DEM_NOTTESTED" ;
VAL_ 920 DEM302_MODULET_UT_BMS25 3 "DEM_INVALID" 2 "DEM_FAILED" 1 "DEM_PASSED" 0 "DEM_NOTTESTED" ;
VAL_ 920 DEM301_FUSI_LOCK_BMS25 3 "DEM_INVALID" 2 "DEM_FAILED" 1 "DEM_PASSED" 0 "DEM_NOTTESTED" ;
VAL_ 920 DEM300_DEBUG_SM_DISABLED_BMS25 3 "DEM_INVALID" 2 "DEM_FAILED" 1 "DEM_PASSED" 0 "DEM_NOTTESTED" ;
VAL_ 920 DEM299_5V_SENSOR_SUPPLY_OU_BMS25 3 "DEM_INVALID" 2 "DEM_FAILED" 1 "DEM_PASSED" 0 "DEM_NOTTESTED" ;
VAL_ 920 DEM298_IMPL_DRIVE_REQUEST_BMS25 3 "DEM_INVALID" 2 "DEM_FAILED" 1 "DEM_PASSED" 0 "DEM_NOTTESTED" ;
VAL_ 920 DEM297_PCHG2_OPENCIRCUIT_BMS25 3 "DEM_INVALID" 2 "DEM_FAILED" 1 "DEM_PASSED" 0 "DEM_NOTTESTED" ;
VAL_ 920 DEM296_CTRSAUX_IMPLAUSIBLE_BMS25 3 "DEM_INVALID" 2 "DEM_FAILED" 1 "DEM_PASSED" 0 "DEM_NOTTESTED" ;
VAL_ 920 DEM295_CTRSAUX_LINKV_UNSAF_BMS25 3 "DEM_INVALID" 2 "DEM_FAILED" 1 "DEM_PASSED" 0 "DEM_NOTTESTED" ;
VAL_ 920 DEM294_CANRX_PT_EMERGENCY_BMS25 3 "DEM_INVALID" 2 "DEM_FAILED" 1 "DEM_PASSED" 0 "DEM_NOTTESTED" ;
VAL_ 920 DEM293_SBC_LDT_IMPLAUSIBLE_BMS25 3 "DEM_INVALID" 2 "DEM_FAILED" 1 "DEM_PASSED" 0 "DEM_NOTTESTED" ;
VAL_ 920 DEM292_NUM_EXPECTED_STRING_BMS25 3 "DEM_INVALID" 2 "DEM_FAILED" 1 "DEM_PASSED" 0 "DEM_NOTTESTED" ;
VAL_ 920 DEM291_NUM_EXPECTED_STRING_BMS25 3 "DEM_INVALID" 2 "DEM_FAILED" 1 "DEM_PASSED" 0 "DEM_NOTTESTED" ;
VAL_ 920 DEM290_CMB_ONBOARD_DEFECT_BMS25 3 "DEM_INVALID" 2 "DEM_FAILED" 1 "DEM_PASSED" 0 "DEM_NOTTESTED" ;
VAL_ 920 DEM289_TEMP_STATE_LATCHED_BMS25 3 "DEM_INVALID" 2 "DEM_FAILED" 1 "DEM_PASSED" 0 "DEM_NOTTESTED" ;
VAL_ 920 DEM288_CURR_STATE_LATCHED_BMS25 3 "DEM_INVALID" 2 "DEM_FAILED" 1 "DEM_PASSED" 0 "DEM_NOTTESTED" ;
VAL_ 984 balancingInDriveTimer_BMS25 65535 "SNA" ;
VAL_ 984 SOCRestPolarization_BMS25 255 "SNA" ;
VAL_ 984 CoolantSensorState_BMS25 3 "OIL_OK" 2 "SENSOR_FAILURE" 1 "WATER_DETECTED" 0 "SENSOR_CAN_MIA" ;
VAL_ 984 temperatureModelOffset_BMS25 255 "SNA" ;
VAL_ 984 SOHCMinBrickHighEst_BMS25 255 "SNA" ;
VAL_ 984 SOHCMaxBrickHighEst_BMS25 255 "SNA" ;
VAL_ 984 regenCurrOpLkyBktThrs1_BMS25 255 "SNA" ;
VAL_ 984 dischargeCurrOpLkyBktThrs1_BMS25 255 "SNA" ;
VAL_ 984 regenCurrentOpLoadValue_BMS25 255 "SNA" ;
VAL_ 984 dischargeCurrOpLoadValue_BMS25 255 "SNA" ;
VAL_ 984 minBrickVoltageLimit_BMS25 65535 "SNA" ;
VAL_ 984 currentModule3Integral_BMS25 65535 "SNA" ;
VAL_ 984 currentModule2Integral_BMS25 65535 "SNA" ;
VAL_ 984 currentModule1Integral_BMS25 65535 "SNA" ;
VAL_ 984 currentModuleMin_BMS25 65535 "SNA" ;
VAL_ 984 currentModuleMax_BMS25 65535 "SNA" ;
VAL_ 984 maxBrickVoltageSync_BMS25 65535 "SNA" ;
VAL_ 984 minBrickVoltageSync_BMS25 65535 "SNA" ;
VAL_ 984 SOHCMinBrickLowEst_BMS25 255 "SNA" ;
VAL_ 984 SOHCMaxBrickLowEst_BMS25 255 "SNA" ;
VAL_ 984 gradLimSOC_BMS25 65535 "SNA" ;
VAL_ 984 SOCRecalSlowOp_BMS25 255 "SNA" ;
VAL_ 984 SOHCMinIndex_BMS25 65535 "SNA" ;
VAL_ 984 SOHCMaxIndex_BMS25 65535 "SNA" ;
VAL_ 984 SOHRMinRegen_BMS25 255 "SNA" ;
VAL_ 984 SOHRMinDchg_BMS25 255 "SNA" ;
VAL_ 984 SOHRMeanRegen_BMS25 255 "SNA" ;
VAL_ 984 SOHRMeanDchg_BMS25 255 "SNA" ;
VAL_ 984 SOHRMaxRegen_BMS25 255 "SNA" ;
VAL_ 984 SOHRMaxDchg_BMS25 255 "SNA" ;
VAL_ 984 SOHCMin_BMS25 255 "SNA" ;
VAL_ 984 SOHCMean_BMS25 255 "SNA" ;
VAL_ 984 SOHCMax_BMS25 255 "SNA" ;
VAL_ 984 ppRegenCurrLimitPredShort_BMS25 255 "SNA" ;
VAL_ 984 ppRegenCurrLimitPredLong_BMS25 255 "SNA" ;
VAL_ 984 ppDchgCurrLimitPredShort_BMS25 255 "SNA" ;
VAL_ 984 ppDchgCurrLimitPredLong_BMS25 255 "SNA" ;
VAL_ 984 ppPolarizationV_BMS25 65535 "SNA" ;
VAL_ 984 SOCRecalMinOCVEst_BMS25 65535 "SNA" ;
VAL_ 984 SOCRecalMaxOCVEst_BMS25 65535 "SNA" ;
VAL_ 984 SOCRecalMinSOCUpp_BMS25 255 "SNA" ;
VAL_ 984 SOCRecalMinSOCLow_BMS25 255 "SNA" ;
VAL_ 984 SOCRecalMinSOC_BMS25 255 "SNA" ;
VAL_ 984 SOCRecalMaxSOCUpp_BMS25 255 "SNA" ;
VAL_ 984 SOCRecalMaxSOCLow_BMS25 255 "SNA" ;
VAL_ 984 SOCRecalMaxSOC_BMS25 255 "SNA" ;
VAL_ 984 ppNewtonStepsRegen_BMS25 7 "SNA" ;
VAL_ 984 ppNewtonStepsDchg_BMS25 7 "SNA" ;
VAL_ 984 ppNewtonRegenVRes_BMS25 255 "SNA" ;
VAL_ 984 ppNewtonDchgVRes_BMS25 255 "SNA" ;
VAL_ 984 ppMinModelAlphaTarget_BMS25 255 "SNA" ;
VAL_ 984 ppMaxModelAlphaTarget_BMS25 255 "SNA" ;
VAL_ 984 ppLearningTauRegen_BMS25 65535 "SNA" ;
VAL_ 984 ppLearningCriterionDyn_BMS25 255 "SNA" ;
VAL_ 984 ppLearningCriterionAbs_BMS25 255 "SNA" ;
VAL_ 984 ppLearningCriterionJoin_BMS25 255 "SNA" ;
VAL_ 984 currentRedundant_BMS25 65535 "SNA" ;
VAL_ 984 currentModule3_BMS25 65535 "SNA" ;
VAL_ 984 currentModule2_BMS25 65535 "SNA" ;
VAL_ 984 currentModule1_BMS25 65535 "SNA" ;
VAL_ 984 ppMeanDchgIntRes_BMS25 65535 "SNA" ;
VAL_ 984 ppMinModelLowpassV_BMS25 65535 "SNA" ;
VAL_ 984 ppMaxModelVoltageIndex_BMS25 65535 "SNA" ;
VAL_ 984 ppMaxModelLowpassV_BMS25 65535 "SNA" ;
VAL_ 984 ppLearningTauDischarge_BMS25 65535 "SNA" ;
VAL_ 984 ppMaxRegenAlpha_BMS25 255 "SNA" ;
VAL_ 984 ppMaxModelledV_BMS25 65535 "SNA" ;
VAL_ 984 ppMinDchgAlpha_BMS25 255 "SNA" ;
VAL_ 984 ppMinModelledV_BMS25 65535 "SNA" ;
VAL_ 984 debugSlowMpex2_BMS25 0 "S00" 1 "S01" 2 "S02" 3 "S03" 4 "S04" 5 "S05" 6 "S06" 7 "S07" 8 "S08" 9 "S09" 10 "S10" 11 "S11" 12 "S12" 13 "S13" 14 "S14" 15 "S15" 16 "S16" 17 "S17" 18 "S18" 19 "S19" 20 "S20" 21 "S21" 22 "S22" 23 "S23" 24 "S24" 25 "S25" ;
VAL_ 984 ppRegenCurrPredShort_BMS25 65535 "SNA" ;
VAL_ 984 ppDischgCurrPredLong_BMS25 65535 "SNA" ;
VAL_ 984 ppDischgCurrPredShort_BMS25 65535 "SNA" ;
VAL_ 984 ppRegenCurrPredLong_BMS25 65535 "SNA" ;
VAL_ 984 ppRegenVPredShort_BMS25 65535 "SNA" ;
VAL_ 984 ppDischgVPredShort_BMS25 65535 "SNA" ;
VAL_ 984 ppRegenVPredLong_BMS25 65535 "SNA" ;
VAL_ 984 ppDischgVPredLong_BMS25 65535 "SNA" ;
VAL_ 984 SOHDeltaSOCCoulomb_BMS25 65535 "SNA" ;
VAL_ 984 SOHAbsDeltaSOCCoulomb_BMS25 65535 "SNA" ;
VAL_ 984 SOHLastOCVRecalMinSOC_BMS25 255 "SNA" ;
VAL_ 984 SOHbalancingTimeMinSOH_BMS25 255 "SNA" ;
VAL_ 1816 chargerDCOutV_BMS25 65535 "SNA" ;
VAL_ 1816 chargerProximity_BMS25 255 "SNA" ;
VAL_ 1816 chargerPilot_BMS25 255 "SNA" ;
VAL_ 1816 chargerCurrAvail_BMS25 255 "SNA" ;
VAL_ 1816 chargerCtrOn_BMS25 1 "TRUE" 0 "FALSE" ;
VAL_ 1816 chargerOn_BMS25 1 "TRUE" 0 "FALSE" ;
VAL_ 1816 debugFastMpex2_BMS25 0 "F00" 1 "F01" 2 "F02" 3 "F03" 4 "F04" 5 "F05" 6 "F06" 7 "F07" 8 "F08" 9 "F09" 10 "F10" 11 "F11" 12 "F12" 13 "F13" 14 "F14" 15 "F15" ;
VAL_ 1816 posPackDbg_BMS25 65535 "SNA" ;
VAL_ 1816 negPackDbg_BMS25 65535 "SNA" ;
VAL_ 1816 packVoltageHVMeas_BMS25 65535 "SNA" ;
VAL_ 1880 SOHRecentChange_BMS25 255 "SNA" ;
VAL_ 1880 SOHConvergenceIndicator_BMS25 255 "SNA" ;
VAL_ 1880 SOHConvergenceCounter_BMS25 255 "SNA" ;
VAL_ 1880 SOHMinFiltered_BMS25 255 "SNA" ;
VAL_ 1880 medianModuleTempGrp2_BMS25 255 "SNA" ;
VAL_ 1880 medianModuleTempGrp1_BMS25 255 "SNA" ;
VAL_ 1880 coolantWarningtAlert_BMS25 3 "SNA" 2 "COOLANT_FLOOD_WARNING" 0 "COOLANT_NOWARNING" 1 "COOLANT_MOISTURE_WARNING" ;
VAL_ 1880 coolantFaultAlert_BMS25 3 "SNA" 2 "COOLANT_FLOOD_FAULT" 0 "COOLANT_NOFAULT" 1 "COOLANT_MOISTURE_FAULT" ;
VAL_ 1880 hvilShutdownStrategy_BMS25 4 "Strategy_4" 3 "Strategy_3" 2 "Strategy_2" 1 "Strategy_1" 0 "Strategy_0" ;
VAL_ 1880 J1939_nmState 3 "J1939_NM_INACTIVE" 2 "J1939_NM_ACTIVE" 1 "J1939_NM_STARTUP" 0 "J1939_NM_INIT" ;
VAL_ 1880 PrechargeXCapMin_BMS25 65535 "SNA" ;
VAL_ 1880 LimpHomeTimeOut_BMS25 65535 "SNA" ;
VAL_ 1880 hvWithstandTests_BMS25 255 "SNA" ;
VAL_ 1880 aux3prechargeState_BMS25 15 "CTR_PRCHG_NEG_OPEN" 13 "CTR_PRCHG_POS_WELD_CHECK" 12 "CTR_PRCHG_PRE_COND_CHECK" 11 "CTR_PRCHG_NEG2_WELD_CHECK" 10 "CTR_PRCHG_CLOSEMID" 9 "CTR_PRCHG_CLOSEAUX" 8 "CTR_PRCHG_FAILED" 7 "CTR_PRCHG_COMPLETE" 6 "CTR_PRCHG_CLOSE_POS" 5 "CTR_PRCHG_MONITOR_VOLTAGE" 4 "CTR_PRCHG_CLOSE_NEG" 3 "CTR_PRCHG_NEG_WELD_CHECK" 2 "CTR_PRCHG_CLOSE_RELAY" 1 "CTR_PRCHG_WELD_CHECK" 0 "CTR_PRCHG_OFF" ;
VAL_ 1880 aux2prechargeState_BMS25 15 "CTR_PRCHG_NEG_OPEN" 13 "CTR_PRCHG_POS_WELD_CHECK" 12 "CTR_PRCHG_PRE_COND_CHECK" 11 "CTR_PRCHG_NEG2_WELD_CHECK" 10 "CTR_PRCHG_CLOSEMID" 9 "CTR_PRCHG_CLOSEAUX" 8 "CTR_PRCHG_FAILED" 7 "CTR_PRCHG_COMPLETE" 6 "CTR_PRCHG_CLOSE_POS" 5 "CTR_PRCHG_MONITOR_VOLTAGE" 4 "CTR_PRCHG_CLOSE_NEG" 3 "CTR_PRCHG_NEG_WELD_CHECK" 2 "CTR_PRCHG_CLOSE_RELAY" 1 "CTR_PRCHG_WELD_CHECK" 0 "CTR_PRCHG_OFF" ;
VAL_ 1880 aux1prechargeState_BMS25 15 "CTR_PRCHG_NEG_OPEN" 13 "CTR_PRCHG_POS_WELD_CHECK" 12 "CTR_PRCHG_PRE_COND_CHECK" 11 "CTR_PRCHG_NEG2_WELD_CHECK" 10 "CTR_PRCHG_CLOSEMID" 9 "CTR_PRCHG_CLOSEAUX" 8 "CTR_PRCHG_FAILED" 7 "CTR_PRCHG_COMPLETE" 6 "CTR_PRCHG_CLOSE_POS" 5 "CTR_PRCHG_MONITOR_VOLTAGE" 4 "CTR_PRCHG_CLOSE_NEG" 3 "CTR_PRCHG_NEG_WELD_CHECK" 2 "CTR_PRCHG_CLOSE_RELAY" 1 "CTR_PRCHG_WELD_CHECK" 0 "CTR_PRCHG_OFF" ;
VAL_ 1880 auxLinkVoltage_BMS25 65535 "SNA" ;
VAL_ 1880 rangeRequestIgnoreVehicle 255 "NO_COMMAND" 1 "IGNORE" 0 "DO_NOT_IGNORE" ;
VAL_ 1880 rangeRequestEepromValue 255 "NO_COMMAND" 15 "RANGE_INVALID" 14 "RANGE_MAXIMUM" 13 "RANGE_MODESOH8" 12 "RANGE_MODESOH7" 11 "RANGE_MODESOH6" 10 "RANGE_MODESOH5" 9 "RANGE_MODESOH4" 8 "RANGE_MODESOH3" 7 "RANGE_MODESOH2" 6 "RANGE_MODESOH1" 5 "RANGE_MODE407" 4 "RANGE_MODE405" 3 "RANGE_MODE4175" 2 "RANGE_MODE415" 1 "RANGE_LIMITED" 0 "RANGE_SHIPPING" ;
VAL_ 1880 pressure2_BMS25 255 "SNA" ;
VAL_ 1880 calibration_version_BMS25 255 "SNA" ;
VAL_ 1880 currentLowTimer_BMS25 65535 "SNA" ;
VAL_ 1880 auxCntrrOpenUnderLoadCntr_BMS25 65535 "SNA" ;
VAL_ 1880 rabbitContactorState_BMS25 5 "FAILURE" 4 "CLOSE" 3 "EXT_ISO_TEST" 2 "AUX_CLOSE" 1 "INT_ISO_TEST" 0 "OPEN" ;
VAL_ 1880 analogIsenseSupplyCurr_BMS25 255 "SNA" ;
VAL_ 1880 pumpSpeedReqCoolPrfmc_BMS25 255 "SNA" ;
VAL_ 1880 microsarOs_IdleTask_OsCr0_BMS25 255 "SNA" ;
VAL_ 1880 microsarOs_BswTask_BMS25 255 "SNA" ;
VAL_ 1880 microsarOs_InitTask_BMS25 255 "SNA" ;
VAL_ 1880 microsarOs_ApplTask_1Hz_BMS25 255 "SNA" ;
VAL_ 1880 microsarOs_ApplTask_10Hz_BMS25 255 "SNA" ;
VAL_ 1880 microsarOs_ApplTask_100Hz_BMS25 255 "SNA" ;
VAL_ 1880 microsarOs_ApplLowTask_BMS25 255 "SNA" ;
VAL_ 1880 microsarOs_ApplLateInit_BMS25 255 "SNA" ;
VAL_ 1880 microsarOs_ApplHighTask_BMS25 255 "SNA" ;
VAL_ 1880 microsarOs_ApplEarlyInit_BMS25 255 "SNA" ;
VAL_ 1880 appTaskBSWMaxDuration_BMS25 255 "SNA" ;
VAL_ 1880 appTaskApplHighMaxDuration_BMS25 255 "SNA" ;
VAL_ 1880 appTask1HzMaxDuration_BMS25 255 "SNA" ;
VAL_ 1880 appTask100HzMaxDuration_BMS25 255 "SNA" ;
VAL_ 1880 appTask10HzMaxDuration_BMS25 255 "SNA" ;
VAL_ 1880 appTask100HzDuration_BMS25 255 "SNA" ;
VAL_ 1880 appTask10HzDuration_BMS25 255 "SNA" ;
VAL_ 1880 appTask1HzDuration_BMS25 255 "SNA" ;
VAL_ 1880 appTaskBSWDuration_BMS25 255 "SNA" ;
VAL_ 1880 appTaskApplHighDuration_BMS25 255 "SNA" ;
VAL_ 1880 iumprMaxRatioDTCId_BMS25 0 "SNA" ;
VAL_ 1880 iumprMaxRatio_BMS25 0 "SNA" ;
VAL_ 1880 iumprMinRatioDTCId_BMS25 0 "SNA" ;
VAL_ 1880 iumprMinRatio_BMS25 0 "SNA" ;
VAL_ 1880 fluidLvlCount_BMS25 255 "SNA" ;
VAL_ 1880 fluidLvlSensr2_BMS25 3 "FLUIDLEVEL_ERROR" 2 "FLUIDLEVEL_OIL" 1 "FLUIDLEVEL_AIR" 0 "FLUIDLEVEL_SNA" ;
VAL_ 1880 fluidLvlSensr1_BMS25 3 "FLUIDLEVEL_ERROR" 2 "FLUIDLEVEL_OIL" 1 "FLUIDLEVEL_AIR" 0 "FLUIDLEVEL_SNA" ;
VAL_ 1880 pumpSpeedReqVhcleSpeed_BMS25 255 "SNA" ;
VAL_ 1880 appTaskBSWCpuUsage_BMS25 255 "SNA" ;
VAL_ 1880 appTask200HzCpuUsage_BMS25 255 "SNA" ;
VAL_ 1880 pyroState_BMS25 7 "PYRO_FIRE" 6 "PYRO_DIAG_PASS" 5 "PYRO_DIAG_FAIL" 4 "PYRO_DIAG_LS_ON" 3 "PYRO_DIAG_OPEN" 2 "PYRO_DIAG_HS_ON" 1 "PYRO_DIAG_INIT" 0 "PYRO_INACTIVE" ;
VAL_ 1880 ecuSerialNrChar15_BMS25 90 "'Z'" 89 "'Y'" 88 "'X'" 87 "'W'" 86 "'V'" 85 "'U'" 84 "'T'" 83 "'S'" 82 "'R'" 81 "'Q'" 80 "'P'" 79 "'O'" 78 "'N'" 77 "'M'" 76 "'L'" 75 "'K'" 74 "'J'" 73 "'I'" 72 "'H'" 71 "'G'" 70 "'F'" 69 "'E'" 68 "'D'" 67 "'C'" 66 "'B'" 65 "'A'" 57 "'9'" 56 "'8'" 55 "'7'" 54 "'6'" 53 "'5'" 52 "'4'" 51 "'3'" 50 "'2'" 49 "'1'" 48 "'0'" ;
VAL_ 1880 ecuSerialNrChar14_BMS25 90 "'Z'" 89 "'Y'" 88 "'X'" 87 "'W'" 86 "'V'" 85 "'U'" 84 "'T'" 83 "'S'" 82 "'R'" 81 "'Q'" 80 "'P'" 79 "'O'" 78 "'N'" 77 "'M'" 76 "'L'" 75 "'K'" 74 "'J'" 73 "'I'" 72 "'H'" 71 "'G'" 70 "'F'" 69 "'E'" 68 "'D'" 67 "'C'" 66 "'B'" 65 "'A'" 57 "'9'" 56 "'8'" 55 "'7'" 54 "'6'" 53 "'5'" 52 "'4'" 51 "'3'" 50 "'2'" 49 "'1'" 48 "'0'" ;
VAL_ 1880 ecuSerialNrChar13_BMS25 90 "'Z'" 89 "'Y'" 88 "'X'" 87 "'W'" 86 "'V'" 85 "'U'" 84 "'T'" 83 "'S'" 82 "'R'" 81 "'Q'" 80 "'P'" 79 "'O'" 78 "'N'" 77 "'M'" 76 "'L'" 75 "'K'" 74 "'J'" 73 "'I'" 72 "'H'" 71 "'G'" 70 "'F'" 69 "'E'" 68 "'D'" 67 "'C'" 66 "'B'" 65 "'A'" 57 "'9'" 56 "'8'" 55 "'7'" 54 "'6'" 53 "'5'" 52 "'4'" 51 "'3'" 50 "'2'" 49 "'1'" 48 "'0'" ;
VAL_ 1880 ecuSerialNrChar12_BMS25 90 "'Z'" 89 "'Y'" 88 "'X'" 87 "'W'" 86 "'V'" 85 "'U'" 84 "'T'" 83 "'S'" 82 "'R'" 81 "'Q'" 80 "'P'" 79 "'O'" 78 "'N'" 77 "'M'" 76 "'L'" 75 "'K'" 74 "'J'" 73 "'I'" 72 "'H'" 71 "'G'" 70 "'F'" 69 "'E'" 68 "'D'" 67 "'C'" 66 "'B'" 65 "'A'" 57 "'9'" 56 "'8'" 55 "'7'" 54 "'6'" 53 "'5'" 52 "'4'" 51 "'3'" 50 "'2'" 49 "'1'" 48 "'0'" ;
VAL_ 1880 ecuSerialNrChar11_BMS25 90 "'Z'" 89 "'Y'" 88 "'X'" 87 "'W'" 86 "'V'" 85 "'U'" 84 "'T'" 83 "'S'" 82 "'R'" 81 "'Q'" 80 "'P'" 79 "'O'" 78 "'N'" 77 "'M'" 76 "'L'" 75 "'K'" 74 "'J'" 73 "'I'" 72 "'H'" 71 "'G'" 70 "'F'" 69 "'E'" 68 "'D'" 67 "'C'" 66 "'B'" 65 "'A'" 57 "'9'" 56 "'8'" 55 "'7'" 54 "'6'" 53 "'5'" 52 "'4'" 51 "'3'" 50 "'2'" 49 "'1'" 48 "'0'" ;
VAL_ 1880 ecuSerialNrChar10_BMS25 90 "'Z'" 89 "'Y'" 88 "'X'" 87 "'W'" 86 "'V'" 85 "'U'" 84 "'T'" 83 "'S'" 82 "'R'" 81 "'Q'" 80 "'P'" 79 "'O'" 78 "'N'" 77 "'M'" 76 "'L'" 75 "'K'" 74 "'J'" 73 "'I'" 72 "'H'" 71 "'G'" 70 "'F'" 69 "'E'" 68 "'D'" 67 "'C'" 66 "'B'" 65 "'A'" 57 "'9'" 56 "'8'" 55 "'7'" 54 "'6'" 53 "'5'" 52 "'4'" 51 "'3'" 50 "'2'" 49 "'1'" 48 "'0'" ;
VAL_ 1880 ecuSerialNrChar09_BMS25 90 "'Z'" 89 "'Y'" 88 "'X'" 87 "'W'" 86 "'V'" 85 "'U'" 84 "'T'" 83 "'S'" 82 "'R'" 81 "'Q'" 80 "'P'" 79 "'O'" 78 "'N'" 77 "'M'" 76 "'L'" 75 "'K'" 74 "'J'" 73 "'I'" 72 "'H'" 71 "'G'" 70 "'F'" 69 "'E'" 68 "'D'" 67 "'C'" 66 "'B'" 65 "'A'" 57 "'9'" 56 "'8'" 55 "'7'" 54 "'6'" 53 "'5'" 52 "'4'" 51 "'3'" 50 "'2'" 49 "'1'" 48 "'0'" ;
VAL_ 1880 ecuSerialNrChar08_BMS25 90 "'Z'" 89 "'Y'" 88 "'X'" 87 "'W'" 86 "'V'" 85 "'U'" 84 "'T'" 83 "'S'" 82 "'R'" 81 "'Q'" 80 "'P'" 79 "'O'" 78 "'N'" 77 "'M'" 76 "'L'" 75 "'K'" 74 "'J'" 73 "'I'" 72 "'H'" 71 "'G'" 70 "'F'" 69 "'E'" 68 "'D'" 67 "'C'" 66 "'B'" 65 "'A'" 57 "'9'" 56 "'8'" 55 "'7'" 54 "'6'" 53 "'5'" 52 "'4'" 51 "'3'" 50 "'2'" 49 "'1'" 48 "'0'" ;
VAL_ 1880 ecuSerialNrChar07_BMS25 90 "'Z'" 89 "'Y'" 88 "'X'" 87 "'W'" 86 "'V'" 85 "'U'" 84 "'T'" 83 "'S'" 82 "'R'" 81 "'Q'" 80 "'P'" 79 "'O'" 78 "'N'" 77 "'M'" 76 "'L'" 75 "'K'" 74 "'J'" 73 "'I'" 72 "'H'" 71 "'G'" 70 "'F'" 69 "'E'" 68 "'D'" 67 "'C'" 66 "'B'" 65 "'A'" 57 "'9'" 56 "'8'" 55 "'7'" 54 "'6'" 53 "'5'" 52 "'4'" 51 "'3'" 50 "'2'" 49 "'1'" 48 "'0'" ;
VAL_ 1880 ecuSerialNrChar06_BMS25 90 "'Z'" 89 "'Y'" 88 "'X'" 87 "'W'" 86 "'V'" 85 "'U'" 84 "'T'" 83 "'S'" 82 "'R'" 81 "'Q'" 80 "'P'" 79 "'O'" 78 "'N'" 77 "'M'" 76 "'L'" 75 "'K'" 74 "'J'" 73 "'I'" 72 "'H'" 71 "'G'" 70 "'F'" 69 "'E'" 68 "'D'" 67 "'C'" 66 "'B'" 65 "'A'" 57 "'9'" 56 "'8'" 55 "'7'" 54 "'6'" 53 "'5'" 52 "'4'" 51 "'3'" 50 "'2'" 49 "'1'" 48 "'0'" ;
VAL_ 1880 ecuSerialNrChar05_BMS25 90 "'Z'" 89 "'Y'" 88 "'X'" 87 "'W'" 86 "'V'" 85 "'U'" 84 "'T'" 83 "'S'" 82 "'R'" 81 "'Q'" 80 "'P'" 79 "'O'" 78 "'N'" 77 "'M'" 76 "'L'" 75 "'K'" 74 "'J'" 73 "'I'" 72 "'H'" 71 "'G'" 70 "'F'" 69 "'E'" 68 "'D'" 67 "'C'" 66 "'B'" 65 "'A'" 57 "'9'" 56 "'8'" 55 "'7'" 54 "'6'" 53 "'5'" 52 "'4'" 51 "'3'" 50 "'2'" 49 "'1'" 48 "'0'" ;
VAL_ 1880 analogGPIO1Current_BMS25 255 "SNA" ;
VAL_ 1880 analogGPIO1Volt_BMS25 255 "SNA" ;
VAL_ 1880 analogGPIO2Current_BMS25 255 "SNA" ;
VAL_ 1880 analogGPIO2Volt_BMS25 255 "SNA" ;
VAL_ 1880 pumpSpeedReqLoadValue_BMS25 255 "SNA" ;
VAL_ 1880 ssaRTMonth_BMS25 255 "SNA" ;
VAL_ 1880 ssaRTDay_BMS25 255 "SNA" ;
VAL_ 1880 appTask50HzStackUsage_BMS25 255 "SNA" ;
VAL_ 1880 OBDMILRequested_BMS25 3 "MIL_SNA" 1 "MIL_ON" 0 "MIL_OFF" ;
VAL_ 1880 OBDConfirmedDTCsCount_BMS25 255 "SNA" ;
VAL_ 1880 OBDFirstConfirmedDTC_BMS25 255 "SNA" ;
VAL_ 1880 OBDPermanentDTCCount_BMS25 255 "SNA" ;
VAL_ 1880 OBDFirstPermanentDTC_BMS25 255 "SNA" ;
VAL_ 1880 nmStartupReason_BMS25 15 "NM_STARTUP_INVALID" 7 "NM_STARTUP_TESTERPRESENT" 6 "NM_STARTUP_RQ" 5 "NM_STARTUP_CAN" 4 "NM_STARTUP_THERMALEVENT" 3 "NM_STARTUP_AUXCONTACTORS" 2 "NM_STARTUP_CONTACTORS" 1 "NM_STARTUP_KEY" 0 "NM_STARTUP_NOSTARTUP" ;
VAL_ 1880 contactorType_BMS25 15 "SNA" 1 "GV240_12V" 0 "CTR_TYPE_CALIBRATION (GV240_24V)" ;
VAL_ 1880 activeIsoTestDuration_BMS25 255 "SNA" ;
VAL_ 1880 balancingState_BMS25 6 "BALANCING_OFF_TEMP_SHUTDOWN" 5 "BALANCING_OFF_VOLTAGE_SHUTDOWN" 4 "BALANCING_ON_DCM_EEPROM" 3 "BALANCING_ON_DCM_BRICK" 2 "BALANCING_ON_DCM_PATTERN" 1 "BALANCING_ON_ME_APP" 0 "BALANCING_OFF" ;
VAL_ 1880 chronoStackWrCnt_BMS25 -1 "SNA" ;
VAL_ 1880 wakeReason_BMS25 6 "ECU_WAKEREASON_MCUWDG" 14 "ECU_WAKEREASON_INIT" 15 "ECU_WAKEREASON_UNKNOWN" 5 "ECU_WAKEREASON_AUTO" 4 "ECU_WAKEREASON_POR" 3 "ECU_WAKEREASON_CLOCK" 2 "ECU_WAKEREASON_PRESSURE" 1 "ECU_WAKEREASON_CAN" 0 "ECU_WAKEREASON_KEY" ;
VAL_ 1880 coolantOutletTemperature_BMS25 255 "SNA" ;
VAL_ 1880 coolantInletTemperature_BMS25 255 "SNA" ;
VAL_ 1880 variantCodingCount_BMS25 65535 "SNA" ;
VAL_ 1880 SWVersionCusApp_BMS25 -1 "SNA" ;
VAL_ 1880 contactorOpenRequest_BMS25 15 "CTR_OPEN_INVALID" 1 "CTR_OPEN_IMMEDIATE" 0 "CTR_OPEN_FAST " ;
VAL_ 1880 maxBrickVoltageChargeLimit_BMS25 65535 "SNA" ;
VAL_ 1880 desiccantTimer_BMS25 -1 "SNA" ;
VAL_ 1880 batSwitchOpenReason_BMS25 65535 "SNA" ;
VAL_ 1880 balancingTime_BMS25 65535 "SNA" ;
VAL_ 1880 ecuSerialNrChar01_BMS25 90 "'Z'" 89 "'Y'" 88 "'X'" 87 "'W'" 86 "'V'" 85 "'U'" 84 "'T'" 83 "'S'" 82 "'R'" 81 "'Q'" 80 "'P'" 79 "'O'" 78 "'N'" 77 "'M'" 76 "'L'" 75 "'K'" 74 "'J'" 73 "'I'" 72 "'H'" 71 "'G'" 70 "'F'" 69 "'E'" 68 "'D'" 67 "'C'" 66 "'B'" 65 "'A'" 57 "'9'" 56 "'8'" 55 "'7'" 54 "'6'" 53 "'5'" 52 "'4'" 51 "'3'" 50 "'2'" 49 "'1'" 48 "'0'" ;
VAL_ 1880 ecuSerialNrChar02_BMS25 90 "'Z'" 89 "'Y'" 88 "'X'" 87 "'W'" 86 "'V'" 85 "'U'" 84 "'T'" 83 "'S'" 82 "'R'" 81 "'Q'" 80 "'P'" 79 "'O'" 78 "'N'" 77 "'M'" 76 "'L'" 75 "'K'" 74 "'J'" 73 "'I'" 72 "'H'" 71 "'G'" 70 "'F'" 69 "'E'" 68 "'D'" 67 "'C'" 66 "'B'" 65 "'A'" 57 "'9'" 56 "'8'" 55 "'7'" 54 "'6'" 53 "'5'" 52 "'4'" 51 "'3'" 50 "'2'" 49 "'1'" 48 "'0'" ;
VAL_ 1880 ecuSerialNrChar03_BMS25 90 "'Z'" 89 "'Y'" 88 "'X'" 87 "'W'" 86 "'V'" 85 "'U'" 84 "'T'" 83 "'S'" 82 "'R'" 81 "'Q'" 80 "'P'" 79 "'O'" 78 "'N'" 77 "'M'" 76 "'L'" 75 "'K'" 74 "'J'" 73 "'I'" 72 "'H'" 71 "'G'" 70 "'F'" 69 "'E'" 68 "'D'" 67 "'C'" 66 "'B'" 65 "'A'" 57 "'9'" 56 "'8'" 55 "'7'" 54 "'6'" 53 "'5'" 52 "'4'" 51 "'3'" 50 "'2'" 49 "'1'" 48 "'0'" ;
VAL_ 1880 ecuSerialNrChar04_BMS25 90 "'Z'" 89 "'Y'" 88 "'X'" 87 "'W'" 86 "'V'" 85 "'U'" 84 "'T'" 83 "'S'" 82 "'R'" 81 "'Q'" 80 "'P'" 79 "'O'" 78 "'N'" 77 "'M'" 76 "'L'" 75 "'K'" 74 "'J'" 73 "'I'" 72 "'H'" 71 "'G'" 70 "'F'" 69 "'E'" 68 "'D'" 67 "'C'" 66 "'B'" 65 "'A'" 57 "'9'" 56 "'8'" 55 "'7'" 54 "'6'" 53 "'5'" 52 "'4'" 51 "'3'" 50 "'2'" 49 "'1'" 48 "'0'" ;
VAL_ 1880 ecuSerialNrChar16_BMS25 90 "'Z'" 89 "'Y'" 88 "'X'" 87 "'W'" 86 "'V'" 85 "'U'" 84 "'T'" 83 "'S'" 82 "'R'" 81 "'Q'" 80 "'P'" 79 "'O'" 78 "'N'" 77 "'M'" 76 "'L'" 75 "'K'" 74 "'J'" 73 "'I'" 72 "'H'" 71 "'G'" 70 "'F'" 69 "'E'" 68 "'D'" 67 "'C'" 66 "'B'" 65 "'A'" 57 "'9'" 56 "'8'" 55 "'7'" 54 "'6'" 53 "'5'" 52 "'4'" 51 "'3'" 50 "'2'" 49 "'1'" 48 "'0'" ;
VAL_ 1880 ecuSerialNrChar17_BMS25 90 "'Z'" 89 "'Y'" 88 "'X'" 87 "'W'" 86 "'V'" 85 "'U'" 84 "'T'" 83 "'S'" 82 "'R'" 81 "'Q'" 80 "'P'" 79 "'O'" 78 "'N'" 77 "'M'" 76 "'L'" 75 "'K'" 74 "'J'" 73 "'I'" 72 "'H'" 71 "'G'" 70 "'F'" 69 "'E'" 68 "'D'" 67 "'C'" 66 "'B'" 65 "'A'" 57 "'9'" 56 "'8'" 55 "'7'" 54 "'6'" 53 "'5'" 52 "'4'" 51 "'3'" 50 "'2'" 49 "'1'" 48 "'0'" ;
VAL_ 1880 ecuSerialNrChar18_BMS25 90 "'Z'" 89 "'Y'" 88 "'X'" 87 "'W'" 86 "'V'" 85 "'U'" 84 "'T'" 83 "'S'" 82 "'R'" 81 "'Q'" 80 "'P'" 79 "'O'" 78 "'N'" 77 "'M'" 76 "'L'" 75 "'K'" 74 "'J'" 73 "'I'" 72 "'H'" 71 "'G'" 70 "'F'" 69 "'E'" 68 "'D'" 67 "'C'" 66 "'B'" 65 "'A'" 57 "'9'" 56 "'8'" 55 "'7'" 54 "'6'" 53 "'5'" 52 "'4'" 51 "'3'" 50 "'2'" 49 "'1'" 48 "'0'" ;
VAL_ 1880 ecuSerialNrChar19_BMS25 90 "'Z'" 89 "'Y'" 88 "'X'" 87 "'W'" 86 "'V'" 85 "'U'" 84 "'T'" 83 "'S'" 82 "'R'" 81 "'Q'" 80 "'P'" 79 "'O'" 78 "'N'" 77 "'M'" 76 "'L'" 75 "'K'" 74 "'J'" 73 "'I'" 72 "'H'" 71 "'G'" 70 "'F'" 69 "'E'" 68 "'D'" 67 "'C'" 66 "'B'" 65 "'A'" 57 "'9'" 56 "'8'" 55 "'7'" 54 "'6'" 53 "'5'" 52 "'4'" 51 "'3'" 50 "'2'" 49 "'1'" 48 "'0'" ;
VAL_ 1880 maxModuleTemperature_BMS25 255 "SNA" ;
VAL_ 1880 meanModuleTemperature_BMS25 255 "SNA" ;
VAL_ 1880 minModuleTemperature_BMS25 255 "SNA" ;
VAL_ 1880 nmOperationalMode_BMS25 2 "NM_BUSSLEEP_MODE" 1 "NM_PREPAREBUSSLEEP_MODE" 0 "NM_NETWORK_MODE" ;
VAL_ 1880 nmNetworkMode_BMS25 2 "NM_MODE_READY_SLEEP" 1 "NM_MODE_NORMAL_OPERATION" 0 "NM_MODE_REPEAT_MESSAGE" ;
VAL_ 1880 nmNetworkState_BMS25 1 "NM_STATE_REQUESTED" 0 "NM_STATE_RELEASED" ;
VAL_ 1880 ecuState_BMS25 4 "ECU_SLEEPING" 3 "ECU_GOING_TO_SLEEP" 2 "ECU_AWAKE_CAN_ACTIVE" 1 "ECU_AWAKE_CAN_INACTIVE" 0 "ECU_INIT" ;
VAL_ 1880 SPIRxTxDiag_BMS25 3 "SPIRXTX_SLAVEREQUESTPACKAGE" 2 "SPIRXTX_CRC" 1 "SPIRXTX_WRONG_PACKETINDEX" 0 "SPIRXTX_ALL_OK" ;
VAL_ 1880 minSOC_BMS25 65535 "SNA" ;
VAL_ 1880 maxSOC_BMS25 65535 "SNA" ;
VAL_ 1880 appTaskMaxCpuUsage_BMS25 255 "SNA" ;
VAL_ 1880 appTaskCpuUsage_BMS25 255 "SNA" ;
VAL_ 1880 appTask50HzCpuUsage_BMS25 255 "SNA" ;
VAL_ 1880 appTask10HzStackUsage_BMS25 255 "SNA" ;
VAL_ 1880 appTask100HzCpuUsage_BMS25 255 "SNA" ;
VAL_ 1880 appTask10HzCpuUsage_BMS25 255 "SNA" ;
VAL_ 1880 appTask1HzCpuUsage_BMS25 255 "SNA" ;
VAL_ 1880 pumpSpeedReq_BMS25 255 "SNA" ;
VAL_ 1880 regenCurrPredBrickVOffset_BMS25 255 "SNA" ;
VAL_ 1880 dischgCurrPredBrickVOffset_BMS25 255 "SNA" ;
VAL_ 1880 PCANBusOffState_BMS25 3 "SNA" 2 "CAN_BUSOFF_PHASE2" 1 "CAN_BUSOFF_PHASE1" 0 "CAN_BUSOFF_NORMAL" ;
VAL_ 1880 SCANBusOffState_BMS25 3 "SNA" 2 "CAN_BUSOFF_PHASE2" 1 "CAN_BUSOFF_PHASE1" 0 "CAN_BUSOFF_NORMAL" ;
VAL_ 1880 PTCANBusOffState_BMS25 3 "SNA" 2 "CAN_BUSOFF_PHASE2" 1 "CAN_BUSOFF_PHASE1" 0 "CAN_BUSOFF_NORMAL" ;
VAL_ 1880 customerModelVsCellType_BMS25 0 "L" 1 "P" ;
VAL_ 1880 balancingVoltageTarget_BMS25 255 "VOLTAGEBASED_BALANCING_INACTIVE" ;
VAL_ 1880 analogAddr5_BMS25 255 "SNA" ;
VAL_ 1880 analogAddr0_BMS25 255 "SNA" ;
VAL_ 1880 analogAddr4_BMS25 255 "SNA" ;
VAL_ 1880 analogAddr3_BMS25 255 "SNA" ;
VAL_ 1880 analogAddr2_BMS25 255 "SNA" ;
VAL_ 1880 analogAddr1_BMS25 255 "SNA" ;
VAL_ 1880 debugSlowMpex1_BMS25 43 "S43" 42 "S42" 41 "S41" 40 "S40" 39 "S39" 38 "S38" 37 "S37" 36 "S36" 0 "S00" 1 "S01" 2 "S02" 3 "S03" 4 "S04" 5 "S05" 6 "S06" 7 "S07" 8 "S08" 9 "S09" 10 "S10" 11 "S11" 12 "S12" 13 "S13" 14 "S14" 15 "S15" 16 "S16" 17 "S17" 18 "S18" 19 "S19" 20 "S20" 21 "S21" 22 "S22" 23 "S23" 24 "S24" 25 "S25" 26 "S26" 27 "S27" 28 "S28" 29 "S29" 30 "S30" 31 "S31" 32 "S32" 33 "S33" 34 "S34" 35 "S35" ;
VAL_ 1880 analog3V3DSupply_BMS25 255 "SNA" ;
VAL_ 1880 pressure_BMS25 255 "SNA" ;
VAL_ 1880 analog3P3VA_BMS25 255 "SNA" ;
VAL_ 1880 analog5VA_BMS25 255 "SNA" ;
VAL_ 1880 analog5VD_BMS25 255 "SNA" ;
VAL_ 1880 analog5VSensorSupply_BMS25 255 "SNA" ;
VAL_ 1880 analog6V5_BMS25 255 "SNA" ;
VAL_ 1880 isolationResistanceIntern_BMS25 65535 "SNA" ;
VAL_ 1880 isolationResistanceExtern_BMS25 65535 "SNA" ;
VAL_ 1880 linkVoltage_BMS25 65535 "SNA" ;
VAL_ 1880 eepromWriteCyclesBasics_BMS25 65535 "SNA" ;
VAL_ 1880 eepromBlockIndex_BMS25 255 "SNA" ;
VAL_ 1880 regenCurrentOpLimit_BMS25 65535 "SNA" ;
VAL_ 1880 regenCurrentErrorLimit_BMS25 65535 "SNA" ;
VAL_ 1880 lifetime_BMS25 -1 "SNA" ;
VAL_ 1880 eepromReadTime_BMS25 255 "SNA" ;
VAL_ 1880 pumpSpeedReqMaxT_BMS25 65535 "SNA" ;
VAL_ 1880 pumpSpeedReqDeltaT_BMS25 65535 "SNA" ;
VAL_ 1880 packVoltageCMB_BMS25 65535 "SNA" ;
VAL_ 1880 ctrOffTime_BMS25 65535 "SNA" ;
VAL_ 1880 sleepTime_BMS25 65535 "SNA" ;
VAL_ 1880 SPIRxTxTimeAllPckts_BMS25 255 "SNA" ;
VAL_ 1880 isolationTestState_BMS25 3 "ISOLATION_DISABLED" 2 "ISOLATION_TEST_NEG" 1 "ISOLATION_TEST_POS" 0 "ISOLATION_OFF" ;
VAL_ 1752 SPIRxTxHeaderMux3Status_BMS25 1 "SPIRXTX_MUX_MISSING" 0 "SPIRXTX_MUX_GOOD" ;
VAL_ 1752 SPIRxTxHeaderMux2Status_BMS25 1 "SPIRXTX_MUX_MISSING" 0 "SPIRXTX_MUX_GOOD" ;
VAL_ 1752 SPIRxTxHeaderMux1Status_BMS25 1 "SPIRXTX_MUX_MISSING" 0 "SPIRXTX_MUX_GOOD" ;
VAL_ 1752 SPIRxTxHeaderMux0Status_BMS25 1 "SPIRXTX_MUX_MISSING" 0 "SPIRXTX_MUX_GOOD" ;
VAL_ 1752 activeIsoState_BMS25 4 "ISOACTV_COMPLETE" 3 "ISOACTV_TIMEOUT" 2 "ISOACTV_PENDING" 1 "ISOACTV_INIT" 0 "ISOACTV_OFF" ;
VAL_ 1752 activeIsoNegLink_BMS25 65535 "SNA" ;
VAL_ 1752 activeIsoPosLink_BMS25 65535 "SNA" ;
VAL_ 1752 activeIsoPosBuffer_BMS25 65535 "SNA" ;
VAL_ 1752 activeIsoNegBuffer_BMS25 65535 "SNA" ;
VAL_ 1752 activeIsoResRaw_BMS25 65535 "SNA" ;
VAL_ 1752 activeIsoResFilter_BMS25 65535 "SNA" ;
VAL_ 1752 contactorStateAux_BMS25 4 "CTR_INVALID" 3 "CTR_STRING_OPENING" 2 "CTR_STRING_ON" 1 "CTR_STRING_PRECHARGE" 0 "CTR_STRING_OFF" ;
VAL_ 1752 batSwitchOpenReqEssMstr_BMS25 3 "INVALID" 2 "IMMEDIATE_OPEN" 1 "FAST_OPEN" 0 "DO_NOT_OPEN" ;
VAL_ 1752 packShutdownTarget_BMS25 3 "BMS_INVALID" 1 "BMS_STRING_FAULT" 0 "BMS_STANDBY" ;
VAL_ 1752 weldedState_BMS25 3 "CTR_NEG1_WELDED" 2 "CTR_POS1_WELDED" 0 "CTR_NOTWELDED" 1 "CTR_BOTH_WELDED" ;
VAL_ 1752 contactorStateRq_BMS25 4 "CTR_INVALID" 3 "CTR_STRING_OPENING" 2 "CTR_STRING_ON" 1 "CTR_STRING_PRECHARGE" 0 "CTR_STRING_OFF" ;
VAL_ 1752 strMstrStrPrechgState_BMS25 7 "NOT_A_STRING_MASTER" 6 "STRING_PRCHG_NDEF2" 5 "STRING_PRCHG_NDEF1" 4 "STRING_PRCHG_FAULT" 3 "STRING_PRCHG_ON" 2 "STRING_PRCHG_ACTV" 1 "STRING_PRCHG_INIT" 0 "STRING_PRCHG_OFF" ;
VAL_ 1752 packShutdwnTmrQual_BMS25 0 "SHUTDOWN_ACTIVE" 1 "SHUTDOWN_INACTIVE" ;
VAL_ 1752 packStateRequest_BMS25 7 "STATE_INVALID" 6 "STATE_SYSTEM_FAULT" 5 "STATE_STRING_FAULT" 4 "STATE_LIMPHOME" 3 "STATE_ACCESSORY" 2 "STATE_CHARGE" 1 "STATE_DRIVE" 0 "STATE_STANDBY" ;
VAL_ 1752 packState_BMS25 15 "STATE_INVALID" 6 "STATE_ESS_FAULT" 5 "STATE_STRING_FAULT" 4 "STATE_LIMPHOME" 3 "STATE_ACCESSORY" 2 "STATE_CHARGE" 1 "STATE_DRIVE" 0 "STATE_STANDBY" ;
VAL_ 1752 SPIRxTxTimer_BMS25 255 "SNA" ;
VAL_ 1752 moduleTMinMaxMeanQual_BMS25 1 "QUAL_ERROR" 0 "QUAL_VALID" ;
VAL_ 1752 currentQual_BMS25 1 "QUAL_ERROR" 0 "QUAL_VALID" ;
VAL_ 1752 brickVMinMaxMeanQual_BMS25 1 "QUAL_ERROR" 0 "QUAL_VALID" ;
VAL_ 1752 debugFastMpex1_BMS25 0 "F00" 1 "F01" 2 "F02" 3 "F03" 4 "F04" 5 "F05" 6 "F06" 7 "F07" 8 "F08" 9 "F09" 10 "F10" 11 "F11" 12 "F12" 13 "F13" 14 "F14" 15 "F15" ;
VAL_ 1752 itemState_BMS25 3 "ITEM_INVALID" 2 "ITEM_EMERGENCY" 1 "ITEM_OFF" 0 "ITEM_ON" ;
VAL_ 1752 posLink_BMS25 255 "SNA" ;
VAL_ 1752 posPack_BMS25 255 "SNA" ;
VAL_ 1752 prechargeState_BMS25 14 "CTR_PRCHG_WAIT_CY_MATCH" 15 "CTR_PRCHG_NEG_OPEN" 13 "CTR_PRCHG_POS_WELD_CHECK" 12 "CTR_PRCHG_PRE_COND_CHECK" 11 "CTR_PRCHG_NEG2_WELD_CHECK" 10 "CTR_PRCHG_CLOSEMID" 9 "CTR_PRCHG_CLOSEAUX" 8 "CTR_PRCHG_FAILED" 7 "CTR_PRCHG_COMPLETE" 6 "CTR_PRCHG_CLOSE_POS" 5 "CTR_PRCHG_MONITOR_VOLTAGE" 4 "CTR_PRCHG_CLOSE_NEG" 3 "CTR_PRCHG_NEG_WELD_CHECK" 2 "CTR_PRCHG_CLOSE_RELAY" 1 "CTR_PRCHG_WELD_CHECK" 0 "CTR_PRCHG_OFF" ;
VAL_ 1752 contactorState_BMS25 4 "CTR_INVALID" 3 "CTR_STRING_OPENING" 2 "CTR_STRING_ON" 1 "CTR_STRING_PRECHARGE" 0 "CTR_STRING_OFF" ;
VAL_ 1560 DEMEventMultiplexor_BMS25 319 "DEM319_HV_DISABLE_DURING_S" 318 "DEM318_HV_ENABLE_IMPLAUSIB" 317 "DEM317_STRING_SUSPECT_OPEN" 316 "DEM316_UNEXPCTD_BMS_ON_CAN" 315 "DEM315_HV_WITHSTAND_TESTS_" 314 "DEM314_OBC_PILOT_ERROR" 313 "DEM313_OBC_PILOT_HIGH" 312 "DEM312_OBC_PROXIMITY_ERROR" 311 "DEM311_CTRS_END_OF_LIFE_WA" 310 "DEM310_BMSMIA_STRNGMSTR_AL" 309 "DEM309_VOLTAGE_BRICKOV_WAR" 308 "DEM308_PRESSURE_FLT" 307 "DEM307_PRESSURE_MIA" 306 "DEM306_SW_VERSION_MISMATCH" 305 "DEM305_MODULET_OVERTEMP_WA" 304 "DEM304_PCHG_OPENCIRCUIT_IN" 303 "DEM303_MODULET_UNDERTEMP_W" 302 "DEM302_MODULET_UT" 301 "DEM301_FUSI_LOCK" 300 "DEM300_DEBUG_SM_DISABLED" 299 "DEM299_5V_SENSOR_SUPPLY_OU" 298 "DEM298_IMPL_DRIVE_REQUEST" 297 "DEM297_PCHG2_OPENCIRCUIT" 296 "DEM296_CTRSAUX_IMPLAUSIBLE" 295 "DEM295_CTRSAUX_LINKV_UNSAF" 294 "DEM294_CANRX_PT_EMERGENCY" 293 "DEM293_SBC_LDT_IMPLAUSIBLE" 292 "DEM292_NUM_EXPECTED_STRING" 291 "DEM291_NUM_EXPECTED_STRING" 290 "DEM290_CMB_ONBOARD_DEFECT" 289 "DEM289_TEMP_STATE_LATCHED" 288 "DEM288_CURR_STATE_LATCHED" 1 "DEM001_POWERUP" 2 "DEM002_VOLTAGE_BRICK_OV" 3 "DEM003_VOLTAGE_BRICK_UV" 4 "DEM004_VOLTAGE_BRICK_SNA" 5 "DEM005_VOLTAGE_BRICK_IMBAL" 6 "DEM006_VOLTAGE_CAPCY_IMBAL" 7 "DEM007_MODULET_HIGH_DELTA" 8 "DEM008_VOLTAGE_PACK_UV" 9 "DEM009_VOLTAGE_PACK_OV" 10 "DEM010_VOLTAGE_PACK_PLAUSI" 11 "DEM011_VOLTAGE_PCKLINK_MIS" 12 "DEM012_VOLTAGE_BMS_SUPPLY" 13 "DEM013_ADC_ERROR" 14 "DEM014_MODULET_OT" 15 "DEM015_MODULET_SNA" 16 "DEM016_MODULET_LIMPHOME" 17 "DEM017_COOLING_SYS_LHOME" 18 "DEM018_HVIL_LIMPHOME" 19 "DEM019_HVIL_ESS_INHIBIT" 20 "DEM020_MODULET_CHANGE" 21 "DEM021_LG_MAVD_FAULT" 22 "DEM022_LG_RDV_FAULT" 23 "DEM023_BMS_ONBOARDT_SNA" 24 "DEM024_BMS_ONBOARDRH_OH" 25 "DEM025_BMS_ONBOARDRH_SNA" 26 "DEM026_CURRENT_OVERCHARGE" 27 "DEM027_CURRENT_OVERDISCHGE" 28 "DEM028_CURRENT_INVALID" 29 "DEM029_CURRENT_SHORTCIRCT" 30 "DEM030_CRASH_CAN_LATCH" 31 "DEM031_EEPROM_FAIL" 32 "DEM032_PCHG_PACKS_CONNECT" 33 "DEM033_PCHG_ILLEGAL_PRCHG" 34 "DEM034_PCHG_RELAY_FAIL" 35 "DEM035_PCHG_NEG_WELD" 36 "DEM036_PCHG_NEG_PULLIN" 37 "DEM037_PCHG_SHORTCIRCUIT" 38 "DEM038_PCHG_OPENCIRCUIT" 39 "DEM039_PCHG_TIMEOUT" 40 "DEM040_PCHG_FAILED" 41 "DEM041_HVIL_SHUTDOWN" 42 "DEM042_PCHG_POS_WELD" 43 "DEM043_HV_LOCK_TRANSPORT" 44 "DEM044_CTRS_END_OF_LIFE" 45 "DEM045_CTRS_CTRPWRV_HI" 46 "DEM046_CTRS_COILCURR_LOW" 47 "DEM047_CTRS_COILCURR_HIGH" 48 "DEM048_CTRS_CTRPWRV_LOW" 49 "DEM049_CHGE_ILLEGAL_DISCHG" 50 "DEM050_STARTUP_CONDITIONS" 51 "DEM051_VOLTAGE_BMS_SUPPLYH" 52 "DEM052_SAFETYSPI_FAIL" 53 "DEM053_WATCHDOG_ERRORPIN" 54 "DEM054_SAFESTATE_TRIGGERED" 55 "DEM055_DEBUG_CMND_ACTIVE" 56 "DEM056_CRASH_CAN" 57 "DEM057_ISO_EXT_STRAT_4" 58 "DEM058_ISO_EXT_RES_ERR" 59 "DEM059_ISO_EXT_RES_WARN" 60 "DEM060_ISO_INT_RES_ERR" 61 "DEM061_ISO_INT_RES_WARN" 62 "DEM062_EMERGENCY_OPERATION" 63 "DEM063_ENDOFDRIVE" 64 "DEM064_STRINGV_IMBALANCE" 65 "DEM065_STRING_FAULT" 66 "DEM066_ESS_FAULT" 67 "DEM067_ISO_EXT_STRAT_3" 68 "DEM068_MODULE_COUNT_INVALI" 69 "DEM069_PT_MIA" 70 "DEM070_BMSMIA_STRNGMSTR_01" 71 "DEM071_BMSMIA_STRNGMSTR_05" 72 "DEM072_BMSMIA_STRNGMSTR_09" 73 "DEM073_BMSMIA_STRNGMSTR_13" 74 "DEM074_BMSMIA_STRNGMSTR_17" 75 "DEM075_BMSMIA_STRNGMSTR_21" 76 "DEM076_BMSMIA_STRNGMSTR_25" 77 "DEM077_BMSMIA_STRNGMSTR_29" 78 "DEM078_BMSMIA_STRNGMSTR_33" 79 "DEM079_BMSMIA_STRNGMSTR_37" 80 "DEM080_BMSMIA_STRNGMSTR_41" 81 "DEM081_BMSMIA_STRNGMSTR_45" 82 "DEM082_BMSMIA_STRNGMSTR_49" 83 "DEM083_BMSMIA_STRNGMSTR_53" 84 "DEM084_BMSMIA_STRNGMSTR_57" 85 "DEM085_BMSMIA_STRNGMSTR_61" 86 "DEM086_ESSCURRENT_SHORT" 87 "DEM087_PT_MIA_SHUTDOWN" 88 "DEM088_OUTLET_NTC_HI" 89 "DEM089_OUTLET_NTC_LO" 90 "DEM090_BMSMIA_ESSMASTER" 91 "DEM091_PCHG_RES_OVERHEAT" 92 "DEM092_BMSMIA_STRNGSLAVE_0" 93 "DEM093_BMSMIA_STRNGSLAVE_1" 94 "DEM094_BMSMIA_STRNGSLAVE_2" 95 "DEM095_BMSMIA_STRNGSLAVE_3" 96 "DEM096_SC_STATE_SELFTEST" 97 "DEM097_SC_STATE_TEMP" 98 "DEM098_SC_STATE_VOLTAGE" 99 "DEM099_SC_STATE_HVIL" 100 "DEM100_SC_STATE_CONTACTORS" 101 "DEM101_SC_STATE_CURRENT" 102 "DEM102_SC_STATE_CANRX" 103 "DEM103_SC_STATE_CRASH" 104 "DEM104_SC_STATE_CCTRL" 105 "DEM105_SC_STATE_CANTX" 106 "DEM106_SC_STATE_THERMALEVT" 107 "DEM107_SC_STATE_COOLANT" 108 "DEM108_SC_SELFTEST_SFTY_UC" 109 "DEM109_SC_TEMP_HIGH" 110 "DEM110_SC_TEMP_NTC_OPEN" 111 "DEM111_SC_TEMP_NTC_SHORT" 112 "DEM112_CMB_DISCONNECTED" 113 "DEM113_CMB_DEFECT" 114 "DEM114_CMB_COMMERROR" 115 "DEM115_SC_CURR_HALL_PWR_LO" 116 "DEM116_SC_CURR_HALL_VHIGH" 117 "DEM117_SC_CURR_HALL_ADC" 118 "DEM118_SC_CURR_HALL_VLOW" 119 "DEM119_SC_CURR_ISENSE_PWR" 120 "DEM120_SC_CURR_ISENSE1_MIA" 121 "DEM121_SC_CURR_ISENSE2_MIA" 122 "DEM122_SC_CURR_ISENSE3_MIA" 123 "DEM123_SC_CURR_ISENSE4_MIA" 124 "DEM124_SC_CURR_ISENSE5_MIA" 125 "DEM125_SC_CURR_ISENSE1_FLT" 126 "DEM126_SC_CURR_ISENSE2_FLT" 127 "DEM127_SC_CURR_ISENSE3_FLT" 128 "DEM128_SC_CURR_ISENSE4_FLT" 129 "DEM129_SC_CURR_ISENSE5_FLT" 130 "DEM130_SC_CURR_OFFSET" 131 "DEM131_SC_CURR_PLAUSI" 132 "DEM132_SC_CURR_CHARGE_HIGH" 133 "DEM133_SC_CURR_DSCHAR_HIGH" 134 "DEM134_SC_V_CMB_SUMOFCELL" 135 "DEM135_SC_V_SENSE_OPENWIRE" 136 "DEM136_SC_V_CMB_DRV_FROZEN" 137 "DEM137_SC_V_PACK_PLAUSI" 138 "DEM138_SC_HVIL_HW_FLT" 139 "DEM139_SC_HVIL_OPEN" 140 "DEM140_SC_HVIL_TO_SUP" 141 "DEM141_SC_HVIL_TO_CHAS" 142 "DEM142_SC_HVIL_R_HIGH" 143 "DEM143_SC_HVIL_SHORT" 144 "DEM144_SC_CN_ISO_FAIL" 145 "DEM145_HVIL_SYS" 146 "DEM146_SC_CN_POS1_WELDED" 147 "DEM147_SC_CN_NEG1_WELDED" 148 "DEM148_SC_CN_POS2_WELDED" 149 "DEM149_SC_CN_NEG2_WELDED" 150 "DEM150_SC_CN_POS3_WELDED" 151 "DEM151_SC_CN_NEG3_WELDED" 152 "DEM152_SC_CN_HIGH_CY" 153 "DEM153_SC_CN_ISOANDPOTWELD" 154 "DEM154_SC_TEMP_PLAUSI" 155 "DEM155_SC_CURR_HALL_PWR_HI" 156 "DEM156_SC_PYRO_TRIGGERED" 157 "DEM157_SC_PYRO_OPEN" 158 "DEM158_AUX_CTRS_END_OF_LIF" 159 "DEM159_SC_CANRX_PT_MIA" 160 "DEM160_SC_CANRX_PT_CRCALIV" 161 "DEM161_SC_CANRX_LIN_SHUTDN" 162 "DEM162_SC_CANRX_LIN_MIA" 163 "DEM163_SC_CRASH1" 164 "DEM164_SC_CRASH2" 165 "DEM165_SC_CRASHCAN" 166 "DEM166_SC_CCTRL_SELFTEST" 167 "DEM167_SC_CCTRL_DRIVER_FAU" 168 "DEM168_SC_CCTRL_HISIDESTCL" 169 "DEM169_SC_CCTRL_HISIDESTOP" 170 "DEM170_SC_CCTRL_LOSIDESTCL" 171 "DEM171_SC_CCTRL_HVCNDITION" 172 "DEM172_SC_CCTRL_POS1_OPN" 173 "DEM173_SC_CCTRL_POS2_OPN" 174 "DEM174_SC_CCTRL_POS3_OPN" 175 "DEM175_SC_CCTRL_NEG1_OPN" 176 "DEM176_SC_CCTRL_NEG2_OPN" 177 "DEM177_SC_CCTRL_PRE2_OPN" 178 "DEM178_SC_CCTRL_PRE1_OPN" 179 "DEM179_SC_CCTRL_LOSIDESTOP" 180 "DEM180_SC_CCTRL_UNEXPECTED" 181 "DEM181_SC_V_OUT_OF_RANGE" 182 "DEM182_SC_V_LATCHED_UVOV" 183 "DEM183_ISO_EXT_STRAT_2" 184 "DEM184_SC_CANTX_CTRS" 185 "DEM185_SC_CANTX_HVIL" 186 "DEM186_SC_CANTX_ISOL" 187 "DEM187_SC_SBC_WATCHDOG" 188 "DEM188_SC_SBC_FAULT" 189 "DEM189_SC_WATCHDOG" 190 "DEM190_SC_SELFTEST_RAM" 191 "DEM191_SC_SELFTEST_FLASH" 192 "DEM192_CMB_ONBOARDRH_OH" 193 "DEM193_CMB_ONBOARDRH_SNA" 194 "DEM194_CMB_ONBOARDT_OT" 195 "DEM195_CMB_ONBOARDT_CHANGE" 196 "DEM196_PRESSURE_CHANGE" 197 "DEM197_PRESSURE_OVER" 198 "DEM198_PRESSURE_UNDER" 199 "DEM199_PRESSURE_INVALID" 200 "DEM200_THERMAL_EVENT" 201 "DEM201_CMB_ONBOARDT_SNA" 202 "DEM202_REPLACE_DESICCANT" 203 "DEM203_COOLANT_FLOOD_FAULT" 204 "DEM204_LOW_BRICKCAPACITY" 205 "DEM205_BMS_ONBOARDT_OT" 206 "DEM206_HUMIDITY_CHANGE" 207 "DEM207_ISENSE_SUPPLY_CURR" 208 "DEM208_SOC_LOW" 209 "DEM209_SOC_TOOLOW" 210 "DEM210_SOC_TOOHIGH" 211 "DEM211_BALANCING_REQUIRED" 212 "DEM212_DEEP_DISCHARGE" 213 "DEM213_CAN1_BUS_OFF" 214 "DEM214_CAN2_BUS_OFF" 215 "DEM215_CAN3_BUS_OFF" 216 "DEM216_OUTLET_NTC_RATNAL" 217 "DEM217_FUSE_PACK" 218 "DEM218_FUSE_B_OPEN" 219 "DEM219_FUSE_C_OPEN" 220 "DEM220_FUSE_D_OPEN" 221 "DEM221_FUSE_E_OPEN" 222 "DEM222_PUMP_DRY_RUN" 223 "DEM223_PUMP_PERFORMANCE" 224 "DEM224_PUMP_LIN_FAILURE" 225 "DEM225_PUMP_SUPPLY_VOLTAGE" 226 "DEM226_PUMP_RECOVERY_FAIL" 227 "DEM227_CTR_POS_OPENED" 228 "DEM228_CTR_NEG_OPENED" 229 "DEM229_STRSET_SLAVE1_FAULT" 230 "DEM230_STRSET_SLAVE2_FAULT" 231 "DEM231_CTRSAUX_CLFAIL_HVON" 232 "DEM232_CTRSAUX_CLFAIL_VDIF" 233 "DEM233_CTRSAUX_POS1_OPENED" 234 "DEM234_CTRSAUX_NEG1_OPENED" 235 "DEM235_CTRSAUX_POS1_WELDED" 236 "DEM236_CTRSAUX_NEG1_WELDED" 237 "DEM237_CTRSAUX_POS1_PULLIN" 238 "DEM238_CTRSAUX_NEG1_PULLIN" 239 "DEM239_INLET_NTC_RATNAL" 240 "DEM240_INLET_NTC_HI" 241 "DEM241_INLET_NTC_LO" 242 "DEM242_VOLTAGE_LINK2_RATNA" 243 "DEM243_VOLTAGE_LINK2_HI" 244 "DEM244_VOLTAGE_LINK2_LO" 245 "DEM245_CMB_ONBOARD_IMPOSSI" 246 "DEM246_VOLTAGE_LINK1_HI" 247 "DEM247_VOLTAGE_LINK1_LO" 248 "DEM248_NTC_SUPPLY_LO" 249 "DEM249_NTC_SUPPLY_HI" 250 "DEM250_VOLTAGE_LINK3_RATNA" 251 "DEM251_VOLTAGE_LINK3_HI" 252 "DEM252_VOLTAGE_LINK3_LO" 253 "DEM253_BALANCING_STUCK" 254 "DEM254_ARM_EXCEPTION" 255 "DEM255_ERROR_HOOKS" 256 "DEM256_XCP_CAL_CHANGE" 257 "DEM257_XCP_CAL_PERM_CHANGE" 258 "DEM258_TASK_TIME_OVERFLOW" 259 "DEM259_ISO_CIRCUIT" 260 "DEM260_COOLANT_MOIST_FAULT" 261 "DEM261_COOLANT_FLOOD_WARN" 262 "DEM262_COOLANT_MOIST_WARN" 263 "DEM263_MODULET_IMPLAUSIBLE" 264 "DEM264_REQUEST_ON_WITH_HV_" 265 "DEM265_CSERS_PCODE" 266 "DEM266_PRELIM_CNTR_CL_FAIL" 267 "DEM267_FLUIDLVL_LOW" 268 "DEM268_FLUIDLVL_FAILURE" 269 "DEM269_SC_COOLANT_CONTAM" 270 "DEM270_SC_COOLANT_MIA" 271 "DEM271_PRESSURE_VHI" 272 "DEM272_PRESSURE_VLO" 273 "DEM273_SC_COOLANT_FAIL" 274 "DEM274_CTRSAUX_POS2_OPENED" 275 "DEM275_CTRSAUX_POS3_OPENED" 276 "DEM276_CTRSAUX_POS2_WELDED" 277 "DEM277_CTRSAUX_POS3_WELDED" 278 "DEM278_CTRSAUX_POS2_PULLIN" 279 "DEM279_CTRSAUX_POS3_PULLIN" 280 "DEM280_CMB_HUMIDITY_TEMP_C" 281 "DEM281_THERMAL_EVENT_CMB_R" 282 "DEM282_CUS_BRICKOV" 283 "DEM283_CUS_BRICKUV" 284 "DEM284_CUS_OVERCHRG" 285 "DEM285_CUS_OVERDCHRG" 286 "DEM286_CUS_CURRENT_CHG" 287 "DEM287_CUS_CURRENT_DCHG" ;
VAL_ 1048 DEM001_POWERUP_BMS25 3 "DEM_INVALID" 2 "DEM_FAILED" 1 "DEM_PASSED" 0 "DEM_NOTTESTED" ;
VAL_ 1048 DEM002_VOLTAGE_BRICK_OV_BMS25 3 "DEM_INVALID" 2 "DEM_FAILED" 1 "DEM_PASSED" 0 "DEM_NOTTESTED" ;
VAL_ 1048 DEM003_VOLTAGE_BRICK_UV_BMS25 3 "DEM_INVALID" 2 "DEM_FAILED" 1 "DEM_PASSED" 0 "DEM_NOTTESTED" ;
VAL_ 1048 DEM004_VOLTAGE_BRICK_SNA_BMS25 3 "DEM_INVALID" 2 "DEM_FAILED" 1 "DEM_PASSED" 0 "DEM_NOTTESTED" ;
VAL_ 1048 DEM005_VOLTAGE_BRICK_IMBAL_BMS25 3 "DEM_INVALID" 2 "DEM_FAILED" 1 "DEM_PASSED" 0 "DEM_NOTTESTED" ;
VAL_ 1048 DEM006_VOLTAGE_CAPCY_IMBAL_BMS25 3 "DEM_INVALID" 2 "DEM_FAILED" 1 "DEM_PASSED" 0 "DEM_NOTTESTED" ;
VAL_ 1048 DEM007_MODULET_HIGH_DELTA_BMS25 3 "DEM_INVALID" 2 "DEM_FAILED" 1 "DEM_PASSED" 0 "DEM_NOTTESTED" ;
VAL_ 1048 DEM008_VOLTAGE_PACK_UV_BMS25 3 "DEM_INVALID" 2 "DEM_FAILED" 1 "DEM_PASSED" 0 "DEM_NOTTESTED" ;
VAL_ 1048 DEM009_VOLTAGE_PACK_OV_BMS25 3 "DEM_INVALID" 2 "DEM_FAILED" 1 "DEM_PASSED" 0 "DEM_NOTTESTED" ;
VAL_ 1048 DEM010_VOLTAGE_PACK_PLAUSI_BMS25 3 "DEM_INVALID" 2 "DEM_FAILED" 1 "DEM_PASSED" 0 "DEM_NOTTESTED" ;
VAL_ 1048 DEM011_VOLTAGE_PCKLINK_MIS_BMS25 3 "DEM_INVALID" 2 "DEM_FAILED" 1 "DEM_PASSED" 0 "DEM_NOTTESTED" ;
VAL_ 1048 DEM012_VOLTAGE_BMS_SUPPLY_BMS25 3 "DEM_INVALID" 2 "DEM_FAILED" 1 "DEM_PASSED" 0 "DEM_NOTTESTED" ;
VAL_ 1048 DEM013_ADC_ERROR_BMS25 3 "DEM_INVALID" 2 "DEM_FAILED" 1 "DEM_PASSED" 0 "DEM_NOTTESTED" ;
VAL_ 1048 DEM014_MODULET_OT_BMS25 3 "DEM_INVALID" 2 "DEM_FAILED" 1 "DEM_PASSED" 0 "DEM_NOTTESTED" ;
VAL_ 1048 DEM015_MODULET_SNA_BMS25 3 "DEM_INVALID" 2 "DEM_FAILED" 1 "DEM_PASSED" 0 "DEM_NOTTESTED" ;
VAL_ 1048 DEM016_MODULET_LIMPHOME_BMS25 3 "DEM_INVALID" 2 "DEM_FAILED" 1 "DEM_PASSED" 0 "DEM_NOTTESTED" ;
VAL_ 1048 DEM017_COOLING_SYS_LHOME_BMS25 3 "DEM_INVALID" 2 "DEM_FAILED" 1 "DEM_PASSED" 0 "DEM_NOTTESTED" ;
VAL_ 1048 DEM018_HVIL_LIMPHOME_BMS25 3 "DEM_INVALID" 2 "DEM_FAILED" 1 "DEM_PASSED" 0 "DEM_NOTTESTED" ;
VAL_ 1048 DEM019_HVIL_ESS_INHIBIT_BMS25 3 "DEM_INVALID" 2 "DEM_FAILED" 1 "DEM_PASSED" 0 "DEM_NOTTESTED" ;
VAL_ 1048 DEM020_MODULET_CHANGE_BMS25 3 "DEM_INVALID" 2 "DEM_FAILED" 1 "DEM_PASSED" 0 "DEM_NOTTESTED" ;
VAL_ 1048 DEM021_LG_MAVD_FAULT_BMS25 3 "DEM_INVALID" 2 "DEM_FAILED" 1 "DEM_PASSED" 0 "DEM_NOTTESTED" ;
VAL_ 1048 DEM022_LG_RDV_FAULT_BMS25 3 "DEM_INVALID" 2 "DEM_FAILED" 1 "DEM_PASSED" 0 "DEM_NOTTESTED" ;
VAL_ 1048 DEM023_BMS_ONBOARDT_SNA_BMS25 3 "DEM_INVALID" 2 "DEM_FAILED" 1 "DEM_PASSED" 0 "DEM_NOTTESTED" ;
VAL_ 1048 DEM024_BMS_ONBOARDRH_OH_BMS25 3 "DEM_INVALID" 2 "DEM_FAILED" 1 "DEM_PASSED" 0 "DEM_NOTTESTED" ;
VAL_ 1048 DEM025_BMS_ONBOARDRH_SNA_BMS25 3 "DEM_INVALID" 2 "DEM_FAILED" 1 "DEM_PASSED" 0 "DEM_NOTTESTED" ;
VAL_ 1048 DEM026_CURRENT_OVERCHARGE_BMS25 3 "DEM_INVALID" 2 "DEM_FAILED" 1 "DEM_PASSED" 0 "DEM_NOTTESTED" ;
VAL_ 1048 DEM027_CURRENT_OVERDISCHGE_BMS25 3 "DEM_INVALID" 2 "DEM_FAILED" 1 "DEM_PASSED" 0 "DEM_NOTTESTED" ;
VAL_ 1048 DEM028_CURRENT_INVALID_BMS25 3 "DEM_INVALID" 2 "DEM_FAILED" 1 "DEM_PASSED" 0 "DEM_NOTTESTED" ;
VAL_ 1048 DEM029_CURRENT_SHORTCIRCT_BMS25 3 "DEM_INVALID" 2 "DEM_FAILED" 1 "DEM_PASSED" 0 "DEM_NOTTESTED" ;
VAL_ 1048 DEM030_CRASH_CAN_LATCH_BMS25 3 "DEM_INVALID" 2 "DEM_FAILED" 1 "DEM_PASSED" 0 "DEM_NOTTESTED" ;
VAL_ 1048 DEM031_EEPROM_FAIL_BMS25 3 "DEM_INVALID" 2 "DEM_FAILED" 1 "DEM_PASSED" 0 "DEM_NOTTESTED" ;
VAL_ 1112 DEM032_PCHG_PACKS_CONNECT_BMS25 3 "DEM_INVALID" 2 "DEM_FAILED" 1 "DEM_PASSED" 0 "DEM_NOTTESTED" ;
VAL_ 1112 DEM033_PCHG_ILLEGAL_PRCHG_BMS25 3 "DEM_INVALID" 2 "DEM_FAILED" 1 "DEM_PASSED" 0 "DEM_NOTTESTED" ;
VAL_ 1112 DEM034_PCHG_RELAY_FAIL_BMS25 3 "DEM_INVALID" 2 "DEM_FAILED" 1 "DEM_PASSED" 0 "DEM_NOTTESTED" ;
VAL_ 1112 DEM035_PCHG_NEG_WELD_BMS25 3 "DEM_INVALID" 2 "DEM_FAILED" 1 "DEM_PASSED" 0 "DEM_NOTTESTED" ;
VAL_ 1112 DEM036_PCHG_NEG_PULLIN_BMS25 3 "DEM_INVALID" 2 "DEM_FAILED" 1 "DEM_PASSED" 0 "DEM_NOTTESTED" ;
VAL_ 1112 DEM037_PCHG_SHORTCIRCUIT_BMS25 3 "DEM_INVALID" 2 "DEM_FAILED" 1 "DEM_PASSED" 0 "DEM_NOTTESTED" ;
VAL_ 1112 DEM038_PCHG_OPENCIRCUIT_BMS25 3 "DEM_INVALID" 2 "DEM_FAILED" 1 "DEM_PASSED" 0 "DEM_NOTTESTED" ;
VAL_ 1112 DEM039_PCHG_TIMEOUT_BMS25 3 "DEM_INVALID" 2 "DEM_FAILED" 1 "DEM_PASSED" 0 "DEM_NOTTESTED" ;
VAL_ 1112 DEM040_PCHG_FAILED_BMS25 3 "DEM_INVALID" 2 "DEM_FAILED" 1 "DEM_PASSED" 0 "DEM_NOTTESTED" ;
VAL_ 1112 DEM041_HVIL_SHUTDOWN_BMS25 3 "DEM_INVALID" 2 "DEM_FAILED" 1 "DEM_PASSED" 0 "DEM_NOTTESTED" ;
VAL_ 1112 DEM042_PCHG_POS_WELD_BMS25 3 "DEM_INVALID" 2 "DEM_FAILED" 1 "DEM_PASSED" 0 "DEM_NOTTESTED" ;
VAL_ 1112 DEM043_HV_LOCK_TRANSPORT_BMS25 3 "DEM_INVALID" 2 "DEM_FAILED" 1 "DEM_PASSED" 0 "DEM_NOTTESTED" ;
VAL_ 1112 DEM044_CTRS_END_OF_LIFE_BMS25 3 "DEM_INVALID" 2 "DEM_FAILED" 1 "DEM_PASSED" 0 "DEM_NOTTESTED" ;
VAL_ 1112 DEM045_CTRS_CTRPWRV_HI_BMS25 3 "DEM_INVALID" 2 "DEM_FAILED" 1 "DEM_PASSED" 0 "DEM_NOTTESTED" ;
VAL_ 1112 DEM046_CTRS_COILCURR_LOW_BMS25 3 "DEM_INVALID" 2 "DEM_FAILED" 1 "DEM_PASSED" 0 "DEM_NOTTESTED" ;
VAL_ 1112 DEM047_CTRS_COILCURR_HIGH_BMS25 3 "DEM_INVALID" 2 "DEM_FAILED" 1 "DEM_PASSED" 0 "DEM_NOTTESTED" ;
VAL_ 1112 DEM048_CTRS_CTRPWRV_LOW_BMS25 3 "DEM_INVALID" 2 "DEM_FAILED" 1 "DEM_PASSED" 0 "DEM_NOTTESTED" ;
VAL_ 1112 DEM049_CHGE_ILLEGAL_DISCHG_BMS25 3 "DEM_INVALID" 2 "DEM_FAILED" 1 "DEM_PASSED" 0 "DEM_NOTTESTED" ;
VAL_ 1112 DEM050_STARTUP_CONDITIONS_BMS25 3 "DEM_INVALID" 2 "DEM_FAILED" 1 "DEM_PASSED" 0 "DEM_NOTTESTED" ;
VAL_ 1112 DEM051_VOLTAGE_BMS_SUPPLYH_BMS25 3 "DEM_INVALID" 2 "DEM_FAILED" 1 "DEM_PASSED" 0 "DEM_NOTTESTED" ;
VAL_ 1112 DEM052_SAFETYSPI_FAIL_BMS25 3 "DEM_INVALID" 2 "DEM_FAILED" 1 "DEM_PASSED" 0 "DEM_NOTTESTED" ;
VAL_ 1112 DEM053_WATCHDOG_ERRORPIN_BMS25 3 "DEM_INVALID" 2 "DEM_FAILED" 1 "DEM_PASSED" 0 "DEM_NOTTESTED" ;
VAL_ 1112 DEM054_SAFESTATE_TRIGGERED_BMS25 3 "DEM_INVALID" 2 "DEM_FAILED" 1 "DEM_PASSED" 0 "DEM_NOTTESTED" ;
VAL_ 1112 DEM055_DEBUG_CMND_ACTIVE_BMS25 3 "DEM_INVALID" 2 "DEM_FAILED" 1 "DEM_PASSED" 0 "DEM_NOTTESTED" ;
VAL_ 1112 DEM056_CRASH_CAN_BMS25 3 "DEM_INVALID" 2 "DEM_FAILED" 1 "DEM_PASSED" 0 "DEM_NOTTESTED" ;
VAL_ 1112 DEM057_ISO_EXT_STRAT_4_BMS25 3 "DEM_INVALID" 2 "DEM_FAILED" 1 "DEM_PASSED" 0 "DEM_NOTTESTED" ;
VAL_ 1112 DEM058_ISO_EXT_RES_ERR_BMS25 3 "DEM_INVALID" 2 "DEM_FAILED" 1 "DEM_PASSED" 0 "DEM_NOTTESTED" ;
VAL_ 1112 DEM059_ISO_EXT_RES_WARN_BMS25 3 "DEM_INVALID" 2 "DEM_FAILED" 1 "DEM_PASSED" 0 "DEM_NOTTESTED" ;
VAL_ 1112 DEM060_ISO_INT_RES_ERR_BMS25 3 "DEM_INVALID" 2 "DEM_FAILED" 1 "DEM_PASSED" 0 "DEM_NOTTESTED" ;
VAL_ 1112 DEM061_ISO_INT_RES_WARN_BMS25 3 "DEM_INVALID" 2 "DEM_FAILED" 1 "DEM_PASSED" 0 "DEM_NOTTESTED" ;
VAL_ 1112 DEM062_EMERGENCY_OPERATION_BMS25 3 "DEM_INVALID" 2 "DEM_FAILED" 1 "DEM_PASSED" 0 "DEM_NOTTESTED" ;
VAL_ 1112 DEM063_ENDOFDRIVE_BMS25 3 "DEM_INVALID" 2 "DEM_FAILED" 1 "DEM_PASSED" 0 "DEM_NOTTESTED" ;
VAL_ 1176 DEM064_STRINGV_IMBALANCE_BMS25 3 "DEM_INVALID" 2 "DEM_FAILED" 1 "DEM_PASSED" 0 "DEM_NOTTESTED" ;
VAL_ 1176 DEM065_STRING_FAULT_BMS25 3 "DEM_INVALID" 2 "DEM_FAILED" 1 "DEM_PASSED" 0 "DEM_NOTTESTED" ;
VAL_ 1176 DEM066_ESS_FAULT_BMS25 3 "DEM_INVALID" 2 "DEM_FAILED" 1 "DEM_PASSED" 0 "DEM_NOTTESTED" ;
VAL_ 1176 DEM067_ISO_EXT_STRAT_3_BMS25 3 "DEM_INVALID" 2 "DEM_FAILED" 1 "DEM_PASSED" 0 "DEM_NOTTESTED" ;
VAL_ 1176 DEM068_MODULE_COUNT_INVALI_BMS25 3 "DEM_INVALID" 2 "DEM_FAILED" 1 "DEM_PASSED" 0 "DEM_NOTTESTED" ;
VAL_ 1176 DEM069_PT_MIA_BMS25 3 "DEM_INVALID" 2 "DEM_FAILED" 1 "DEM_PASSED" 0 "DEM_NOTTESTED" ;
VAL_ 1176 DEM070_BMSMIA_STRNGMSTR_01_BMS25 3 "DEM_INVALID" 2 "DEM_FAILED" 1 "DEM_PASSED" 0 "DEM_NOTTESTED" ;
VAL_ 1176 DEM071_BMSMIA_STRNGMSTR_05_BMS25 3 "DEM_INVALID" 2 "DEM_FAILED" 1 "DEM_PASSED" 0 "DEM_NOTTESTED" ;
VAL_ 1176 DEM072_BMSMIA_STRNGMSTR_09_BMS25 3 "DEM_INVALID" 2 "DEM_FAILED" 1 "DEM_PASSED" 0 "DEM_NOTTESTED" ;
VAL_ 1176 DEM073_BMSMIA_STRNGMSTR_13_BMS25 3 "DEM_INVALID" 2 "DEM_FAILED" 1 "DEM_PASSED" 0 "DEM_NOTTESTED" ;
VAL_ 1176 DEM074_BMSMIA_STRNGMSTR_17_BMS25 3 "DEM_INVALID" 2 "DEM_FAILED" 1 "DEM_PASSED" 0 "DEM_NOTTESTED" ;
VAL_ 1176 DEM075_BMSMIA_STRNGMSTR_21_BMS25 3 "DEM_INVALID" 2 "DEM_FAILED" 1 "DEM_PASSED" 0 "DEM_NOTTESTED" ;
VAL_ 1176 DEM076_BMSMIA_STRNGMSTR_25_BMS25 3 "DEM_INVALID" 2 "DEM_FAILED" 1 "DEM_PASSED" 0 "DEM_NOTTESTED" ;
VAL_ 1176 DEM077_BMSMIA_STRNGMSTR_29_BMS25 3 "DEM_INVALID" 2 "DEM_FAILED" 1 "DEM_PASSED" 0 "DEM_NOTTESTED" ;
VAL_ 1176 DEM078_BMSMIA_STRNGMSTR_33_BMS25 3 "DEM_INVALID" 2 "DEM_FAILED" 1 "DEM_PASSED" 0 "DEM_NOTTESTED" ;
VAL_ 1176 DEM079_BMSMIA_STRNGMSTR_37_BMS25 3 "DEM_INVALID" 2 "DEM_FAILED" 1 "DEM_PASSED" 0 "DEM_NOTTESTED" ;
VAL_ 1176 DEM080_BMSMIA_STRNGMSTR_41_BMS25 3 "DEM_INVALID" 2 "DEM_FAILED" 1 "DEM_PASSED" 0 "DEM_NOTTESTED" ;
VAL_ 1176 DEM081_BMSMIA_STRNGMSTR_45_BMS25 3 "DEM_INVALID" 2 "DEM_FAILED" 1 "DEM_PASSED" 0 "DEM_NOTTESTED" ;
VAL_ 1176 DEM082_BMSMIA_STRNGMSTR_49_BMS25 3 "DEM_INVALID" 2 "DEM_FAILED" 1 "DEM_PASSED" 0 "DEM_NOTTESTED" ;
VAL_ 1176 DEM083_BMSMIA_STRNGMSTR_53_BMS25 3 "DEM_INVALID" 2 "DEM_FAILED" 1 "DEM_PASSED" 0 "DEM_NOTTESTED" ;
VAL_ 1176 DEM084_BMSMIA_STRNGMSTR_57_BMS25 3 "DEM_INVALID" 2 "DEM_FAILED" 1 "DEM_PASSED" 0 "DEM_NOTTESTED" ;
VAL_ 1176 DEM085_BMSMIA_STRNGMSTR_61_BMS25 3 "DEM_INVALID" 2 "DEM_FAILED" 1 "DEM_PASSED" 0 "DEM_NOTTESTED" ;
VAL_ 1176 DEM086_ESSCURRENT_SHORT_BMS25 3 "DEM_INVALID" 2 "DEM_FAILED" 1 "DEM_PASSED" 0 "DEM_NOTTESTED" ;
VAL_ 1176 DEM087_PT_MIA_SHUTDOWN_BMS25 3 "DEM_INVALID" 2 "DEM_FAILED" 1 "DEM_PASSED" 0 "DEM_NOTTESTED" ;
VAL_ 1176 DEM088_OUTLET_NTC_HI_BMS25 3 "DEM_INVALID" 2 "DEM_FAILED" 1 "DEM_PASSED" 0 "DEM_NOTTESTED" ;
VAL_ 1176 DEM089_OUTLET_NTC_LO_BMS25 3 "DEM_INVALID" 2 "DEM_FAILED" 1 "DEM_PASSED" 0 "DEM_NOTTESTED" ;
VAL_ 1176 DEM090_BMSMIA_ESSMASTER_BMS25 3 "DEM_INVALID" 2 "DEM_FAILED" 1 "DEM_PASSED" 0 "DEM_NOTTESTED" ;
VAL_ 1176 DEM091_PCHG_RES_OVERHEAT_BMS25 3 "DEM_INVALID" 2 "DEM_FAILED" 1 "DEM_PASSED" 0 "DEM_NOTTESTED" ;
VAL_ 1176 DEM092_BMSMIA_STRNGSLAVE_0_BMS25 3 "DEM_INVALID" 2 "DEM_FAILED" 1 "DEM_PASSED" 0 "DEM_NOTTESTED" ;
VAL_ 1176 DEM093_BMSMIA_STRNGSLAVE_1_BMS25 3 "DEM_INVALID" 2 "DEM_FAILED" 1 "DEM_PASSED" 0 "DEM_NOTTESTED" ;
VAL_ 1176 DEM094_BMSMIA_STRNGSLAVE_2_BMS25 3 "DEM_INVALID" 2 "DEM_FAILED" 1 "DEM_PASSED" 0 "DEM_NOTTESTED" ;
VAL_ 1176 DEM095_BMSMIA_STRNGSLAVE_3_BMS25 3 "DEM_INVALID" 2 "DEM_FAILED" 1 "DEM_PASSED" 0 "DEM_NOTTESTED" ;
VAL_ 1240 DEM096_SC_STATE_SELFTEST_BMS25 3 "DEM_INVALID" 2 "DEM_FAILED" 1 "DEM_PASSED" 0 "DEM_NOTTESTED" ;
VAL_ 1240 DEM097_SC_STATE_TEMP_BMS25 3 "DEM_INVALID" 2 "DEM_FAILED" 1 "DEM_PASSED" 0 "DEM_NOTTESTED" ;
VAL_ 1240 DEM098_SC_STATE_VOLTAGE_BMS25 3 "DEM_INVALID" 2 "DEM_FAILED" 1 "DEM_PASSED" 0 "DEM_NOTTESTED" ;
VAL_ 1240 DEM099_SC_STATE_HVIL_BMS25 3 "DEM_INVALID" 2 "DEM_FAILED" 1 "DEM_PASSED" 0 "DEM_NOTTESTED" ;
VAL_ 1240 DEM100_SC_STATE_CONTACTORS_BMS25 3 "DEM_INVALID" 2 "DEM_FAILED" 1 "DEM_PASSED" 0 "DEM_NOTTESTED" ;
VAL_ 1240 DEM101_SC_STATE_CURRENT_BMS25 3 "DEM_INVALID" 2 "DEM_FAILED" 1 "DEM_PASSED" 0 "DEM_NOTTESTED" ;
VAL_ 1240 DEM102_SC_STATE_CANRX_BMS25 3 "DEM_INVALID" 2 "DEM_FAILED" 1 "DEM_PASSED" 0 "DEM_NOTTESTED" ;
VAL_ 1240 DEM103_SC_STATE_CRASH_BMS25 3 "DEM_INVALID" 2 "DEM_FAILED" 1 "DEM_PASSED" 0 "DEM_NOTTESTED" ;
VAL_ 1240 DEM104_SC_STATE_CCTRL_BMS25 3 "DEM_INVALID" 2 "DEM_FAILED" 1 "DEM_PASSED" 0 "DEM_NOTTESTED" ;
VAL_ 1240 DEM105_SC_STATE_CANTX_BMS25 3 "DEM_INVALID" 2 "DEM_FAILED" 1 "DEM_PASSED" 0 "DEM_NOTTESTED" ;
VAL_ 1240 DEM106_SC_STATE_THERMALEVT_BMS25 3 "DEM_INVALID" 2 "DEM_FAILED" 1 "DEM_PASSED" 0 "DEM_NOTTESTED" ;
VAL_ 1240 DEM107_SC_STATE_COOLANT_BMS25 3 "DEM_INVALID" 2 "DEM_FAILED" 1 "DEM_PASSED" 0 "DEM_NOTTESTED" ;
VAL_ 1240 DEM108_SC_SELFTEST_SFTY_UC_BMS25 3 "DEM_INVALID" 2 "DEM_FAILED" 1 "DEM_PASSED" 0 "DEM_NOTTESTED" ;
VAL_ 1240 DEM109_SC_TEMP_HIGH_BMS25 3 "DEM_INVALID" 2 "DEM_FAILED" 1 "DEM_PASSED" 0 "DEM_NOTTESTED" ;
VAL_ 1240 DEM110_SC_TEMP_NTC_OPEN_BMS25 3 "DEM_INVALID" 2 "DEM_FAILED" 1 "DEM_PASSED" 0 "DEM_NOTTESTED" ;
VAL_ 1240 DEM111_SC_TEMP_NTC_SHORT_BMS25 3 "DEM_INVALID" 2 "DEM_FAILED" 1 "DEM_PASSED" 0 "DEM_NOTTESTED" ;
VAL_ 1240 DEM112_CMB_DISCONNECTED_BMS25 3 "DEM_INVALID" 2 "DEM_FAILED" 1 "DEM_PASSED" 0 "DEM_NOTTESTED" ;
VAL_ 1240 DEM113_CMB_DEFECT_BMS25 3 "DEM_INVALID" 2 "DEM_FAILED" 1 "DEM_PASSED" 0 "DEM_NOTTESTED" ;
VAL_ 1240 DEM114_CMB_COMMERROR_BMS25 3 "DEM_INVALID" 2 "DEM_FAILED" 1 "DEM_PASSED" 0 "DEM_NOTTESTED" ;
VAL_ 1240 DEM115_SC_CURR_HALL_PWR_LO_BMS25 3 "DEM_INVALID" 2 "DEM_FAILED" 1 "DEM_PASSED" 0 "DEM_NOTTESTED" ;
VAL_ 1240 DEM116_SC_CURR_HALL_VHIGH_BMS25 3 "DEM_INVALID" 2 "DEM_FAILED" 1 "DEM_PASSED" 0 "DEM_NOTTESTED" ;
VAL_ 1240 DEM117_SC_CURR_HALL_ADC_BMS25 3 "DEM_INVALID" 2 "DEM_FAILED" 1 "DEM_PASSED" 0 "DEM_NOTTESTED" ;
VAL_ 1240 DEM118_SC_CURR_HALL_VLOW_BMS25 3 "DEM_INVALID" 2 "DEM_FAILED" 1 "DEM_PASSED" 0 "DEM_NOTTESTED" ;
VAL_ 1240 DEM119_SC_CURR_ISENSE_PWR_BMS25 3 "DEM_INVALID" 2 "DEM_FAILED" 1 "DEM_PASSED" 0 "DEM_NOTTESTED" ;
VAL_ 1240 DEM120_SC_CURR_ISENSE1_MIA_BMS25 3 "DEM_INVALID" 2 "DEM_FAILED" 1 "DEM_PASSED" 0 "DEM_NOTTESTED" ;
VAL_ 1240 DEM121_SC_CURR_ISENSE2_MIA_BMS25 3 "DEM_INVALID" 2 "DEM_FAILED" 1 "DEM_PASSED" 0 "DEM_NOTTESTED" ;
VAL_ 1240 DEM122_SC_CURR_ISENSE3_MIA_BMS25 3 "DEM_INVALID" 2 "DEM_FAILED" 1 "DEM_PASSED" 0 "DEM_NOTTESTED" ;
VAL_ 1240 DEM123_SC_CURR_ISENSE4_MIA_BMS25 3 "DEM_INVALID" 2 "DEM_FAILED" 1 "DEM_PASSED" 0 "DEM_NOTTESTED" ;
VAL_ 1240 DEM124_SC_CURR_ISENSE5_MIA_BMS25 3 "DEM_INVALID" 2 "DEM_FAILED" 1 "DEM_PASSED" 0 "DEM_NOTTESTED" ;
VAL_ 1240 DEM125_SC_CURR_ISENSE1_FLT_BMS25 3 "DEM_INVALID" 2 "DEM_FAILED" 1 "DEM_PASSED" 0 "DEM_NOTTESTED" ;
VAL_ 1240 DEM126_SC_CURR_ISENSE2_FLT_BMS25 3 "DEM_INVALID" 2 "DEM_FAILED" 1 "DEM_PASSED" 0 "DEM_NOTTESTED" ;
VAL_ 1240 DEM127_SC_CURR_ISENSE3_FLT_BMS25 3 "DEM_INVALID" 2 "DEM_FAILED" 1 "DEM_PASSED" 0 "DEM_NOTTESTED" ;
VAL_ 1304 DEM128_SC_CURR_ISENSE4_FLT_BMS25 3 "DEM_INVALID" 2 "DEM_FAILED" 1 "DEM_PASSED" 0 "DEM_NOTTESTED" ;
VAL_ 1304 DEM129_SC_CURR_ISENSE5_FLT_BMS25 3 "DEM_INVALID" 2 "DEM_FAILED" 1 "DEM_PASSED" 0 "DEM_NOTTESTED" ;
VAL_ 1304 DEM130_SC_CURR_OFFSET_BMS25 3 "DEM_INVALID" 2 "DEM_FAILED" 1 "DEM_PASSED" 0 "DEM_NOTTESTED" ;
VAL_ 1304 DEM131_SC_CURR_PLAUSI_BMS25 3 "DEM_INVALID" 2 "DEM_FAILED" 1 "DEM_PASSED" 0 "DEM_NOTTESTED" ;
VAL_ 1304 DEM132_SC_CURR_CHARGE_HIGH_BMS25 3 "DEM_INVALID" 2 "DEM_FAILED" 1 "DEM_PASSED" 0 "DEM_NOTTESTED" ;
VAL_ 1304 DEM133_SC_CURR_DSCHAR_HIGH_BMS25 3 "DEM_INVALID" 2 "DEM_FAILED" 1 "DEM_PASSED" 0 "DEM_NOTTESTED" ;
VAL_ 1304 DEM134_SC_V_CMB_SUMOFCELL_BMS25 3 "DEM_INVALID" 2 "DEM_FAILED" 1 "DEM_PASSED" 0 "DEM_NOTTESTED" ;
VAL_ 1304 DEM135_SC_V_SENSE_OPENWIRE_BMS25 3 "DEM_INVALID" 2 "DEM_FAILED" 1 "DEM_PASSED" 0 "DEM_NOTTESTED" ;
VAL_ 1304 DEM136_SC_V_CMB_DRV_FROZEN_BMS25 3 "DEM_INVALID" 2 "DEM_FAILED" 1 "DEM_PASSED" 0 "DEM_NOTTESTED" ;
VAL_ 1304 DEM137_SC_V_PACK_PLAUSI_BMS25 3 "DEM_INVALID" 2 "DEM_FAILED" 1 "DEM_PASSED" 0 "DEM_NOTTESTED" ;
VAL_ 1304 DEM138_SC_HVIL_HW_FLT_BMS25 3 "DEM_INVALID" 2 "DEM_FAILED" 1 "DEM_PASSED" 0 "DEM_NOTTESTED" ;
VAL_ 1304 DEM139_SC_HVIL_OPEN_BMS25 3 "DEM_INVALID" 2 "DEM_FAILED" 1 "DEM_PASSED" 0 "DEM_NOTTESTED" ;
VAL_ 1304 DEM140_SC_HVIL_TO_SUP_BMS25 3 "DEM_INVALID" 2 "DEM_FAILED" 1 "DEM_PASSED" 0 "DEM_NOTTESTED" ;
VAL_ 1304 DEM141_SC_HVIL_TO_CHAS_BMS25 3 "DEM_INVALID" 2 "DEM_FAILED" 1 "DEM_PASSED" 0 "DEM_NOTTESTED" ;
VAL_ 1304 DEM142_SC_HVIL_R_HIGH_BMS25 3 "DEM_INVALID" 2 "DEM_FAILED" 1 "DEM_PASSED" 0 "DEM_NOTTESTED" ;
VAL_ 1304 DEM143_SC_HVIL_SHORT_BMS25 3 "DEM_INVALID" 2 "DEM_FAILED" 1 "DEM_PASSED" 0 "DEM_NOTTESTED" ;
VAL_ 1304 DEM144_SC_CN_ISO_FAIL_BMS25 3 "DEM_INVALID" 2 "DEM_FAILED" 1 "DEM_PASSED" 0 "DEM_NOTTESTED" ;
VAL_ 1304 DEM145_HVIL_SYS_BMS25 3 "DEM_INVALID" 2 "DEM_FAILED" 1 "DEM_PASSED" 0 "DEM_NOTTESTED" ;
VAL_ 1304 DEM146_SC_CN_POS1_WELDED_BMS25 3 "DEM_INVALID" 2 "DEM_FAILED" 1 "DEM_PASSED" 0 "DEM_NOTTESTED" ;
VAL_ 1304 DEM147_SC_CN_NEG1_WELDED_BMS25 3 "DEM_INVALID" 2 "DEM_FAILED" 1 "DEM_PASSED" 0 "DEM_NOTTESTED" ;
VAL_ 1304 DEM148_SC_CN_POS2_WELDED_BMS25 3 "DEM_INVALID" 2 "DEM_FAILED" 1 "DEM_PASSED" 0 "DEM_NOTTESTED" ;
VAL_ 1304 DEM149_SC_CN_NEG2_WELDED_BMS25 3 "DEM_INVALID" 2 "DEM_FAILED" 1 "DEM_PASSED" 0 "DEM_NOTTESTED" ;
VAL_ 1304 DEM150_SC_CN_POS3_WELDED_BMS25 3 "DEM_INVALID" 2 "DEM_FAILED" 1 "DEM_PASSED" 0 "DEM_NOTTESTED" ;
VAL_ 1304 DEM151_SC_CN_NEG3_WELDED_BMS25 3 "DEM_INVALID" 2 "DEM_FAILED" 1 "DEM_PASSED" 0 "DEM_NOTTESTED" ;
VAL_ 1304 DEM152_SC_CN_HIGH_CY_BMS25 3 "DEM_INVALID" 2 "DEM_FAILED" 1 "DEM_PASSED" 0 "DEM_NOTTESTED" ;
VAL_ 1304 DEM153_SC_CN_ISOANDPOTWELD_BMS25 3 "DEM_INVALID" 2 "DEM_FAILED" 1 "DEM_PASSED" 0 "DEM_NOTTESTED" ;
VAL_ 1304 DEM154_SC_TEMP_PLAUSI_BMS25 3 "DEM_INVALID" 2 "DEM_FAILED" 1 "DEM_PASSED" 0 "DEM_NOTTESTED" ;
VAL_ 1304 DEM155_SC_CURR_HALL_PWR_HI_BMS25 3 "DEM_INVALID" 2 "DEM_FAILED" 1 "DEM_PASSED" 0 "DEM_NOTTESTED" ;
VAL_ 1304 DEM156_SC_PYRO_TRIGGERED_BMS25 3 "DEM_INVALID" 2 "DEM_FAILED" 1 "DEM_PASSED" 0 "DEM_NOTTESTED" ;
VAL_ 1304 DEM157_SC_PYRO_OPEN_BMS25 3 "DEM_INVALID" 2 "DEM_FAILED" 1 "DEM_PASSED" 0 "DEM_NOTTESTED" ;
VAL_ 1304 DEM158_AUX_CTRS_END_OF_LIF_BMS25 3 "DEM_INVALID" 2 "DEM_FAILED" 1 "DEM_PASSED" 0 "DEM_NOTTESTED" ;
VAL_ 1304 DEM159_SC_CANRX_PT_MIA_BMS25 3 "DEM_INVALID" 2 "DEM_FAILED" 1 "DEM_PASSED" 0 "DEM_NOTTESTED" ;
VAL_ 1368 DEM160_SC_CANRX_PT_CRCALIV_BMS25 3 "DEM_INVALID" 2 "DEM_FAILED" 1 "DEM_PASSED" 0 "DEM_NOTTESTED" ;
VAL_ 1368 DEM161_SC_CANRX_LIN_SHUTDN_BMS25 3 "DEM_INVALID" 2 "DEM_FAILED" 1 "DEM_PASSED" 0 "DEM_NOTTESTED" ;
VAL_ 1368 DEM162_SC_CANRX_LIN_MIA_BMS25 3 "DEM_INVALID" 2 "DEM_FAILED" 1 "DEM_PASSED" 0 "DEM_NOTTESTED" ;
VAL_ 1368 DEM163_SC_CRASH1_BMS25 3 "DEM_INVALID" 2 "DEM_FAILED" 1 "DEM_PASSED" 0 "DEM_NOTTESTED" ;
VAL_ 1368 DEM164_SC_CRASH2_BMS25 3 "DEM_INVALID" 2 "DEM_FAILED" 1 "DEM_PASSED" 0 "DEM_NOTTESTED" ;
VAL_ 1368 DEM165_SC_CRASHCAN_BMS25 3 "DEM_INVALID" 2 "DEM_FAILED" 1 "DEM_PASSED" 0 "DEM_NOTTESTED" ;
VAL_ 1368 DEM166_SC_CCTRL_SELFTEST_BMS25 3 "DEM_INVALID" 2 "DEM_FAILED" 1 "DEM_PASSED" 0 "DEM_NOTTESTED" ;
VAL_ 1368 DEM167_SC_CCTRL_DRIVER_FAU_BMS25 3 "DEM_INVALID" 2 "DEM_FAILED" 1 "DEM_PASSED" 0 "DEM_NOTTESTED" ;
VAL_ 1368 DEM168_SC_CCTRL_HISIDESTCL_BMS25 3 "DEM_INVALID" 2 "DEM_FAILED" 1 "DEM_PASSED" 0 "DEM_NOTTESTED" ;
VAL_ 1368 DEM169_SC_CCTRL_HISIDESTOP_BMS25 3 "DEM_INVALID" 2 "DEM_FAILED" 1 "DEM_PASSED" 0 "DEM_NOTTESTED" ;
VAL_ 1368 DEM170_SC_CCTRL_LOSIDESTCL_BMS25 3 "DEM_INVALID" 2 "DEM_FAILED" 1 "DEM_PASSED" 0 "DEM_NOTTESTED" ;
VAL_ 1368 DEM171_SC_CCTRL_HVCNDITION_BMS25 3 "DEM_INVALID" 2 "DEM_FAILED" 1 "DEM_PASSED" 0 "DEM_NOTTESTED" ;
VAL_ 1368 DEM172_SC_CCTRL_POS1_OPN_BMS25 3 "DEM_INVALID" 2 "DEM_FAILED" 1 "DEM_PASSED" 0 "DEM_NOTTESTED" ;
VAL_ 1368 DEM173_SC_CCTRL_POS2_OPN_BMS25 3 "DEM_INVALID" 2 "DEM_FAILED" 1 "DEM_PASSED" 0 "DEM_NOTTESTED" ;
VAL_ 1368 DEM174_SC_CCTRL_POS3_OPN_BMS25 3 "DEM_INVALID" 2 "DEM_FAILED" 1 "DEM_PASSED" 0 "DEM_NOTTESTED" ;
VAL_ 1368 DEM175_SC_CCTRL_NEG1_OPN_BMS25 3 "DEM_INVALID" 2 "DEM_FAILED" 1 "DEM_PASSED" 0 "DEM_NOTTESTED" ;
VAL_ 1368 DEM176_SC_CCTRL_NEG2_OPN_BMS25 3 "DEM_INVALID" 2 "DEM_FAILED" 1 "DEM_PASSED" 0 "DEM_NOTTESTED" ;
VAL_ 1368 DEM177_SC_CCTRL_PRE2_OPN_BMS25 3 "DEM_INVALID" 2 "DEM_FAILED" 1 "DEM_PASSED" 0 "DEM_NOTTESTED" ;
VAL_ 1368 DEM178_SC_CCTRL_PRE1_OPN_BMS25 3 "DEM_INVALID" 2 "DEM_FAILED" 1 "DEM_PASSED" 0 "DEM_NOTTESTED" ;
VAL_ 1368 DEM179_SC_CCTRL_LOSIDESTOP_BMS25 3 "DEM_INVALID" 2 "DEM_FAILED" 1 "DEM_PASSED" 0 "DEM_NOTTESTED" ;
VAL_ 1368 DEM180_SC_CCTRL_UNEXPECTED_BMS25 3 "DEM_INVALID" 2 "DEM_FAILED" 1 "DEM_PASSED" 0 "DEM_NOTTESTED" ;
VAL_ 1368 DEM181_SC_V_OUT_OF_RANGE_BMS25 3 "DEM_INVALID" 2 "DEM_FAILED" 1 "DEM_PASSED" 0 "DEM_NOTTESTED" ;
VAL_ 1368 DEM182_SC_V_LATCHED_UVOV_BMS25 3 "DEM_INVALID" 2 "DEM_FAILED" 1 "DEM_PASSED" 0 "DEM_NOTTESTED" ;
VAL_ 1368 DEM183_ISO_EXT_STRAT_2_BMS25 3 "DEM_INVALID" 2 "DEM_FAILED" 1 "DEM_PASSED" 0 "DEM_NOTTESTED" ;
VAL_ 1368 DEM184_SC_CANTX_CTRS_BMS25 3 "DEM_INVALID" 2 "DEM_FAILED" 1 "DEM_PASSED" 0 "DEM_NOTTESTED" ;
VAL_ 1368 DEM185_SC_CANTX_HVIL_BMS25 3 "DEM_INVALID" 2 "DEM_FAILED" 1 "DEM_PASSED" 0 "DEM_NOTTESTED" ;
VAL_ 1368 DEM186_SC_CANTX_ISOL_BMS25 3 "DEM_INVALID" 2 "DEM_FAILED" 1 "DEM_PASSED" 0 "DEM_NOTTESTED" ;
VAL_ 1368 DEM187_SC_SBC_WATCHDOG_BMS25 3 "DEM_INVALID" 2 "DEM_FAILED" 1 "DEM_PASSED" 0 "DEM_NOTTESTED" ;
VAL_ 1368 DEM188_SC_SBC_FAULT_BMS25 3 "DEM_INVALID" 2 "DEM_FAILED" 1 "DEM_PASSED" 0 "DEM_NOTTESTED" ;
VAL_ 1368 DEM189_SC_WATCHDOG_BMS25 3 "DEM_INVALID" 2 "DEM_FAILED" 1 "DEM_PASSED" 0 "DEM_NOTTESTED" ;
VAL_ 1368 DEM190_SC_SELFTEST_RAM_BMS25 3 "DEM_INVALID" 2 "DEM_FAILED" 1 "DEM_PASSED" 0 "DEM_NOTTESTED" ;
VAL_ 1368 DEM191_SC_SELFTEST_FLASH_BMS25 3 "DEM_INVALID" 2 "DEM_FAILED" 1 "DEM_PASSED" 0 "DEM_NOTTESTED" ;
VAL_ 1432 DEM192_CMB_ONBOARDRH_OH_BMS25 3 "DEM_INVALID" 2 "DEM_FAILED" 1 "DEM_PASSED" 0 "DEM_NOTTESTED" ;
VAL_ 1432 DEM193_CMB_ONBOARDRH_SNA_BMS25 3 "DEM_INVALID" 2 "DEM_FAILED" 1 "DEM_PASSED" 0 "DEM_NOTTESTED" ;
VAL_ 1432 DEM194_CMB_ONBOARDT_OT_BMS25 3 "DEM_INVALID" 2 "DEM_FAILED" 1 "DEM_PASSED" 0 "DEM_NOTTESTED" ;
VAL_ 1432 DEM195_CMB_ONBOARDT_CHANGE_BMS25 3 "DEM_INVALID" 2 "DEM_FAILED" 1 "DEM_PASSED" 0 "DEM_NOTTESTED" ;
VAL_ 1432 DEM196_PRESSURE_CHANGE_BMS25 3 "DEM_INVALID" 2 "DEM_FAILED" 1 "DEM_PASSED" 0 "DEM_NOTTESTED" ;
VAL_ 1432 DEM197_PRESSURE_OVER_BMS25 3 "DEM_INVALID" 2 "DEM_FAILED" 1 "DEM_PASSED" 0 "DEM_NOTTESTED" ;
VAL_ 1432 DEM198_PRESSURE_UNDER_BMS25 3 "DEM_INVALID" 2 "DEM_FAILED" 1 "DEM_PASSED" 0 "DEM_NOTTESTED" ;
VAL_ 1432 DEM199_PRESSURE_INVALID_BMS25 3 "DEM_INVALID" 2 "DEM_FAILED" 1 "DEM_PASSED" 0 "DEM_NOTTESTED" ;
VAL_ 1432 DEM200_THERMAL_EVENT_BMS25 3 "DEM_INVALID" 2 "DEM_FAILED" 1 "DEM_PASSED" 0 "DEM_NOTTESTED" ;
VAL_ 1432 DEM201_CMB_ONBOARDT_SNA_BMS25 3 "DEM_INVALID" 2 "DEM_FAILED" 1 "DEM_PASSED" 0 "DEM_NOTTESTED" ;
VAL_ 1432 DEM202_REPLACE_DESICCANT_BMS25 3 "DEM_INVALID" 2 "DEM_FAILED" 1 "DEM_PASSED" 0 "DEM_NOTTESTED" ;
VAL_ 1432 DEM203_COOLANT_FLOOD_FAULT_BMS25 3 "DEM_INVALID" 2 "DEM_FAILED" 1 "DEM_PASSED" 0 "DEM_NOTTESTED" ;
VAL_ 1432 DEM204_LOW_BRICKCAPACITY_BMS25 3 "DEM_INVALID" 2 "DEM_FAILED" 1 "DEM_PASSED" 0 "DEM_NOTTESTED" ;
VAL_ 1432 DEM205_BMS_ONBOARDT_OT_BMS25 3 "DEM_INVALID" 2 "DEM_FAILED" 1 "DEM_PASSED" 0 "DEM_NOTTESTED" ;
VAL_ 1432 DEM206_HUMIDITY_CHANGE_BMS25 3 "DEM_INVALID" 2 "DEM_FAILED" 1 "DEM_PASSED" 0 "DEM_NOTTESTED" ;
VAL_ 1432 DEM207_ISENSE_SUPPLY_CURR_BMS25 3 "DEM_INVALID" 2 "DEM_FAILED" 1 "DEM_PASSED" 0 "DEM_NOTTESTED" ;
VAL_ 1432 DEM208_SOC_LOW_BMS25 3 "DEM_INVALID" 2 "DEM_FAILED" 1 "DEM_PASSED" 0 "DEM_NOTTESTED" ;
VAL_ 1432 DEM209_SOC_TOOLOW_BMS25 3 "DEM_INVALID" 2 "DEM_FAILED" 1 "DEM_PASSED" 0 "DEM_NOTTESTED" ;
VAL_ 1432 DEM210_SOC_TOOHIGH_BMS25 3 "DEM_INVALID" 2 "DEM_FAILED" 1 "DEM_PASSED" 0 "DEM_NOTTESTED" ;
VAL_ 1432 DEM211_BALANCING_REQUIRED_BMS25 3 "DEM_INVALID" 2 "DEM_FAILED" 1 "DEM_PASSED" 0 "DEM_NOTTESTED" ;
VAL_ 1432 DEM212_DEEP_DISCHARGE_BMS25 3 "DEM_INVALID" 2 "DEM_FAILED" 1 "DEM_PASSED" 0 "DEM_NOTTESTED" ;
VAL_ 1432 DEM213_CAN1_BUS_OFF_BMS25 3 "DEM_INVALID" 2 "DEM_FAILED" 1 "DEM_PASSED" 0 "DEM_NOTTESTED" ;
VAL_ 1432 DEM214_CAN2_BUS_OFF_BMS25 3 "DEM_INVALID" 2 "DEM_FAILED" 1 "DEM_PASSED" 0 "DEM_NOTTESTED" ;
VAL_ 1432 DEM215_CAN3_BUS_OFF_BMS25 3 "DEM_INVALID" 2 "DEM_FAILED" 1 "DEM_PASSED" 0 "DEM_NOTTESTED" ;
VAL_ 1432 DEM216_OUTLET_NTC_RATNAL_BMS25 3 "DEM_INVALID" 2 "DEM_FAILED" 1 "DEM_PASSED" 0 "DEM_NOTTESTED" ;
VAL_ 1432 DEM217_FUSE_PACK_BMS25 3 "DEM_INVALID" 2 "DEM_FAILED" 1 "DEM_PASSED" 0 "DEM_NOTTESTED" ;
VAL_ 1432 DEM218_FUSE_B_OPEN_BMS25 3 "DEM_INVALID" 2 "DEM_FAILED" 1 "DEM_PASSED" 0 "DEM_NOTTESTED" ;
VAL_ 1432 DEM219_FUSE_C_OPEN_BMS25 3 "DEM_INVALID" 2 "DEM_FAILED" 1 "DEM_PASSED" 0 "DEM_NOTTESTED" ;
VAL_ 1432 DEM220_FUSE_D_OPEN_BMS25 3 "DEM_INVALID" 2 "DEM_FAILED" 1 "DEM_PASSED" 0 "DEM_NOTTESTED" ;
VAL_ 1432 DEM221_FUSE_E_OPEN_BMS25 3 "DEM_INVALID" 2 "DEM_FAILED" 1 "DEM_PASSED" 0 "DEM_NOTTESTED" ;
VAL_ 1432 DEM222_PUMP_DRY_RUN_BMS25 3 "DEM_INVALID" 2 "DEM_FAILED" 1 "DEM_PASSED" 0 "DEM_NOTTESTED" ;
VAL_ 1432 DEM223_PUMP_PERFORMANCE_BMS25 3 "DEM_INVALID" 2 "DEM_FAILED" 1 "DEM_PASSED" 0 "DEM_NOTTESTED" ;
VAL_ 1496 DEM224_PUMP_LIN_FAILURE_BMS25 3 "DEM_INVALID" 2 "DEM_FAILED" 1 "DEM_PASSED" 0 "DEM_NOTTESTED" ;
VAL_ 1496 DEM225_PUMP_SUPPLY_VOLTAGE_BMS25 3 "DEM_INVALID" 2 "DEM_FAILED" 1 "DEM_PASSED" 0 "DEM_NOTTESTED" ;
VAL_ 1496 DEM226_PUMP_RECOVERY_FAIL_BMS25 3 "DEM_INVALID" 2 "DEM_FAILED" 1 "DEM_PASSED" 0 "DEM_NOTTESTED" ;
VAL_ 1496 DEM227_CTR_POS_OPENED_BMS25 3 "DEM_INVALID" 2 "DEM_FAILED" 1 "DEM_PASSED" 0 "DEM_NOTTESTED" ;
VAL_ 1496 DEM228_CTR_NEG_OPENED_BMS25 3 "DEM_INVALID" 2 "DEM_FAILED" 1 "DEM_PASSED" 0 "DEM_NOTTESTED" ;
VAL_ 1496 DEM229_STRSET_SLAVE1_FAULT_BMS25 3 "DEM_INVALID" 2 "DEM_FAILED" 1 "DEM_PASSED" 0 "DEM_NOTTESTED" ;
VAL_ 1496 DEM230_STRSET_SLAVE2_FAULT_BMS25 3 "DEM_INVALID" 2 "DEM_FAILED" 1 "DEM_PASSED" 0 "DEM_NOTTESTED" ;
VAL_ 1496 DEM231_CTRSAUX_CLFAIL_HVON_BMS25 3 "DEM_INVALID" 2 "DEM_FAILED" 1 "DEM_PASSED" 0 "DEM_NOTTESTED" ;
VAL_ 1496 DEM232_CTRSAUX_CLFAIL_VDIF_BMS25 3 "DEM_INVALID" 2 "DEM_FAILED" 1 "DEM_PASSED" 0 "DEM_NOTTESTED" ;
VAL_ 1496 DEM233_CTRSAUX_POS1_OPENED_BMS25 3 "DEM_INVALID" 2 "DEM_FAILED" 1 "DEM_PASSED" 0 "DEM_NOTTESTED" ;
VAL_ 1496 DEM234_CTRSAUX_NEG1_OPENED_BMS25 3 "DEM_INVALID" 2 "DEM_FAILED" 1 "DEM_PASSED" 0 "DEM_NOTTESTED" ;
VAL_ 1496 DEM235_CTRSAUX_POS1_WELDED_BMS25 3 "DEM_INVALID" 2 "DEM_FAILED" 1 "DEM_PASSED" 0 "DEM_NOTTESTED" ;
VAL_ 1496 DEM236_CTRSAUX_NEG1_WELDED_BMS25 3 "DEM_INVALID" 2 "DEM_FAILED" 1 "DEM_PASSED" 0 "DEM_NOTTESTED" ;
VAL_ 1496 DEM237_CTRSAUX_POS1_PULLIN_BMS25 3 "DEM_INVALID" 2 "DEM_FAILED" 1 "DEM_PASSED" 0 "DEM_NOTTESTED" ;
VAL_ 1496 DEM238_CTRSAUX_NEG1_PULLIN_BMS25 3 "DEM_INVALID" 2 "DEM_FAILED" 1 "DEM_PASSED" 0 "DEM_NOTTESTED" ;
VAL_ 1496 DEM239_INLET_NTC_RATNAL_BMS25 3 "DEM_INVALID" 2 "DEM_FAILED" 1 "DEM_PASSED" 0 "DEM_NOTTESTED" ;
VAL_ 1496 DEM240_INLET_NTC_HI_BMS25 3 "DEM_INVALID" 2 "DEM_FAILED" 1 "DEM_PASSED" 0 "DEM_NOTTESTED" ;
VAL_ 1496 DEM241_INLET_NTC_LO_BMS25 3 "DEM_INVALID" 2 "DEM_FAILED" 1 "DEM_PASSED" 0 "DEM_NOTTESTED" ;
VAL_ 1496 DEM242_VOLTAGE_LINK2_RATNA_BMS25 3 "DEM_INVALID" 2 "DEM_FAILED" 1 "DEM_PASSED" 0 "DEM_NOTTESTED" ;
VAL_ 1496 DEM243_VOLTAGE_LINK2_HI_BMS25 3 "DEM_INVALID" 2 "DEM_FAILED" 1 "DEM_PASSED" 0 "DEM_NOTTESTED" ;
VAL_ 1496 DEM244_VOLTAGE_LINK2_LO_BMS25 3 "DEM_INVALID" 2 "DEM_FAILED" 1 "DEM_PASSED" 0 "DEM_NOTTESTED" ;
VAL_ 1496 DEM245_CMB_ONBOARD_IMPOSSI_BMS25 3 "DEM_INVALID" 2 "DEM_FAILED" 1 "DEM_PASSED" 0 "DEM_NOTTESTED" ;
VAL_ 1496 DEM246_VOLTAGE_LINK1_HI_BMS25 3 "DEM_INVALID" 2 "DEM_FAILED" 1 "DEM_PASSED" 0 "DEM_NOTTESTED" ;
VAL_ 1496 DEM247_VOLTAGE_LINK1_LO_BMS25 3 "DEM_INVALID" 2 "DEM_FAILED" 1 "DEM_PASSED" 0 "DEM_NOTTESTED" ;
VAL_ 1496 DEM248_NTC_SUPPLY_LO_BMS25 3 "DEM_INVALID" 2 "DEM_FAILED" 1 "DEM_PASSED" 0 "DEM_NOTTESTED" ;
VAL_ 1496 DEM249_NTC_SUPPLY_HI_BMS25 3 "DEM_INVALID" 2 "DEM_FAILED" 1 "DEM_PASSED" 0 "DEM_NOTTESTED" ;
VAL_ 1496 DEM250_VOLTAGE_LINK3_RATNA_BMS25 3 "DEM_INVALID" 2 "DEM_FAILED" 1 "DEM_PASSED" 0 "DEM_NOTTESTED" ;
VAL_ 1496 DEM251_VOLTAGE_LINK3_HI_BMS25 3 "DEM_INVALID" 2 "DEM_FAILED" 1 "DEM_PASSED" 0 "DEM_NOTTESTED" ;
VAL_ 1496 DEM252_VOLTAGE_LINK3_LO_BMS25 3 "DEM_INVALID" 2 "DEM_FAILED" 1 "DEM_PASSED" 0 "DEM_NOTTESTED" ;
VAL_ 1496 DEM253_BALANCING_STUCK_BMS25 3 "DEM_INVALID" 2 "DEM_FAILED" 1 "DEM_PASSED" 0 "DEM_NOTTESTED" ;
VAL_ 1496 DEM254_ARM_EXCEPTION_BMS25 3 "DEM_INVALID" 2 "DEM_FAILED" 1 "DEM_PASSED" 0 "DEM_NOTTESTED" ;
VAL_ 1496 DEM255_ERROR_HOOKS_BMS25 3 "DEM_INVALID" 2 "DEM_FAILED" 1 "DEM_PASSED" 0 "DEM_NOTTESTED" ;
VAL_ 856 DEM256_XCP_CAL_CHANGE_BMS25 3 "DEM_INVALID" 2 "DEM_FAILED" 1 "DEM_PASSED" 0 "DEM_NOTTESTED" ;
VAL_ 856 DEM257_XCP_CAL_PERM_CHANGE_BMS25 3 "DEM_INVALID" 2 "DEM_FAILED" 1 "DEM_PASSED" 0 "DEM_NOTTESTED" ;
VAL_ 856 DEM258_TASK_TIME_OVERFLOW_BMS25 3 "DEM_INVALID" 2 "DEM_FAILED" 1 "DEM_PASSED" 0 "DEM_NOTTESTED" ;
VAL_ 856 DEM259_ISO_CIRCUIT_BMS25 3 "DEM_INVALID" 2 "DEM_FAILED" 1 "DEM_PASSED" 0 "DEM_NOTTESTED" ;
VAL_ 856 DEM260_COOLANT_MOIST_FAULT_BMS25 3 "DEM_INVALID" 2 "DEM_FAILED" 1 "DEM_PASSED" 0 "DEM_NOTTESTED" ;
VAL_ 856 DEM261_COOLANT_FLOOD_WARN_BMS25 3 "DEM_INVALID" 2 "DEM_FAILED" 1 "DEM_PASSED" 0 "DEM_NOTTESTED" ;
VAL_ 856 DEM262_COOLANT_MOIST_WARN_BMS25 3 "DEM_INVALID" 2 "DEM_FAILED" 1 "DEM_PASSED" 0 "DEM_NOTTESTED" ;
VAL_ 856 DEM263_MODULET_IMPLAUSIBLE_BMS25 3 "DEM_INVALID" 2 "DEM_FAILED" 1 "DEM_PASSED" 0 "DEM_NOTTESTED" ;
VAL_ 856 DEM264_REQUEST_ON_WITH_HV__BMS25 3 "DEM_INVALID" 2 "DEM_FAILED" 1 "DEM_PASSED" 0 "DEM_NOTTESTED" ;
VAL_ 856 DEM265_CSERS_PCODE_BMS25 3 "DEM_INVALID" 2 "DEM_FAILED" 1 "DEM_PASSED" 0 "DEM_NOTTESTED" ;
VAL_ 856 DEM266_PRELIM_CNTR_CL_FAIL_BMS25 3 "DEM_INVALID" 2 "DEM_FAILED" 1 "DEM_PASSED" 0 "DEM_NOTTESTED" ;
VAL_ 856 DEM267_FLUIDLVL_LOW_BMS25 3 "DEM_INVALID" 2 "DEM_FAILED" 1 "DEM_PASSED" 0 "DEM_NOTTESTED" ;
VAL_ 856 DEM268_FLUIDLVL_FAILURE_BMS25 3 "DEM_INVALID" 2 "DEM_FAILED" 1 "DEM_PASSED" 0 "DEM_NOTTESTED" ;
VAL_ 856 DEM269_SC_COOLANT_CONTAM_BMS25 3 "DEM_INVALID" 2 "DEM_FAILED" 1 "DEM_PASSED" 0 "DEM_NOTTESTED" ;
VAL_ 856 DEM270_SC_COOLANT_MIA_BMS25 3 "DEM_INVALID" 2 "DEM_FAILED" 1 "DEM_PASSED" 0 "DEM_NOTTESTED" ;
VAL_ 856 DEM271_PRESSURE_VHI_BMS25 3 "DEM_INVALID" 2 "DEM_FAILED" 1 "DEM_PASSED" 0 "DEM_NOTTESTED" ;
VAL_ 856 DEM272_PRESSURE_VLO_BMS25 3 "DEM_INVALID" 2 "DEM_FAILED" 1 "DEM_PASSED" 0 "DEM_NOTTESTED" ;
VAL_ 856 DEM273_SC_COOLANT_FAIL_BMS25 3 "DEM_INVALID" 2 "DEM_FAILED" 1 "DEM_PASSED" 0 "DEM_NOTTESTED" ;
VAL_ 856 DEM274_CTRSAUX_POS2_OPENED_BMS25 3 "DEM_INVALID" 2 "DEM_FAILED" 1 "DEM_PASSED" 0 "DEM_NOTTESTED" ;
VAL_ 856 DEM275_CTRSAUX_POS3_OPENED_BMS25 3 "DEM_INVALID" 2 "DEM_FAILED" 1 "DEM_PASSED" 0 "DEM_NOTTESTED" ;
VAL_ 856 DEM276_CTRSAUX_POS2_WELDED_BMS25 3 "DEM_INVALID" 2 "DEM_FAILED" 1 "DEM_PASSED" 0 "DEM_NOTTESTED" ;
VAL_ 856 DEM277_CTRSAUX_POS3_WELDED_BMS25 3 "DEM_INVALID" 2 "DEM_FAILED" 1 "DEM_PASSED" 0 "DEM_NOTTESTED" ;
VAL_ 856 DEM278_CTRSAUX_POS2_PULLIN_BMS25 3 "DEM_INVALID" 2 "DEM_FAILED" 1 "DEM_PASSED" 0 "DEM_NOTTESTED" ;
VAL_ 856 DEM279_CTRSAUX_POS3_PULLIN_BMS25 3 "DEM_INVALID" 2 "DEM_FAILED" 1 "DEM_PASSED" 0 "DEM_NOTTESTED" ;
VAL_ 856 DEM280_CMB_HUMIDITY_TEMP_C_BMS25 3 "DEM_INVALID" 2 "DEM_FAILED" 1 "DEM_PASSED" 0 "DEM_NOTTESTED" ;
VAL_ 856 DEM281_THERMAL_EVENT_CMB_R_BMS25 3 "DEM_INVALID" 2 "DEM_FAILED" 1 "DEM_PASSED" 0 "DEM_NOTTESTED" ;
VAL_ 856 DEM282_CUS_BRICKOV_BMS25 3 "DEM_INVALID" 2 "DEM_FAILED" 1 "DEM_PASSED" 0 "DEM_NOTTESTED" ;
VAL_ 856 DEM283_CUS_BRICKUV_BMS25 3 "DEM_INVALID" 2 "DEM_FAILED" 1 "DEM_PASSED" 0 "DEM_NOTTESTED" ;
VAL_ 856 DEM284_CUS_OVERCHRG_BMS25 3 "DEM_INVALID" 2 "DEM_FAILED" 1 "DEM_PASSED" 0 "DEM_NOTTESTED" ;
VAL_ 856 DEM285_CUS_OVERDCHRG_BMS25 3 "DEM_INVALID" 2 "DEM_FAILED" 1 "DEM_PASSED" 0 "DEM_NOTTESTED" ;
VAL_ 856 DEM286_CUS_CURRENT_CHG_BMS25 3 "DEM_INVALID" 2 "DEM_FAILED" 1 "DEM_PASSED" 0 "DEM_NOTTESTED" ;
VAL_ 856 DEM287_CUS_CURRENT_DCHG_BMS25 3 "DEM_INVALID" 2 "DEM_FAILED" 1 "DEM_PASSED" 0 "DEM_NOTTESTED" ;
